VERSION "eCMPilot HS1 database-first 2026-10-28; PSA-RE 67f7581e7622410efdbb29c7eda3b86982b9b450; Apache-2.0"

NS_ :

BS_:

BU_: AAS ABS ARTIV AVAS BCP BSI BSM BVA CAV CMM CSS CVM DAE DMTR ESM E_VCU HCU1 HCU2 LVNSD MCM MDS RBG SBW VCU

BO_ 166 E_VCU_WheelPulseCounters: 2 E_VCU
 SG_ ImmoEcuState : 15|8@0+ (1,0) [0|255] ""  BSI
 SG_ ImmoLocalIdMcuBsi : 7|8@0+ (1,0) [0|255] ""  BSI

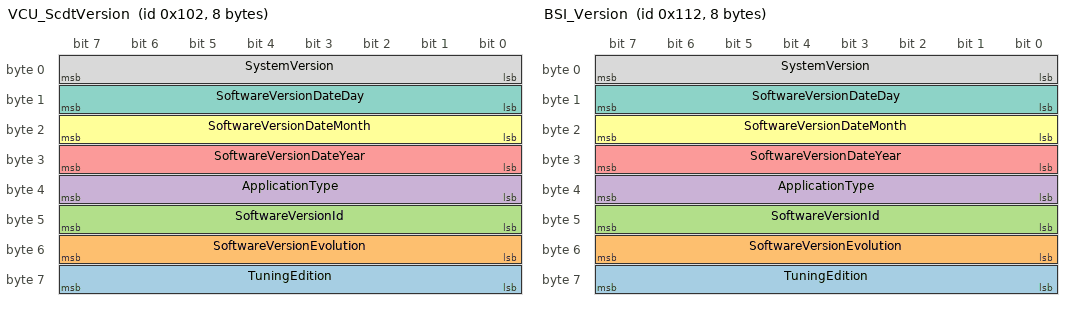
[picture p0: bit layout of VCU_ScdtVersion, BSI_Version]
BO_ 258 VCU_ScdtVersion: 8 VCU
 SG_ TuningEdition : 63|8@0+ (1,0) [0|255] "" Vector__XXX
 SG_ SoftwareVersionEvolution : 55|8@0+ (1,0) [0|255] "" Vector__XXX
 SG_ SoftwareVersionId : 47|8@0+ (1,0) [0|255] "" Vector__XXX
 SG_ ApplicationType : 39|8@0+ (1,0) [0|255] "" Vector__XXX
 SG_ SoftwareVersionDateYear : 31|8@0+ (1,0) [0|99] "" Vector__XXX
 SG_ SoftwareVersionDateMonth : 23|8@0+ (1,0) [0|12] "" Vector__XXX
 SG_ SoftwareVersionDateDay : 15|8@0+ (1,0) [0|31] "" Vector__XXX
 SG_ SystemVersion : 7|8@0+ (1,0) [0|255] "" Vector__XXX

BO_ 274 BSI_Version: 8 BSI
 SG_ TuningEdition : 63|8@0+ (1,0) [0|255] "" Vector__XXX
 SG_ SoftwareVersionEvolution : 55|8@0+ (1,0) [0|255] "" Vector__XXX
 SG_ SoftwareVersionId : 47|8@0+ (1,0) [0|255] "" Vector__XXX
 SG_ ApplicationType : 39|8@0+ (1,0) [0|255] "" Vector__XXX
 SG_ SoftwareVersionDateYear : 31|8@0+ (1,0) [0|99] "" Vector__XXX
 SG_ SoftwareVersionDateMonth : 23|8@0+ (1,0) [0|12] "" Vector__XXX
 SG_ SoftwareVersionDateDay : 15|8@0+ (1,0) [0|31] "" Vector__XXX
 SG_ SystemVersion : 7|8@0+ (1,0) [0|255] "" Vector__XXX

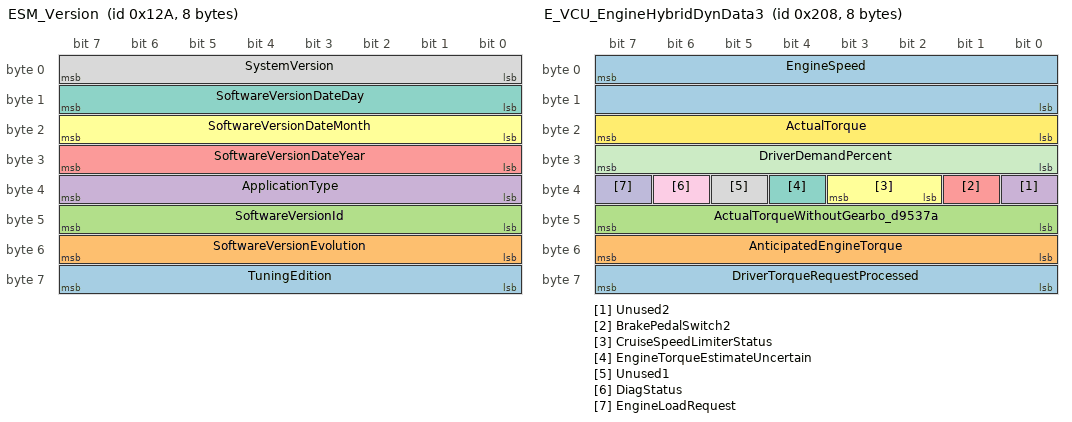
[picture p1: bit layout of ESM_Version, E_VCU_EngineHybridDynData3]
BO_ 298 ESM_Version: 8 ESM
 SG_ TuningEdition : 63|8@0+ (1,0) [0|255] "" Vector__XXX
 SG_ SoftwareVersionEvolution : 55|8@0+ (1,0) [0|255] "" Vector__XXX
 SG_ SoftwareVersionId : 47|8@0+ (1,0) [0|255] "" Vector__XXX
 SG_ ApplicationType : 39|8@0+ (1,0) [0|255] "" Vector__XXX
 SG_ SoftwareVersionDateYear : 31|8@0+ (1,0) [0|99] "" Vector__XXX
 SG_ SoftwareVersionDateMonth : 23|8@0+ (1,0) [0|12] "" Vector__XXX
 SG_ SoftwareVersionDateDay : 15|8@0+ (1,0) [0|31] "" Vector__XXX
 SG_ SystemVersion : 7|8@0+ (1,0) [0|255] "" Vector__XXX

BO_ 520 E_VCU_EngineHybridDynData3: 8 E_VCU
 SG_ DriverTorqueRequestProcessed : 63|8@0+ (2,-100) [-100|408] "Nm"  BVA,BSI,AAS,CVM,DMTR,ABS,DAE,SBW,BCP,CSS,CAV,MDS
 SG_ AnticipatedEngineTorque : 55|8@0+ (2,-100) [-100|408] "Nm"  BVA,BSI,AAS,CVM,DMTR,ABS,DAE,SBW,BCP,CSS,CAV,MDS
 SG_ ActualTorqueWithoutGearbo_d9537a : 47|8@0+ (2,-100) [-100|408] "Nm"  BVA,BSI,AAS,CVM,DMTR,ABS,DAE,SBW,BCP,CSS,CAV,MDS
 SG_ Unused2 : 32|1@0+ (1,0) [0|1] ""  BVA,BSI,AAS,CVM,DMTR,ABS,DAE,SBW,BCP,CSS,CAV,MDS
 SG_ BrakePedalSwitch2 : 33|1@0+ (1,0) [0|1] ""  BVA,BSI,AAS,CVM,DMTR,ABS,DAE,SBW,BCP,CSS,CAV,MDS
 SG_ CruiseSpeedLimiterStatus : 35|2@0+ (1,0) [0|3] ""  BVA,BSI,AAS,CVM,DMTR,ABS,DAE,SBW,BCP,CSS,CAV,MDS
 SG_ EngineTorqueEstimateUncertain : 36|1@0+ (1,0) [0|1] ""  BVA,BSI,AAS,CVM,DMTR,ABS,DAE,SBW,BCP,CSS,CAV,MDS
 SG_ Unused1 : 37|1@0+ (1,0) [0|1] ""  BVA,BSI,AAS,CVM,DMTR,ABS,DAE,SBW,BCP,CSS,CAV,MDS
 SG_ DiagStatus : 38|1@0+ (1,0) [0|1] ""  BVA,BSI,AAS,CVM,DMTR,ABS,DAE,SBW,BCP,CSS,CAV,MDS
 SG_ EngineLoadRequest : 39|1@0+ (1,0) [0|1] ""  BVA,BSI,AAS,CVM,DMTR,ABS,DAE,SBW,BCP,CSS,CAV,MDS
 SG_ DriverDemandPercent : 31|8@0+ (0.5,0) [0|100] "%"  BVA,BSI,AAS,CVM,DMTR,ABS,DAE,SBW,BCP,CSS,CAV,MDS
 SG_ ActualTorque : 23|8@0+ (2,-100) [-100|408] "Nm"  BVA,BSI,AAS,CVM,DMTR,ABS,DAE,SBW,BCP,CSS,CAV,MDS
 SG_ EngineSpeed : 7|16@0+ (0.125,0) [0|8191.75] "rpm"  BVA,BSI,AAS,CVM,DMTR,ABS,DAE,SBW,BCP,CSS,CAV,MDS

BO_ 602 Unknown_Message01: 2 Vector__XXX
 SG_ RawByte2 : 15|8@0+ (1,0) [0|255] "raw" Vector__XXX
 SG_ RawByte1 : 7|8@0+ (1,0) [0|255] "raw" Vector__XXX

BO_ 610 VCU_PowertrainState2: 1 VCU
 SG_ Unused1 : 3|4@0+ (1,0) [0|15] ""  AAS,CSS,BSI,LVNSD,MDS
 SG_ PowertrainState : 7|4@0+ (1,0) [0|15] ""  AAS,CSS,BSI,LVNSD,MDS

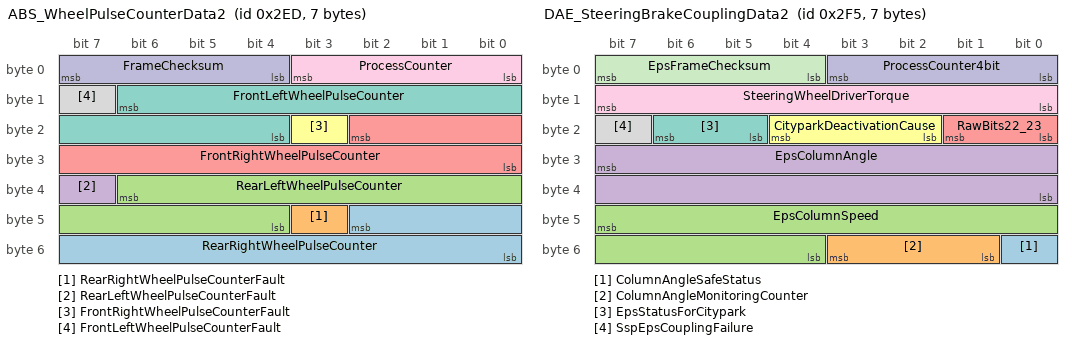
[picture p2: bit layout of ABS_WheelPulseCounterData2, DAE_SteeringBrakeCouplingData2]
BO_ 749 ABS_WheelPulseCounterData2: 7 ABS
 SG_ RearRightWheelPulseCounter : 42|11@0+ (1,0) [0|2047] ""  CVM,AAS,BSI
 SG_ RearRightWheelPulseCounterFault : 43|1@0+ (1,0) [0|1] ""  CVM,AAS,BSI
 SG_ RearLeftWheelPulseCounter : 38|11@0+ (1,0) [0|2047] ""  CVM,AAS,BSI
 SG_ RearLeftWheelPulseCounterFault : 39|1@0+ (1,0) [0|1] ""  CVM,AAS,BSI
 SG_ FrontRightWheelPulseCounter : 18|11@0+ (1,0) [0|2047] ""  CVM,AAS,BSI
 SG_ FrontRightWheelPulseCounterFault : 19|1@0+ (1,0) [0|1] ""  CVM,AAS,BSI
 SG_ FrontLeftWheelPulseCounter : 14|11@0+ (1,0) [0|2047] ""  CVM,AAS,BSI
 SG_ FrontLeftWheelPulseCounterFault : 15|1@0+ (1,0) [0|1] ""  CVM,AAS,BSI
 SG_ ProcessCounter : 3|4@0+ (1,0) [0|15] ""  CVM,AAS,BSI
 SG_ FrameChecksum : 7|4@0+ (1,0) [0|15] ""  CVM,AAS,BSI

BO_ 757 DAE_SteeringBrakeCouplingData2: 7 DAE
 SG_ ColumnAngleSafeStatus : 48|1@0+ (1,0) [0|1] ""  ABS,AAS,BSI
 SG_ ColumnAngleMonitoringCounter : 51|3@0+ (1,0) [0|7] ""  ABS,AAS,BSI
 SG_ EpsColumnSpeed : 47|12@0- (1,0) [-2000|2000] "°/s"  ABS,AAS,BSI
 SG_ EpsColumnAngle : 31|16@0- (0.1,0) [-1630|1630] "°"  ABS,AAS,BSI
 SG_ RawBits22_23 : 17|2@0+ (1,0) [0|3] "raw"  ABS,AAS,BSI
 SG_ CityparkDeactivationCause : 20|3@0+ (1,0) [0|7] ""  ABS,AAS,BSI
 SG_ EpsStatusForCitypark : 22|2@0+ (1,0) [0|3] ""  ABS,AAS,BSI
 SG_ SspEpsCouplingFailure : 23|1@0+ (1,0) [0|1] ""  ABS,AAS,BSI
 SG_ SteeringWheelDriverTorque : 15|8@0- (0.1,0) [-10|10] "Nm"  ABS,AAS,BSI
 SG_ ProcessCounter4bit : 3|4@0+ (1,0) [0|15] ""  ABS,AAS,BSI
 SG_ EpsFrameChecksum : 7|4@0+ (1,0) [0|15] ""  ABS,AAS,BSI

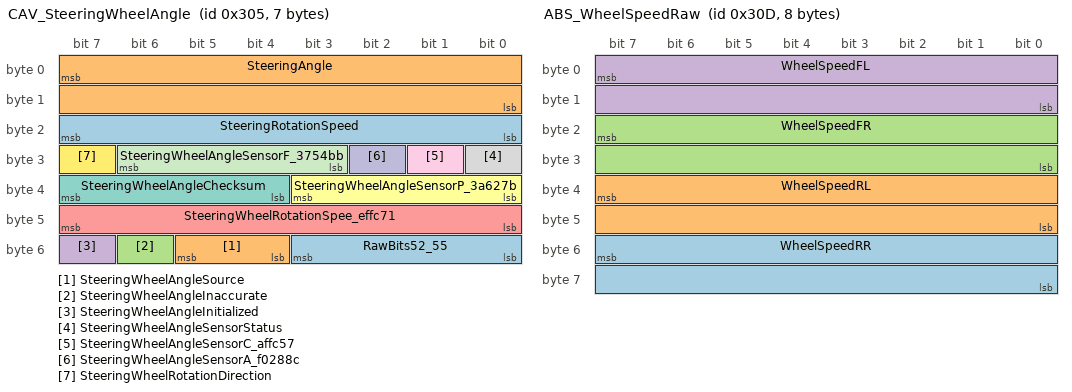
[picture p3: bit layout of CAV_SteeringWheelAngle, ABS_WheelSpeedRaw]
BO_ 773 CAV_SteeringWheelAngle: 7 CAV
 SG_ RawBits52_55 : 51|4@0+ (1,0) [0|15] "raw"  BCP,CVM,ABS,DAE,AAS,BSI,BVA,CMM,BSM,E_VCU
 SG_ SteeringWheelAngleSource : 53|2@0+ (1,0) [0|3] ""  BCP,CVM,ABS,DAE,AAS,BSI,BVA,CMM,BSM,E_VCU
 SG_ SteeringWheelAngleInaccurate : 54|1@0+ (1,0) [0|1] ""  BCP,CVM,ABS,DAE,AAS,BSI,BVA,CMM,BSM,E_VCU
 SG_ SteeringWheelAngleInitialized : 55|1@0+ (1,0) [0|1] ""  BCP,CVM,ABS,DAE,AAS,BSI,BVA,CMM,BSM,E_VCU
 SG_ SteeringWheelRotationSpee_effc71 : 47|8@0+ (4,0) [0|1016] "°/s"  BCP,CVM,ABS,DAE,AAS,BSI,BVA,CMM,BSM,E_VCU
 SG_ SteeringWheelAngleSensorP_3a627b : 35|4@0+ (1,0) [0|15] ""  BCP,CVM,ABS,DAE,AAS,BSI,BVA,CMM,BSM,E_VCU
 SG_ SteeringWheelAngleChecksum : 39|4@0+ (1,0) [0|15] ""  BCP,CVM,ABS,DAE,AAS,BSI,BVA,CMM,BSM,E_VCU
 SG_ SteeringWheelAngleSensorStatus : 24|1@0+ (1,0) [0|1] ""  BCP,CVM,ABS,DAE,AAS,BSI,BVA,CMM,BSM,E_VCU
 SG_ SteeringWheelAngleSensorC_affc57 : 25|1@0+ (1,0) [0|1] ""  BCP,CVM,ABS,DAE,AAS,BSI,BVA,CMM,BSM,E_VCU
 SG_ SteeringWheelAngleSensorA_f0288c : 26|1@0+ (1,0) [0|1] ""  BCP,CVM,ABS,DAE,AAS,BSI,BVA,CMM,BSM,E_VCU
 SG_ SteeringWheelAngleSensorF_3754bb : 30|4@0+ (1,0) [0|15] ""  BCP,CVM,ABS,DAE,AAS,BSI,BVA,CMM,BSM,E_VCU
 SG_ SteeringWheelRotationDirection : 31|1@0+ (1,0) [0|1] ""  BCP,CVM,ABS,DAE,AAS,BSI,BVA,CMM,BSM,E_VCU
 SG_ SteeringRotationSpeed : 23|8@0+ (4,0) [0|1016] "°/s"  BCP,CVM,ABS,DAE,AAS,BSI,BVA,CMM,BSM,E_VCU
 SG_ SteeringAngle : 7|16@0- (0.1,0) [-780|780] "°"  BCP,CVM,ABS,DAE,AAS,BSI,BVA,CMM,BSM,E_VCU

BO_ 781 ABS_WheelSpeedRaw: 8 ABS
 SG_ WheelSpeedRR : 55|16@0+ (0.01,0) [0|655.33] "km/h"  CVM,AAS,CMM,BVA,HCU1,BSM,DAE,VCU
 SG_ WheelSpeedRL : 39|16@0+ (0.01,0) [0|655.33] "km/h"  CVM,AAS,CMM,BVA,HCU1,BSM,DAE,VCU
 SG_ WheelSpeedFR : 23|16@0+ (0.01,0) [0|655.33] "km/h"  CVM,AAS,CMM,BVA,HCU1,BSM,DAE,VCU
 SG_ WheelSpeedFL : 7|16@0+ (0.01,0) [0|655.33] "km/h"  CVM,AAS,CMM,BVA,HCU1,BSM,DAE,VCU

BO_ 820 E_VCU_BattCellVoltages: 8 E_VCU
 SG_ RawByte8_Mux27_28_29_30_31 m27 : 63|8@0+ (1,0) [0|255] "raw"  BSI,MDS
 SG_ CellVoltage044 m10 : 53|14@0+ (0.001,0) [0|15] "V"  BSI,MDS
 SG_ CellVoltage040 m9 : 53|14@0+ (0.001,0) [0|15] "V"  BSI,MDS
 SG_ CellVoltage092 m22 : 53|14@0+ (0.001,0) [0|15] "V"  BSI,MDS
 SG_ CellVoltage020 m4 : 53|14@0+ (0.001,0) [0|15] "V"  BSI,MDS
 SG_ CellVoltage088 m21 : 53|14@0+ (0.001,0) [0|15] "V"  BSI,MDS
 SG_ CellVoltage108 m26 : 53|14@0+ (0.001,0) [0|15] "V"  BSI,MDS
 SG_ CellVoltage104 m25 : 53|14@0+ (0.001,0) [0|15] "V"  BSI,MDS
 SG_ CellVoltage068 m16 : 53|14@0+ (0.001,0) [0|15] "V"  BSI,MDS
 SG_ CellVoltage064 m15 : 53|14@0+ (0.001,0) [0|15] "V"  BSI,MDS
 SG_ CellVoltage016 m3 : 53|14@0+ (0.001,0) [0|15] "V"  BSI,MDS
 SG_ CellVoltage072 m17 : 53|14@0+ (0.001,0) [0|15] "V"  BSI,MDS
 SG_ CellVoltage060 m14 : 53|14@0+ (0.001,0) [0|15] "V"  BSI,MDS
 SG_ CellVoltage056 m13 : 53|14@0+ (0.001,0) [0|15] "V"  BSI,MDS
 SG_ CellVoltage084 m20 : 53|14@0+ (0.001,0) [0|15] "V"  BSI,MDS
 SG_ CellVoltage004 m0 : 53|14@0+ (0.001,0) [0|15] "V"  BSI,MDS
 SG_ CellVoltage052 m12 : 53|14@0+ (0.001,0) [0|15] "V"  BSI,MDS
 SG_ CellVoltage012 m2 : 53|14@0+ (0.001,0) [0|15] "V"  BSI,MDS
 SG_ CellVoltage008 m1 : 53|14@0+ (0.001,0) [0|15] "V"  BSI,MDS
 SG_ CellVoltage048 m11 : 53|14@0+ (0.001,0) [0|15] "V"  BSI,MDS
 SG_ CellVoltage080 m19 : 53|14@0+ (0.001,0) [0|15] "V"  BSI,MDS
 SG_ CellVoltage036 m8 : 53|14@0+ (0.001,0) [0|15] "V"  BSI,MDS
 SG_ CellVoltage076 m18 : 53|14@0+ (0.001,0) [0|15] "V"  BSI,MDS
 SG_ CellVoltage100 m24 : 53|14@0+ (0.001,0) [0|15] "V"  BSI,MDS
 SG_ CellVoltage096 m23 : 53|14@0+ (0.001,0) [0|15] "V"  BSI,MDS
 SG_ CellVoltage032 m7 : 53|14@0+ (0.001,0) [0|15] "V"  BSI,MDS
 SG_ CellVoltage028 m6 : 53|14@0+ (0.001,0) [0|15] "V"  BSI,MDS
 SG_ CellVoltage024 m5 : 53|14@0+ (0.001,0) [0|15] "V"  BSI,MDS
 SG_ RawByte7_Mux27_28_29_30_31 m27 : 55|8@0+ (1,0) [0|255] "raw"  BSI,MDS
 SG_ RawByte6_Mux27_28_29_30_31 m27 : 47|8@0+ (1,0) [0|255] "raw"  BSI,MDS
 SG_ CellVoltage031 m7 : 35|14@0+ (0.001,0) [0|15] "V"  BSI,MDS
 SG_ CellVoltage043 m10 : 35|14@0+ (0.001,0) [0|15] "V"  BSI,MDS
 SG_ CellVoltage091 m22 : 35|14@0+ (0.001,0) [0|15] "V"  BSI,MDS
 SG_ CellVoltage019 m4 : 35|14@0+ (0.001,0) [0|15] "V"  BSI,MDS
 SG_ CellVoltage087 m21 : 35|14@0+ (0.001,0) [0|15] "V"  BSI,MDS
 SG_ CellVoltage107 m26 : 35|14@0+ (0.001,0) [0|15] "V"  BSI,MDS
 SG_ CellVoltage067 m16 : 35|14@0+ (0.001,0) [0|15] "V"  BSI,MDS
 SG_ CellVoltage063 m15 : 35|14@0+ (0.001,0) [0|15] "V"  BSI,MDS
 SG_ CellVoltage015 m3 : 35|14@0+ (0.001,0) [0|15] "V"  BSI,MDS
 SG_ CellVoltage071 m17 : 35|14@0+ (0.001,0) [0|15] "V"  BSI,MDS
 SG_ CellVoltage059 m14 : 35|14@0+ (0.001,0) [0|15] "V"  BSI,MDS
 SG_ CellVoltage083 m20 : 35|14@0+ (0.001,0) [0|15] "V"  BSI,MDS
 SG_ CellVoltage007 m1 : 35|14@0+ (0.001,0) [0|15] "V"  BSI,MDS
 SG_ CellVoltage051 m12 : 35|14@0+ (0.001,0) [0|15] "V"  BSI,MDS
 SG_ CellVoltage039 m9 : 35|14@0+ (0.001,0) [0|15] "V"  BSI,MDS
 SG_ CellVoltage011 m2 : 35|14@0+ (0.001,0) [0|15] "V"  BSI,MDS
 SG_ CellVoltage079 m19 : 35|14@0+ (0.001,0) [0|15] "V"  BSI,MDS
 SG_ CellVoltage035 m8 : 35|14@0+ (0.001,0) [0|15] "V"  BSI,MDS
 SG_ CellVoltage003 m0 : 35|14@0+ (0.001,0) [0|15] "V"  BSI,MDS
 SG_ CellVoltage055 m13 : 35|14@0+ (0.001,0) [0|15] "V"  BSI,MDS
 SG_ CellVoltage023 m5 : 35|14@0+ (0.001,0) [0|15] "V"  BSI,MDS
 SG_ CellVoltage075 m18 : 35|14@0+ (0.001,0) [0|15] "V"  BSI,MDS
 SG_ CellVoltage103 m25 : 35|14@0+ (0.001,0) [0|15] "V"  BSI,MDS
 SG_ CellVoltage099 m24 : 35|14@0+ (0.001,0) [0|15] "V"  BSI,MDS
 SG_ CellVoltage095 m23 : 35|14@0+ (0.001,0) [0|15] "V"  BSI,MDS
 SG_ CellVoltage047 m11 : 35|14@0+ (0.001,0) [0|15] "V"  BSI,MDS
 SG_ CellVoltage027 m6 : 35|14@0+ (0.001,0) [0|15] "V"  BSI,MDS
 SG_ RawByte5_Mux27_28_29_30_31 m27 : 39|8@0+ (1,0) [0|255] "raw"  BSI,MDS
 SG_ RawByte4_Mux27_28_29_30_31 m27 : 31|8@0+ (1,0) [0|255] "raw"  BSI,MDS
 SG_ CellVoltage030 m7 : 17|14@0+ (0.001,0) [0|15] "V"  BSI,MDS
 SG_ CellVoltage042 m10 : 17|14@0+ (0.001,0) [0|15] "V"  BSI,MDS
 SG_ CellVoltage022 m5 : 17|14@0+ (0.001,0) [0|15] "V"  BSI,MDS
 SG_ CellVoltage018 m4 : 17|14@0+ (0.001,0) [0|15] "V"  BSI,MDS
 SG_ CellVoltage090 m22 : 17|14@0+ (0.001,0) [0|15] "V"  BSI,MDS
 SG_ CellVoltage106 m26 : 17|14@0+ (0.001,0) [0|15] "V"  BSI,MDS
 SG_ CellVoltage066 m16 : 17|14@0+ (0.001,0) [0|15] "V"  BSI,MDS
 SG_ CellVoltage014 m3 : 17|14@0+ (0.001,0) [0|15] "V"  BSI,MDS
 SG_ CellVoltage074 m18 : 17|14@0+ (0.001,0) [0|15] "V"  BSI,MDS
 SG_ CellVoltage070 m17 : 17|14@0+ (0.001,0) [0|15] "V"  BSI,MDS
 SG_ CellVoltage062 m15 : 17|14@0+ (0.001,0) [0|15] "V"  BSI,MDS
 SG_ CellVoltage058 m14 : 17|14@0+ (0.001,0) [0|15] "V"  BSI,MDS
 SG_ CellVoltage086 m21 : 17|14@0+ (0.001,0) [0|15] "V"  BSI,MDS
 SG_ CellVoltage006 m1 : 17|14@0+ (0.001,0) [0|15] "V"  BSI,MDS
 SG_ CellVoltage054 m13 : 17|14@0+ (0.001,0) [0|15] "V"  BSI,MDS
 SG_ CellVoltage050 m12 : 17|14@0+ (0.001,0) [0|15] "V"  BSI,MDS
 SG_ CellVoltage038 m9 : 17|14@0+ (0.001,0) [0|15] "V"  BSI,MDS
 SG_ CellVoltage010 m2 : 17|14@0+ (0.001,0) [0|15] "V"  BSI,MDS
 SG_ CellVoltage082 m20 : 17|14@0+ (0.001,0) [0|15] "V"  BSI,MDS
 SG_ CellVoltage094 m23 : 17|14@0+ (0.001,0) [0|15] "V"  BSI,MDS
 SG_ CellVoltage034 m8 : 17|14@0+ (0.001,0) [0|15] "V"  BSI,MDS
 SG_ CellVoltage002 m0 : 17|14@0+ (0.001,0) [0|15] "V"  BSI,MDS
 SG_ CellVoltage078 m19 : 17|14@0+ (0.001,0) [0|15] "V"  BSI,MDS
 SG_ CellVoltage102 m25 : 17|14@0+ (0.001,0) [0|15] "V"  BSI,MDS
 SG_ CellVoltage098 m24 : 17|14@0+ (0.001,0) [0|15] "V"  BSI,MDS
 SG_ CellVoltage046 m11 : 17|14@0+ (0.001,0) [0|15] "V"  BSI,MDS
 SG_ CellVoltage026 m6 : 17|14@0+ (0.001,0) [0|15] "V"  BSI,MDS
 SG_ RawByte3_Mux27_28_29_30_31 m27 : 23|8@0+ (1,0) [0|255] "raw"  BSI,MDS
 SG_ RawByte2_Mux27_28_29_30_31 m27 : 15|8@0+ (1,0) [0|255] "raw"  BSI,MDS
 SG_ CellVoltage029 m7 : 15|14@0+ (0.001,0) [0|15] "V"  BSI,MDS
 SG_ CellVoltage041 m10 : 15|14@0+ (0.001,0) [0|15] "V"  BSI,MDS
 SG_ CellVoltage021 m5 : 15|14@0+ (0.001,0) [0|15] "V"  BSI,MDS
 SG_ CellVoltage069 m17 : 15|14@0+ (0.001,0) [0|15] "V"  BSI,MDS
 SG_ CellVoltage105 m26 : 15|14@0+ (0.001,0) [0|15] "V"  BSI,MDS
 SG_ CellVoltage065 m16 : 15|14@0+ (0.001,0) [0|15] "V"  BSI,MDS
 SG_ CellVoltage017 m4 : 15|14@0+ (0.001,0) [0|15] "V"  BSI,MDS
 SG_ CellVoltage073 m18 : 15|14@0+ (0.001,0) [0|15] "V"  BSI,MDS
 SG_ CellVoltage061 m15 : 15|14@0+ (0.001,0) [0|15] "V"  BSI,MDS
 SG_ CellVoltage057 m14 : 15|14@0+ (0.001,0) [0|15] "V"  BSI,MDS
 SG_ CellVoltage085 m21 : 15|14@0+ (0.001,0) [0|15] "V"  BSI,MDS
 SG_ CellVoltage005 m1 : 15|14@0+ (0.001,0) [0|15] "V"  BSI,MDS
 SG_ CellVoltage053 m13 : 15|14@0+ (0.001,0) [0|15] "V"  BSI,MDS
 SG_ CellVoltage037 m9 : 15|14@0+ (0.001,0) [0|15] "V"  BSI,MDS
 SG_ CellVoltage013 m3 : 15|14@0+ (0.001,0) [0|15] "V"  BSI,MDS
 SG_ CellVoltage009 m2 : 15|14@0+ (0.001,0) [0|15] "V"  BSI,MDS
 SG_ CellVoltage049 m12 : 15|14@0+ (0.001,0) [0|15] "V"  BSI,MDS
 SG_ CellVoltage081 m20 : 15|14@0+ (0.001,0) [0|15] "V"  BSI,MDS
 SG_ CellVoltage093 m23 : 15|14@0+ (0.001,0) [0|15] "V"  BSI,MDS
 SG_ CellVoltage001 m0 : 15|14@0+ (0.001,0) [0|15] "V"  BSI,MDS
 SG_ CellVoltage089 m22 : 15|14@0+ (0.001,0) [0|15] "V"  BSI,MDS
 SG_ CellVoltage077 m19 : 15|14@0+ (0.001,0) [0|15] "V"  BSI,MDS
 SG_ CellVoltage101 m25 : 15|14@0+ (0.001,0) [0|15] "V"  BSI,MDS
 SG_ CellVoltage097 m24 : 15|14@0+ (0.001,0) [0|15] "V"  BSI,MDS
 SG_ CellVoltage033 m8 : 15|14@0+ (0.001,0) [0|15] "V"  BSI,MDS
 SG_ CellVoltage045 m11 : 15|14@0+ (0.001,0) [0|15] "V"  BSI,MDS
 SG_ CellVoltage025 m6 : 15|14@0+ (0.001,0) [0|15] "V"  BSI,MDS
 SG_ RawBits5_7 : 2|3@0+ (1,0) [0|7] "raw"  BSI,MDS
 SG_ CellGroup M : 7|5@0+ (1,0) [0|31] ""  BSI,MDS

BO_ 840 E_VCU_EngineEcuStatusHev: 8 E_VCU
 SG_ ProcessCounter : 59|4@0+ (1,0) [0|15] ""  ESM,ABS,DAE,BCP,BVA,BSI,AAS,LVNSD
 SG_ FrameChecksum : 63|4@0+ (1,0) [0|15] ""  ESM,ABS,DAE,BCP,BVA,BSI,AAS,LVNSD
 SG_ Unused6 : 48|1@0+ (1,0) [0|1] ""  ESM,ABS,DAE,BCP,BVA,BSI,AAS,LVNSD
 SG_ ObdFaultOnMilPresent : 49|1@0+ (1,0) [0|1] ""  ESM,ABS,DAE,BCP,BVA,BSI,AAS,LVNSD
 SG_ MilLampSteadyRequest : 50|1@0+ (1,0) [0|1] ""  ESM,ABS,DAE,BCP,BVA,BSI,AAS,LVNSD
 SG_ MilLampBlinkRequest : 51|1@0+ (1,0) [0|1] ""  ESM,ABS,DAE,BCP,BVA,BSI,AAS,LVNSD
 SG_ WarmUpCycleCompletedStatus : 52|1@0+ (1,0) [0|1] ""  ESM,ABS,DAE,BCP,BVA,BSI,AAS,LVNSD
 SG_ DrivingCycleGlobalSyncStatus : 53|1@0+ (1,0) [0|1] ""  ESM,ABS,DAE,BCP,BVA,BSI,AAS,LVNSD
 SG_ ObdIgnitionContact : 54|1@0+ (1,0) [0|1] ""  ESM,ABS,DAE,BCP,BVA,BSI,AAS,LVNSD
 SG_ Unused5 : 55|1@0+ (1,0) [0|1] ""  ESM,ABS,DAE,BCP,BVA,BSI,AAS,LVNSD
 SG_ EngineRunning : 43|4@0+ (1,0) [0|15] ""  ESM,ABS,DAE,BCP,BVA,BSI,AAS,LVNSD
 SG_ Unused4 : 44|1@0+ (1,0) [0|1] ""  ESM,ABS,DAE,BCP,BVA,BSI,AAS,LVNSD
 SG_ RearAsrMsrAcknowledge : 45|1@0+ (1,0) [0|1] ""  ESM,ABS,DAE,BCP,BVA,BSI,AAS,LVNSD
 SG_ Unused3 : 47|2@0+ (1,0) [0|3] ""  ESM,ABS,DAE,BCP,BVA,BSI,AAS,LVNSD
 SG_ AsrMsrAcknowledge : 32|1@0+ (1,0) [0|1] ""  ESM,ABS,DAE,BCP,BVA,BSI,AAS,LVNSD
 SG_ Unused2 : 31|15@0+ (1,0) [0|32767] ""  ESM,ABS,DAE,BCP,BVA,BSI,AAS,LVNSD
 SG_ CoolingSystemPressure2 : 23|8@0+ (11,110) [110|2904] "kPa"  ESM,ABS,DAE,BCP,BVA,BSI,AAS,LVNSD
 SG_ Unused1 : 7|16@0+ (1,0) [0|65535] ""  ESM,ABS,DAE,BCP,BVA,BSI,AAS,LVNSD

BO_ 841 BVA_GearboxSyncData2: 8 BVA
 SG_ EngineSpeedRegulationSetpoint : 63|8@0+ (25,750) [750|7075] "rpm"  CVM,AAS,CMM,ABS,SBW,BSM,BSI,ARTIV,MDS
 SG_ ProcessCounter : 51|4@0+ (1,0) [0|15] ""  CVM,AAS,CMM,ABS,SBW,BSM,BSI,ARTIV,MDS
 SG_ FrameChecksum : 55|4@0+ (1,0) [0|15] ""  CVM,AAS,CMM,ABS,SBW,BSM,BSI,ARTIV,MDS
 SG_ GearboxCouplingDeviceStatus : 41|2@0+ (1,0) [0|3] ""  CVM,AAS,CMM,ABS,SBW,BSM,BSI,ARTIV,MDS
 SG_ GearboxReductionState : 43|2@0+ (1,0) [0|3] ""  CVM,AAS,CMM,ABS,SBW,BSM,BSI,ARTIV,MDS
 SG_ GearboxMechanicallyEngagedGear : 47|4@0+ (1,0) [0|15] ""  CVM,AAS,CMM,ABS,SBW,BSM,BSI,ARTIV,MDS
 SG_ GearboxMaxAdmissibleTorque : 39|8@0+ (2,-100) [-100|408] "Nm"  CVM,AAS,CMM,ABS,SBW,BSM,BSI,ARTIV,MDS
 SG_ GearPosition : 27|4@0+ (1,0) [0|15] ""  CVM,AAS,CMM,ABS,SBW,BSM,BSI,ARTIV,MDS
 SG_ GearboxTargetGear : 31|4@0+ (1,0) [0|15] ""  CVM,AAS,CMM,ABS,SBW,BSM,BSI,ARTIV,MDS
 SG_ GearShiftInProgress : 16|1@0+ (1,0) [0|1] ""  CVM,AAS,CMM,ABS,SBW,BSM,BSI,ARTIV,MDS
 SG_ TractionChainStateChangePhase : 17|1@0+ (1,0) [0|1] ""  CVM,AAS,CMM,ABS,SBW,BSM,BSI,ARTIV,MDS
 SG_ GearboxTorqueConverterStatus : 19|2@0+ (1,0) [0|3] ""  CVM,AAS,CMM,ABS,SBW,BSM,BSI,ARTIV,MDS
 SG_ AcCompressorInhibitGearshift : 20|1@0+ (1,0) [0|1] ""  CVM,AAS,CMM,ABS,SBW,BSM,BSI,ARTIV,MDS
 SG_ EngineSpeedRegulationRequest : 21|1@0+ (1,0) [0|1] ""  CVM,AAS,CMM,ABS,SBW,BSM,BSI,ARTIV,MDS
 SG_ EngineSpeedRelaunchType : 22|1@0+ (1,0) [0|1] ""  CVM,AAS,CMM,ABS,SBW,BSM,BSI,ARTIV,MDS
 SG_ IdleSpeedIncreaseRequest : 23|1@0+ (1,0) [0|1] ""  CVM,AAS,CMM,ABS,SBW,BSM,BSI,ARTIV,MDS
 SG_ GearboxTorqueRequestSetpoint : 15|8@0+ (2,-100) [-100|408] "Nm"  CVM,AAS,CMM,ABS,SBW,BSM,BSI,ARTIV,MDS
 SG_ GearboxDragReductionStatus : 1|2@0+ (1,0) [0|3] ""  CVM,AAS,CMM,ABS,SBW,BSM,BSI,ARTIV,MDS
 SG_ GearShiftInProgressType : 4|3@0+ (1,0) [0|7] ""  CVM,AAS,CMM,ABS,SBW,BSM,BSI,ARTIV,MDS
 SG_ EngineTorqueTransmissionStatus : 5|1@0+ (1,0) [0|1] ""  CVM,AAS,CMM,ABS,SBW,BSM,BSI,ARTIV,MDS
 SG_ RawBits1_1 : 6|1@0+ (1,0) [0|1] "raw"  CVM,AAS,CMM,ABS,SBW,BSM,BSI,ARTIV,MDS
 SG_ AcCompressorCutoffRequestGearbox : 7|1@0+ (1,0) [0|1] ""  CVM,AAS,CMM,ABS,SBW,BSM,BSI,ARTIV,MDS

BO_ 845 ABS_EspSyncData: 8 ABS
 SG_ StaticSlope : 61|6@0+ (1,-30) [-30|30] "%"  CVM,MCM,BSM,DAE,CMM,BVA,BSI,AAS,HCU1
 SG_ Unused5 : 63|2@0+ (1,0) [0|3] ""  CVM,MCM,BSM,DAE,CMM,BVA,BSI,AAS,HCU1
 SG_ Unused4 : 48|1@0+ (1,0) [0|1] ""  CVM,MCM,BSM,DAE,CMM,BVA,BSI,AAS,HCU1
 SG_ BasrRegulationActive : 49|1@0+ (1,0) [0|1] ""  CVM,MCM,BSM,DAE,CMM,BVA,BSI,AAS,HCU1
 SG_ AsrRegulationActive : 50|1@0+ (1,0) [0|1] ""  CVM,MCM,BSM,DAE,CMM,BVA,BSI,AAS,HCU1
 SG_ MsrRegulationActive : 51|1@0+ (1,0) [0|1] ""  CVM,MCM,BSM,DAE,CMM,BVA,BSI,AAS,HCU1
 SG_ EspRegulationActive : 52|1@0+ (1,0) [0|1] ""  CVM,MCM,BSM,DAE,CMM,BVA,BSI,AAS,HCU1
 SG_ AfuRegulationActive : 53|1@0+ (1,0) [0|1] ""  CVM,MCM,BSM,DAE,CMM,BVA,BSI,AAS,HCU1
 SG_ Unused3 : 54|1@0+ (1,0) [0|1] ""  CVM,MCM,BSM,DAE,CMM,BVA,BSI,AAS,HCU1
 SG_ AsrEspRegulationLampRequest : 55|1@0+ (1,0) [0|1] ""  CVM,MCM,BSM,DAE,CMM,BVA,BSI,AAS,HCU1
 SG_ ProcessCounter4bit : 43|4@0+ (1,0) [0|15] ""  CVM,MCM,BSM,DAE,CMM,BVA,BSI,AAS,HCU1
 SG_ Unused2 : 44|1@0+ (1,0) [0|1] ""  CVM,MCM,BSM,DAE,CMM,BVA,BSI,AAS,HCU1
 SG_ HillAssistStatus : 46|2@0+ (1,0) [0|3] ""  CVM,MCM,BSM,DAE,CMM,BVA,BSI,AAS,HCU1
 SG_ Unused1 : 47|1@0+ (1,0) [0|1] ""  CVM,MCM,BSM,DAE,CMM,BVA,BSI,AAS,HCU1
 SG_ MsrTorqueSetpoint : 39|8@0+ (2,-100) [-100|400] "Nm"  CVM,MCM,BSM,DAE,CMM,BVA,BSI,AAS,HCU1
 SG_ AsrDynamicTorqueSetpoint : 31|8@0+ (2,-100) [-100|400] "Nm"  CVM,MCM,BSM,DAE,CMM,BVA,BSI,AAS,HCU1
 SG_ AsrStaticTorqueSetpoint : 23|8@0+ (2,-100) [-100|400] "Nm"  CVM,MCM,BSM,DAE,CMM,BVA,BSI,AAS,HCU1
 SG_ GearChangeAuthorization : 9|2@0+ (1,0) [0|3] ""  CVM,MCM,BSM,DAE,CMM,BVA,BSI,AAS,HCU1
 SG_ BrakePrefillActive : 10|1@0+ (1,0) [0|1] ""  CVM,MCM,BSM,DAE,CMM,BVA,BSI,AAS,HCU1
 SG_ FarcDecelerationFunctionStatus : 12|2@0+ (1,0) [0|3] ""  CVM,MCM,BSM,DAE,CMM,BVA,BSI,AAS,HCU1
 SG_ AsrPlusMode : 15|3@0+ (1,0) [0|7] ""  CVM,MCM,BSM,DAE,CMM,BVA,BSI,AAS,HCU1
 SG_ EspTorqueRequestStatus : 2|3@0+ (1,0) [0|7] ""  CVM,MCM,BSM,DAE,CMM,BVA,BSI,AAS,HCU1
 SG_ AsrDisconnectStatus : 3|1@0+ (1,0) [0|1] ""  CVM,MCM,BSM,DAE,CMM,BVA,BSI,AAS,HCU1
 SG_ AsrEspFaultLampRequest : 4|1@0+ (1,0) [0|1] ""  CVM,MCM,BSM,DAE,CMM,BVA,BSI,AAS,HCU1
 SG_ GearboxVdcProgramRequest : 5|1@0+ (1,0) [0|1] ""  CVM,MCM,BSM,DAE,CMM,BVA,BSI,AAS,HCU1
 SG_ AsrEspRegulationActive : 6|1@0+ (1,0) [0|1] ""  CVM,MCM,BSM,DAE,CMM,BVA,BSI,AAS,HCU1
 SG_ AsrEspDisconnectStatus : 7|1@0+ (1,0) [0|1] ""  CVM,MCM,BSM,DAE,CMM,BVA,BSI,AAS,HCU1

BO_ 850 Unknown_Message02: 2 Vector__XXX
 SG_ RawByte2 : 15|8@0+ (1,0) [0|255] "raw" Vector__XXX
 SG_ RawByte1 : 7|8@0+ (1,0) [0|255] "raw" Vector__XXX

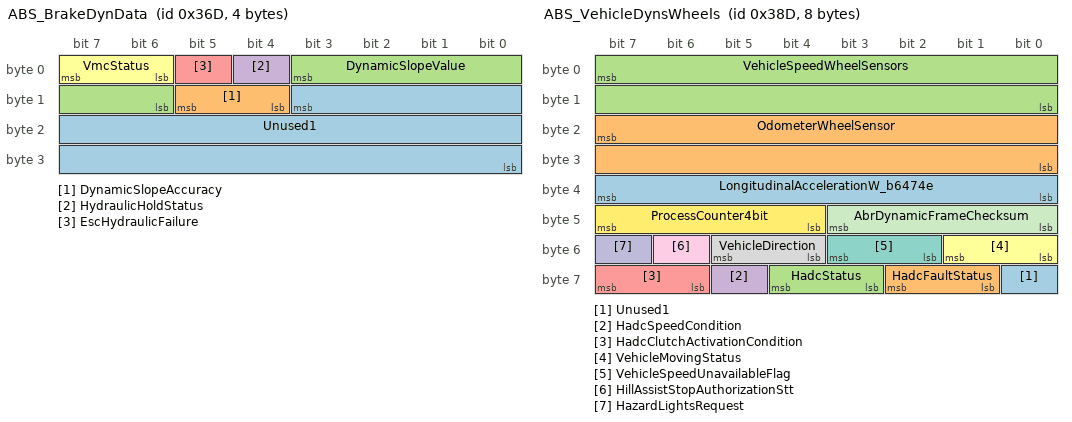
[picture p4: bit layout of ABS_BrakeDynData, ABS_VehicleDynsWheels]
BO_ 877 ABS_BrakeDynData: 4 ABS
 SG_ Unused1 : 11|20@0+ (1,0) [0|1048575] ""  AAS
 SG_ DynamicSlopeAccuracy : 13|2@0+ (1,0) [0|3] ""  AAS
 SG_ DynamicSlopeValue : 3|6@0+ (1,-30) [-30|30] "%"  AAS
 SG_ HydraulicHoldStatus : 4|1@0+ (1,0) [0|1] ""  AAS
 SG_ EscHydraulicFailure : 5|1@0+ (1,0) [0|1] ""  AAS
 SG_ VmcStatus : 7|2@0+ (1,0) [0|3] ""  AAS

BO_ 909 ABS_VehicleDynsWheels: 8 ABS
 SG_ Unused1 : 56|1@0+ (1,0) [0|1] ""  BCP,VCU,CVM,BSM,DAE,CSS,CMM,BVA,BSI,AAS,HCU1,E_VCU,SBW
 SG_ HadcFaultStatus : 58|2@0+ (1,0) [0|3] ""  BCP,VCU,CVM,BSM,DAE,CSS,CMM,BVA,BSI,AAS,HCU1,E_VCU,SBW
 SG_ HadcStatus : 60|2@0+ (1,0) [0|3] ""  BCP,VCU,CVM,BSM,DAE,CSS,CMM,BVA,BSI,AAS,HCU1,E_VCU,SBW
 SG_ HadcSpeedCondition : 61|1@0+ (1,0) [0|1] ""  BCP,VCU,CVM,BSM,DAE,CSS,CMM,BVA,BSI,AAS,HCU1,E_VCU,SBW
 SG_ HadcClutchActivationCondition : 63|2@0+ (1,0) [0|3] ""  BCP,VCU,CVM,BSM,DAE,CSS,CMM,BVA,BSI,AAS,HCU1,E_VCU,SBW
 SG_ VehicleMovingStatus : 49|2@0+ (1,0) [0|3] ""  BCP,VCU,CVM,BSM,DAE,CSS,CMM,BVA,BSI,AAS,HCU1,E_VCU,SBW
 SG_ VehicleSpeedUnavailableFlag : 51|2@0+ (1,0) [0|3] ""  BCP,VCU,CVM,BSM,DAE,CSS,CMM,BVA,BSI,AAS,HCU1,E_VCU,SBW
 SG_ VehicleDirection : 53|2@0+ (1,0) [0|3] ""  BCP,VCU,CVM,BSM,DAE,CSS,CMM,BVA,BSI,AAS,HCU1,E_VCU,SBW
 SG_ HillAssistStopAuthorizationStt : 54|1@0+ (1,0) [0|1] ""  BCP,VCU,CVM,BSM,DAE,CSS,CMM,BVA,BSI,AAS,HCU1,E_VCU,SBW
 SG_ HazardLightsRequest : 55|1@0+ (1,0) [0|1] ""  BCP,VCU,CVM,BSM,DAE,CSS,CMM,BVA,BSI,AAS,HCU1,E_VCU,SBW
 SG_ AbrDynamicFrameChecksum : 43|4@0+ (1,0) [0|15] ""  BCP,VCU,CVM,BSM,DAE,CSS,CMM,BVA,BSI,AAS,HCU1,E_VCU,SBW
 SG_ ProcessCounter4bit : 47|4@0+ (1,0) [0|15] ""  BCP,VCU,CVM,BSM,DAE,CSS,CMM,BVA,BSI,AAS,HCU1,E_VCU,SBW
 SG_ LongitudinalAccelerationW_b6474e : 39|8@0+ (0.08,-14) [-14|6.32] "m/s2"  BCP,VCU,CVM,BSM,DAE,CSS,CMM,BVA,BSI,AAS,HCU1,E_VCU,SBW
 SG_ OdometerWheelSensor : 23|16@0+ (0.1,0) [0|6553.5] "m"  BCP,VCU,CVM,BSM,DAE,CSS,CMM,BVA,BSI,AAS,HCU1,E_VCU,SBW
 SG_ VehicleSpeedWheelSensors : 7|16@0+ (0.01,0) [0|655.34] "km/h"  BCP,VCU,CVM,BSM,DAE,CSS,CMM,BVA,BSI,AAS,HCU1,E_VCU,SBW

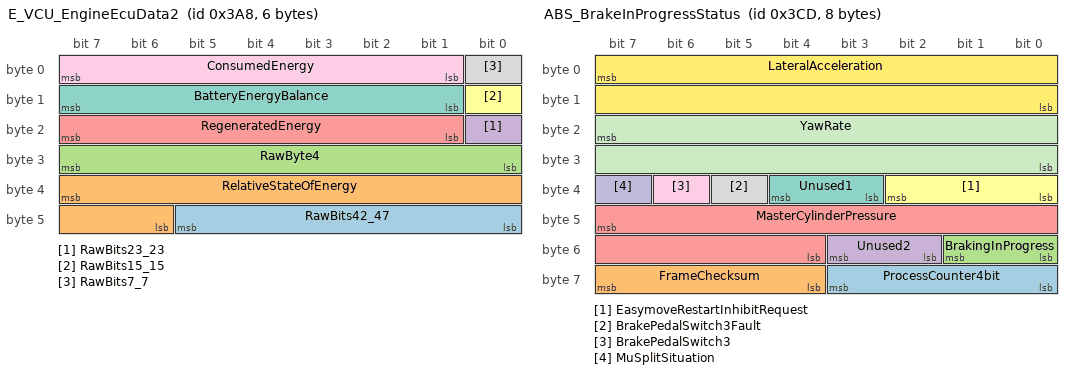
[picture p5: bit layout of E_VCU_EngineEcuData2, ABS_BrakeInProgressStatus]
BO_ 936 E_VCU_EngineEcuData2: 6 E_VCU
 SG_ RawBits42_47 : 45|6@0+ (1,0) [0|63] "raw"  BSI
 SG_ RelativeStateOfEnergy : 39|10@0+ (0.125,0) [0|100] "Wh"  BSI
 SG_ RawByte4 : 31|8@0+ (1,0) [0|255] "raw"  BSI
 SG_ RawBits23_23 : 16|1@0+ (1,0) [0|1] "raw"  BSI
 SG_ RegeneratedEnergy : 23|7@0+ (2,-254) [-254|0] "Wh"  BSI
 SG_ RawBits15_15 : 8|1@0+ (1,0) [0|1] "raw"  BSI
 SG_ BatteryEnergyBalance : 15|7@0+ (2,0) [0|254] "Wh"  BSI
 SG_ RawBits7_7 : 0|1@0+ (1,0) [0|1] "raw"  BSI
 SG_ ConsumedEnergy : 7|7@0+ (2,0) [0|254] "Wh"  BSI

BO_ 941 ABS_EasyMoveBvh2Data: 8 ABS
 SG_ Checksum : 59|4@0+ (1,0) [0|15] ""  BSI,BVA,CMM,HCU2,AAS,VCU,E_VCU
 SG_ ProcessCounter : 63|4@0+ (1,0) [0|15] ""  BSI,BVA,CMM,HCU2,AAS,VCU,E_VCU
 SG_ EpbRedLampAlert : 48|1@0+ (1,0) [0|1] ""  BSI,BVA,CMM,HCU2,AAS,VCU,E_VCU
 SG_ EpbDisplayWakeupRequest : 49|1@0+ (1,0) [0|1] ""  BSI,BVA,CMM,HCU2,AAS,VCU,E_VCU
 SG_ Unused3 : 51|2@0+ (1,0) [0|3] ""  BSI,BVA,CMM,HCU2,AAS,VCU,E_VCU
 SG_ EpbSwitchState : 54|3@0+ (1,0) [0|7] ""  BSI,BVA,CMM,HCU2,AAS,VCU,E_VCU
 SG_ EpbFault : 55|1@0+ (1,0) [0|1] ""  BSI,BVA,CMM,HCU2,AAS,VCU,E_VCU
 SG_ ParkBrakeFunctionStatusHmi : 43|4@0+ (1,0) [0|15] ""  BSI,BVA,CMM,HCU2,AAS,VCU,E_VCU
 SG_ CalibratedLongitudinalAcc_dc49b6 : 39|12@0+ (0.02,-40.96) [-40.96|40.92] "m/s2"  BSI,BVA,CMM,HCU2,AAS,VCU,E_VCU
 SG_ ParkBrakeFunctionStatus : 26|3@0+ (1,0) [0|7] ""  BSI,BVA,CMM,HCU2,AAS,VCU,E_VCU
 SG_ HydraulicWheelLockStatus : 27|1@0+ (1,0) [0|1] ""  BSI,BVA,CMM,HCU2,AAS,VCU,E_VCU
 SG_ AutoLockingModeState : 29|2@0+ (1,0) [0|3] ""  BSI,BVA,CMM,HCU2,AAS,VCU,E_VCU
 SG_ Unused2 : 30|1@0+ (1,0) [0|1] ""  BSI,BVA,CMM,HCU2,AAS,VCU,E_VCU
 SG_ EasyMoveFault : 31|1@0+ (1,0) [0|1] ""  BSI,BVA,CMM,HCU2,AAS,VCU,E_VCU
 SG_ EpbButtonPressRequest : 16|1@0+ (1,0) [0|1] ""  BSI,BVA,CMM,HCU2,AAS,VCU,E_VCU
 SG_ CruiseControlInhibitRequest : 17|1@0+ (1,0) [0|1] ""  BSI,BVA,CMM,HCU2,AAS,VCU,E_VCU
 SG_ LongitudinalControlRequest : 18|1@0+ (1,0) [0|1] ""  BSI,BVA,CMM,HCU2,AAS,VCU,E_VCU
 SG_ BrakePedalSignalRequest : 19|1@0+ (1,0) [0|1] ""  BSI,BVA,CMM,HCU2,AAS,VCU,E_VCU
 SG_ Unused1 : 21|2@0+ (1,0) [0|3] ""  BSI,BVA,CMM,HCU2,AAS,VCU,E_VCU
 SG_ WheelTorqueSetpointRequest : 13|8@0+ (25,-2000) [-2000|4000] "Nm"  BSI,BVA,CMM,HCU2,AAS,VCU,E_VCU
 SG_ MaxWheelTorqueCapability : 3|6@0+ (100,-2000) [-2000|4000] "Nm"  BSI,BVA,CMM,HCU2,AAS,VCU,E_VCU
 SG_ EpbRearLeftForceEstimate : 5|2@0+ (1,0) [0|3] ""  BSI,BVA,CMM,HCU2,AAS,VCU,E_VCU
 SG_ EpbRearRightForceEstimate : 7|2@0+ (1,0) [0|3] ""  BSI,BVA,CMM,HCU2,AAS,VCU,E_VCU

BO_ 973 ABS_BrakeInProgressStatus: 8 ABS
 SG_ ProcessCounter4bit : 59|4@0+ (1,0) [0|15] ""  CVM,DAE,SBW,BCP,CMM,BVA,BSI,HCU1,AAS,CSS,ESM,VCU,E_VCU,BSM
 SG_ FrameChecksum : 63|4@0+ (1,0) [0|15] ""  CVM,DAE,SBW,BCP,CMM,BVA,BSI,HCU1,AAS,CSS,ESM,VCU,E_VCU,BSM
 SG_ BrakingInProgress : 49|2@0+ (1,0) [0|3] ""  CVM,DAE,SBW,BCP,CMM,BVA,BSI,HCU1,AAS,CSS,ESM,VCU,E_VCU,BSM
 SG_ Unused2 : 51|2@0+ (1,0) [0|3] ""  CVM,DAE,SBW,BCP,CMM,BVA,BSI,HCU1,AAS,CSS,ESM,VCU,E_VCU,BSM
 SG_ MasterCylinderPressure : 47|12@0+ (0.1,-55) [-55|354.4] "bar"  CVM,DAE,SBW,BCP,CMM,BVA,BSI,HCU1,AAS,CSS,ESM,VCU,E_VCU,BSM
 SG_ EasymoveRestartInhibitRequest : 34|3@0+ (1,0) [0|7] ""  CVM,DAE,SBW,BCP,CMM,BVA,BSI,HCU1,AAS,CSS,ESM,VCU,E_VCU,BSM
 SG_ Unused1 : 36|2@0+ (1,0) [0|3] ""  CVM,DAE,SBW,BCP,CMM,BVA,BSI,HCU1,AAS,CSS,ESM,VCU,E_VCU,BSM
 SG_ BrakePedalSwitch3Fault : 37|1@0+ (1,0) [0|1] ""  CVM,DAE,SBW,BCP,CMM,BVA,BSI,HCU1,AAS,CSS,ESM,VCU,E_VCU,BSM
 SG_ BrakePedalSwitch3 : 38|1@0+ (1,0) [0|1] ""  CVM,DAE,SBW,BCP,CMM,BVA,BSI,HCU1,AAS,CSS,ESM,VCU,E_VCU,BSM
 SG_ MuSplitSituation : 39|1@0+ (1,0) [0|1] ""  CVM,DAE,SBW,BCP,CMM,BVA,BSI,HCU1,AAS,CSS,ESM,VCU,E_VCU,BSM
 SG_ YawRate : 23|16@0- (0.1,0) [-100|100] "°/s"  CVM,DAE,SBW,BCP,CMM,BVA,BSI,HCU1,AAS,CSS,ESM,VCU,E_VCU,BSM
 SG_ LateralAcceleration : 7|16@0- (0.05,0) [-15|15] "m/s2"  CVM,DAE,SBW,BCP,CMM,BVA,BSI,HCU1,AAS,CSS,ESM,VCU,E_VCU,BSM

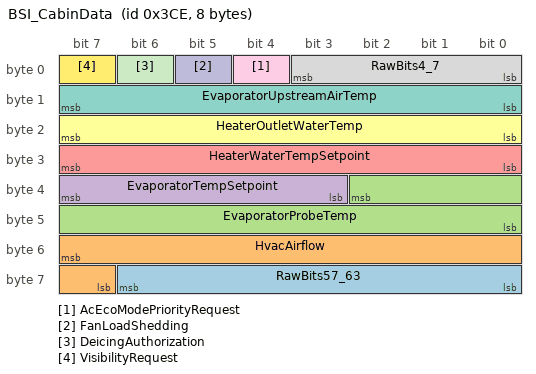
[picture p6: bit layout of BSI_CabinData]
BO_ 974 BSI_CabinData: 8 BSI
 SG_ RawBits57_63 : 62|7@0+ (1,0) [0|127] "raw"  E_VCU
 SG_ HvacAirflow : 55|9@0+ (0.5,0) [0|170] "g/s"  E_VCU
 SG_ EvaporatorProbeTemp : 34|11@0+ (0.1,-40) [-40|85] "degC"  E_VCU
 SG_ EvaporatorTempSetpoint : 39|5@0+ (0.5,0) [0|15] "degC"  E_VCU
 SG_ HeaterWaterTempSetpoint : 31|8@0+ (0.5,0) [0|70] "degC"  E_VCU
 SG_ HeaterOutletWaterTemp : 23|8@0+ (0.5,-40) [-40|80] "degC"  E_VCU
 SG_ EvaporatorUpstreamAirTemp : 15|8@0+ (0.5,-40) [-40|80] "degC"  E_VCU
 SG_ RawBits4_7 : 3|4@0+ (1,0) [0|15] "raw"  E_VCU
 SG_ AcEcoModePriorityRequest : 4|1@0+ (1,0) [0|1] ""  E_VCU
 SG_ FanLoadShedding : 5|1@0+ (1,0) [0|1] ""  E_VCU
 SG_ DeicingAuthorization : 6|1@0+ (1,0) [0|1] ""  E_VCU
 SG_ VisibilityRequest : 7|1@0+ (1,0) [0|1] ""  E_VCU

BO_ 1006 BSI_CabinData2: 4 BSI
 SG_ Unused1 : 15|24@0+ (1,0) [0|16777215] ""  CSS,CMM
 SG_ DetectionDeviceDecelerati_8e97ab : 7|8@0+ (0.05,-10.65) [-10.65|2] "m/s2"  CSS,CMM

BO_ 1010 BSI_CabinData3: 8 BSI
 SG_ DeadmanButtonRequestStatusBsi : 57|2@0+ (1,0) [0|3] ""  VCU,AAS,CMM,HCU1,ABS,DAE,E_VCU
 SG_ SteeringColumnAngleSetpoint : 55|14@0- (0.1,0) [-780|780] "°"  VCU,AAS,CMM,HCU1,ABS,DAE,E_VCU
 SG_ LkaLpaSteeringSelection : 40|1@0+ (1,0) [0|1] ""  VCU,AAS,CMM,HCU1,ABS,DAE,E_VCU
 SG_ LkaTorqueFactorRequest : 47|7@0+ (0.01,0) [0|1] ""  VCU,AAS,CMM,HCU1,ABS,DAE,E_VCU
 SG_ LkaRightCorrectionActivation : 32|1@0+ (1,0) [0|1] ""  VCU,AAS,CMM,HCU1,ABS,DAE,E_VCU
 SG_ LkaLeftCorrectionActivation : 33|1@0+ (1,0) [0|1] ""  VCU,AAS,CMM,HCU1,ABS,DAE,E_VCU
 SG_ LkaGlobalState : 36|3@0+ (1,0) [0|7] ""  VCU,AAS,CMM,HCU1,ABS,DAE,E_VCU
 SG_ LkaRequestedYawRate : 31|11@0- (0.1,0) [-100|100] "°/s"  VCU,AAS,CMM,HCU1,ABS,DAE,E_VCU
 SG_ AcBlowerSpeed : 22|7@0+ (1,0) [0|100] "%"  VCU,AAS,CMM,HCU1,ABS,DAE,E_VCU
 SG_ AsrDisconnectRequest : 23|1@0+ (1,0) [0|1] ""  VCU,AAS,CMM,HCU1,ABS,DAE,E_VCU
 SG_ ProcessCounter3f2 : 11|4@0+ (1,0) [0|15] ""  VCU,AAS,CMM,HCU1,ABS,DAE,E_VCU
 SG_ FrameChecksum3f2 : 15|4@0+ (1,0) [0|15] ""  VCU,AAS,CMM,HCU1,ABS,DAE,E_VCU
 SG_ DemistingRequest : 0|1@0+ (1,0) [0|1] ""  VCU,AAS,CMM,HCU1,ABS,DAE,E_VCU
 SG_ AbsEspPowerCutRequest : 1|1@0+ (1,0) [0|1] ""  VCU,AAS,CMM,HCU1,ABS,DAE,E_VCU
 SG_ PowerSteeringCutRequest : 2|1@0+ (1,0) [0|1] ""  VCU,AAS,CMM,HCU1,ABS,DAE,E_VCU
 SG_ EasymovePowerCutRequest : 3|1@0+ (1,0) [0|1] ""  VCU,AAS,CMM,HCU1,ABS,DAE,E_VCU
 SG_ SuspensionPowerCutRequest : 4|1@0+ (1,0) [0|1] ""  VCU,AAS,CMM,HCU1,ABS,DAE,E_VCU
 SG_ ZevModeProhibition : 5|1@0+ (1,0) [0|1] ""  VCU,AAS,CMM,HCU1,ABS,DAE,E_VCU
 SG_ BrakeModeConfiguration : 6|1@0+ (1,0) [0|1] ""  VCU,AAS,CMM,HCU1,ABS,DAE,E_VCU
 SG_ TrailerDetection : 7|1@0+ (1,0) [0|1] ""  VCU,AAS,CMM,HCU1,ABS,DAE,E_VCU

BO_TX_BU_ 166 : E_VCU,VCU;
BO_TX_BU_ 520 : E_VCU,CMM;
BO_TX_BU_ 820 : E_VCU,VCU;
BO_TX_BU_ 840 : E_VCU,CMM;
BO_TX_BU_ 936 : E_VCU,CMM;

CM_ BU_ AAS "PSA-RE ECU alias, not independently identified physical transmitter/receiver.";
CM_ BU_ ABS "PSA-RE ECU alias, not independently identified physical transmitter/receiver.";
CM_ BU_ ARTIV "PSA-RE ECU alias, not independently identified physical transmitter/receiver.";
CM_ BU_ AVAS "PSA-RE ECU alias, not independently identified physical transmitter/receiver.";
CM_ BU_ BCP "PSA-RE ECU alias, not independently identified physical transmitter/receiver.";
CM_ BU_ BSI "PSA-RE ECU alias, not independently identified physical transmitter/receiver.";
CM_ BU_ BSM "PSA-RE ECU alias, not independently identified physical transmitter/receiver.";
CM_ BU_ BVA "PSA-RE ECU alias, not independently identified physical transmitter/receiver.";
CM_ BU_ CAV "PSA-RE ECU alias, not independently identified physical transmitter/receiver.";
CM_ BU_ CMM "PSA-RE ECU alias, not independently identified physical transmitter/receiver.";
CM_ BU_ CSS "PSA-RE ECU alias, not independently identified physical transmitter/receiver.";
CM_ BU_ CVM "PSA-RE ECU alias, not independently identified physical transmitter/receiver.";
CM_ BU_ DAE "PSA-RE ECU alias, not independently identified physical transmitter/receiver.";
CM_ BU_ DMTR "PSA-RE ECU alias, not independently identified physical transmitter/receiver.";
CM_ BU_ ESM "PSA-RE ECU alias, not independently identified physical transmitter/receiver.";
CM_ BU_ E_VCU "PSA-RE ECU alias, not independently identified physical transmitter/receiver.";
CM_ BU_ HCU1 "PSA-RE ECU alias, not independently identified physical transmitter/receiver.";
CM_ BU_ HCU2 "PSA-RE ECU alias, not independently identified physical transmitter/receiver.";
CM_ BU_ LVNSD "PSA-RE ECU alias, not independently identified physical transmitter/receiver.";
CM_ BU_ MCM "PSA-RE ECU alias, not independently identified physical transmitter/receiver.";
CM_ BU_ MDS "PSA-RE ECU alias, not independently identified physical transmitter/receiver.";
CM_ BU_ RBG "PSA-RE ECU alias, not independently identified physical transmitter/receiver.";
CM_ BU_ SBW "PSA-RE ECU alias, not independently identified physical transmitter/receiver.";
CM_ BU_ VCU "PSA-RE ECU alias, not independently identified physical transmitter/receiver.";
CM_ BO_ 166 "Observed OBD 6/14 HS1. CAN ID 0x0A6; DLC_mismatch. PSA-RE name: WHEEL_PULSE_COUNTERS. Immobiliser seed (challenge) sent by the electric motor control unit (MCU) to the body computer (BSI), with the immobiliser computation status. Source: https://github.com/prototux/PSA-RE/blob/67f7581e7622410efdbb29c7eda3b86982b9b450/buses/AEE2010.electric/HS.HS1/0A6.yml. Database sender alternatives: VCU,E_VCU. ECU labels are database claims; forwarding/physical transmitter not independently identified. All fitting source fields retained, including default/unavailable-only candidates. See audit/source JSON for exclusions and unresolved alternatives.";
CM_ SG_ 166 ImmoEcuState "DATABASE_CANDIDATE: layout imported; physical meaning not independently verified. PSA-RE bits 2.7-2.0. ECU state for the immobiliser (ADC) function WARNING: upstream DLC 5 differs from observed 2; this in-bounds prefix is an unverified candidate.";
CM_ SG_ 166 ImmoLocalIdMcuBsi "DATABASE_CANDIDATE: layout imported; physical meaning not independently verified. PSA-RE bits 1.7-1.0. Immobiliser function local identifier (MCU-BSI) WARNING: upstream DLC 5 differs from observed 2; this in-bounds prefix is an unverified candidate.";
CM_ BO_ 258 "Observed OBD 6/14 HS1. CAN ID 0x102; ID_DLC_match. PSA-RE name: SCDT_VERSION. Software and calibration identification of the ECU, sent once at start-up. Source: https://github.com/prototux/PSA-RE/blob/67f7581e7622410efdbb29c7eda3b86982b9b450/buses/AEE2010.electric/HS.HS1/102.yml. Database sender alternatives: VCU. ECU labels are database claims; forwarding/physical transmitter not independently identified. All fitting source fields retained, including default/unavailable-only candidates. See audit/source JSON for exclusions and unresolved alternatives.";
CM_ SG_ 258 TuningEdition "DATABASE_CANDIDATE: layout imported; physical meaning not independently verified. PSA-RE bits 8.7-8.0. Tuning evolution identifier (0 if no tuning-specific parameter).";
CM_ SG_ 258 SoftwareVersionEvolution "DATABASE_CANDIDATE: layout imported; physical meaning not independently verified. PSA-RE bits 7.7-7.0. Software version evolution identifier.";
CM_ SG_ 258 SoftwareVersionId "DATABASE_CANDIDATE: layout imported; physical meaning not independently verified. PSA-RE bits 6.7-6.0. Software version identifier.";
CM_ SG_ 258 ApplicationType "DATABASE_CANDIDATE: layout imported; physical meaning not independently verified. PSA-RE bits 5.7-5.0. Application type, linked to a specific hardware version; set by the supplier (FFh if none).";
CM_ SG_ 258 SoftwareVersionDateYear "DATABASE_CANDIDATE: layout imported; physical meaning not independently verified. PSA-RE bits 4.7-4.0. Software version date, year (00-99; FFh if unknown).";
CM_ SG_ 258 SoftwareVersionDateMonth "DATABASE_CANDIDATE: layout imported; physical meaning not independently verified. PSA-RE bits 3.7-3.0. Software version date, month (FFh if unknown).";
CM_ SG_ 258 SoftwareVersionDateDay "DATABASE_CANDIDATE: layout imported; physical meaning not independently verified. PSA-RE bits 2.7-2.0. Software version date, day (FFh if unknown).";
CM_ SG_ 258 SystemVersion "DATABASE_CANDIDATE: layout imported; physical meaning not independently verified. PSA-RE bits 1.7-1.0. System version.";
CM_ BO_ 274 "Observed OBD 6/14 HS1. CAN ID 0x112; ID_DLC_match. PSA-RE name: BSI_VERSION. Software and calibration identification of the ECU, sent once at start-up. Source: https://github.com/prototux/PSA-RE/blob/67f7581e7622410efdbb29c7eda3b86982b9b450/buses/AEE2010.full/HS.HS1/112.yml. Database sender alternatives: BSI. ECU labels are database claims; forwarding/physical transmitter not independently identified. All fitting source fields retained, including default/unavailable-only candidates. See audit/source JSON for exclusions and unresolved alternatives.";
CM_ SG_ 274 TuningEdition "DATABASE_CANDIDATE: layout imported; physical meaning not independently verified. PSA-RE bits 8.7-8.0. Tuning evolution identifier (0 if no tuning-specific parameter).";
CM_ SG_ 274 SoftwareVersionEvolution "DATABASE_CANDIDATE: layout imported; physical meaning not independently verified. PSA-RE bits 7.7-7.0. Software version evolution identifier.";
CM_ SG_ 274 SoftwareVersionId "DATABASE_CANDIDATE: layout imported; physical meaning not independently verified. PSA-RE bits 6.7-6.0. Software version identifier.";
CM_ SG_ 274 ApplicationType "DATABASE_CANDIDATE: layout imported; physical meaning not independently verified. PSA-RE bits 5.7-5.0. Application type, linked to a specific hardware version; set by the supplier (FFh if none).";
CM_ SG_ 274 SoftwareVersionDateYear "DATABASE_CANDIDATE: layout imported; physical meaning not independently verified. PSA-RE bits 4.7-4.0. Software version date, year (00-99; FFh if unknown).";
CM_ SG_ 274 SoftwareVersionDateMonth "DATABASE_CANDIDATE: layout imported; physical meaning not independently verified. PSA-RE bits 3.7-3.0. Software version date, month (FFh if unknown).";
CM_ SG_ 274 SoftwareVersionDateDay "DATABASE_CANDIDATE: layout imported; physical meaning not independently verified. PSA-RE bits 2.7-2.0. Software version date, day (FFh if unknown).";
CM_ SG_ 274 SystemVersion "DATABASE_CANDIDATE: layout imported; physical meaning not independently verified. PSA-RE bits 1.7-1.0. System version.";
CM_ BO_ 298 "Observed OBD 6/14 HS1. CAN ID 0x12A; ID_DLC_match. PSA-RE name: ESM_VERSION. Software and calibration identification of the ECU, sent once at start-up. Source: https://github.com/prototux/PSA-RE/blob/67f7581e7622410efdbb29c7eda3b86982b9b450/buses/AEE2010.full/HS.HS1/12A.yml. Database sender alternatives: ESM. ECU labels are database claims; forwarding/physical transmitter not independently identified. All fitting source fields retained, including default/unavailable-only candidates. See audit/source JSON for exclusions and unresolved alternatives.";
CM_ SG_ 298 TuningEdition "DATABASE_CANDIDATE: layout imported; physical meaning not independently verified. PSA-RE bits 8.7-8.0. Tuning evolution identifier (0 if no tuning-specific parameter).";
CM_ SG_ 298 SoftwareVersionEvolution "DATABASE_CANDIDATE: layout imported; physical meaning not independently verified. PSA-RE bits 7.7-7.0. Software version evolution identifier.";
CM_ SG_ 298 SoftwareVersionId "DATABASE_CANDIDATE: layout imported; physical meaning not independently verified. PSA-RE bits 6.7-6.0. Software version identifier.";
CM_ SG_ 298 ApplicationType "DATABASE_CANDIDATE: layout imported; physical meaning not independently verified. PSA-RE bits 5.7-5.0. Application type, linked to a specific hardware version; set by the supplier (FFh if none).";
CM_ SG_ 298 SoftwareVersionDateYear "DATABASE_CANDIDATE: layout imported; physical meaning not independently verified. PSA-RE bits 4.7-4.0. Software version date, year (00-99; FFh if unknown).";
CM_ SG_ 298 SoftwareVersionDateMonth "DATABASE_CANDIDATE: layout imported; physical meaning not independently verified. PSA-RE bits 3.7-3.0. Software version date, month (FFh if unknown).";
CM_ SG_ 298 SoftwareVersionDateDay "DATABASE_CANDIDATE: layout imported; physical meaning not independently verified. PSA-RE bits 2.7-2.0. Software version date, day (FFh if unknown).";
CM_ SG_ 298 SystemVersion "DATABASE_CANDIDATE: layout imported; physical meaning not independently verified. PSA-RE bits 1.7-1.0. System version.";
CM_ BO_ 520 "Observed OBD 6/14 HS1. CAN ID 0x208; ID_DLC_match. PSA-RE name: ENGINE_HYBRID_DYNAMIC_DATA_3. Engine dynamic data for hybrid variants: hybrid motor torque, resistant torque, pre-processed driver torque request, engine-restart and particulate-filter regeneration requests, raw powertrain state. Source: https://github.com/prototux/PSA-RE/blob/67f7581e7622410efdbb29c7eda3b86982b9b450/buses/AEE2010.full/HS.HS1/208.yml. Database sender alternatives: CMM,E_VCU. ECU labels are database claims; forwarding/physical transmitter not independently identified. All fitting source fields retained, including default/unavailable-only candidates. See audit/source JSON for exclusions and unresolved alternatives.";
CM_ SG_ 520 DriverTorqueRequestProcessed "DATABASE_CANDIDATE: layout imported; physical meaning not independently verified. PSA-RE bits 8.7-8.0. Driver torque request, after processing Raw invalid=255; numeric DBC decoders may still scale it: check raw before use. Upstream default raw=50 (not necessarily valid data).";
CM_ SG_ 520 AnticipatedEngineTorque "DATABASE_CANDIDATE: layout imported; physical meaning not independently verified. PSA-RE bits 7.7-7.0. Anticipated engine torque Raw invalid=255; numeric DBC decoders may still scale it: check raw before use. Upstream default raw=50 (not necessarily valid data).";
CM_ SG_ 520 ActualTorqueWithoutGearbo_d9537a "DATABASE_CANDIDATE: layout imported; physical meaning not independently verified. PSA-RE bits 6.7-6.0. Actual torque, excluding gearbox-requested reduction Raw invalid=255; numeric DBC decoders may still scale it: check raw before use. Upstream default raw=50 (not necessarily valid data).";
CM_ SG_ 520 Unused2 "DATABASE_CANDIDATE: layout imported; physical meaning not independently verified. PSA-RE bits 5.0. ";
CM_ SG_ 520 BrakePedalSwitch2 "DATABASE_CANDIDATE: layout imported; physical meaning not independently verified. PSA-RE bits 5.1. Brake pedal secondary (redundant) switch Upstream default raw=0 (not necessarily valid data).";
CM_ SG_ 520 CruiseSpeedLimiterStatus "DATABASE_CANDIDATE: layout imported; physical meaning not independently verified. PSA-RE bits 5.3-5.2. Cruise control (cruise control) or speed limiter (speed limiter) function status Upstream default raw=3 (not necessarily valid data).";
CM_ SG_ 520 EngineTorqueEstimateUncertain "DATABASE_CANDIDATE: layout imported; physical meaning not independently verified. PSA-RE bits 5.4. Estimated engine torque values uncertain Upstream default raw=0 (not necessarily valid data).";
CM_ SG_ 520 Unused1 "DATABASE_CANDIDATE: layout imported; physical meaning not independently verified. PSA-RE bits 5.5. ";
CM_ SG_ 520 DiagStatus "DATABASE_CANDIDATE: layout imported; physical meaning not independently verified. PSA-RE bits 5.6. Multiplexed communication diagnostic status Upstream default raw=0 (not necessarily valid data).";
CM_ SG_ 520 EngineLoadRequest "DATABASE_CANDIDATE: layout imported; physical meaning not independently verified. PSA-RE bits 5.7. Engine load request to assist filter regeneration (processed by the BSI) Upstream default raw=0 (not necessarily valid data).";
CM_ SG_ 520 DriverDemandPercent "DATABASE_CANDIDATE: layout imported; physical meaning not independently verified. PSA-RE bits 4.7-4.0. Driver demand Raw invalid=255; numeric DBC decoders may still scale it: check raw before use. Upstream default raw=0 (not necessarily valid data).";
CM_ SG_ 520 ActualTorque "DATABASE_CANDIDATE: layout imported; physical meaning not independently verified. PSA-RE bits 3.7-3.0. Actual engine torque Raw invalid=255; numeric DBC decoders may still scale it: check raw before use. Upstream default raw=50 (not necessarily valid data).";
CM_ SG_ 520 EngineSpeed "DATABASE_CANDIDATE: layout imported; physical meaning not independently verified. PSA-RE bits 1.7-2.0. Engine speed (16-bit) Raw invalid=65535; numeric DBC decoders may still scale it: check raw before use. Upstream default raw=65535 (not necessarily valid data).";
CM_ BO_ 602 "Observed OBD 6/14 HS1. CAN ID 0x25A; no_HS1_definition. PSA-RE name: unknown.  Source: none in HS.HS1. Database sender alternatives: unknown. ECU labels are database claims; forwarding/physical transmitter not independently identified. All fitting source fields retained, including default/unavailable-only candidates. See audit/source JSON for exclusions and unresolved alternatives.";
CM_ SG_ 602 RawByte2 "RAW. PSA-RE bits 2.7-2.0. Raw unmapped/padding bits; no physical interpretation.";
CM_ SG_ 602 RawByte1 "RAW. PSA-RE bits 1.7-1.0. Raw unmapped/padding bits; no physical interpretation.";
CM_ BO_ 610 "Observed OBD 6/14 HS1. CAN ID 0x262; ID_DLC_match. PSA-RE name: VCU_POWERTRAIN_STATE_2. Hybrid powertrain state from the vehicle control unit. Source: https://github.com/prototux/PSA-RE/blob/67f7581e7622410efdbb29c7eda3b86982b9b450/buses/AEE2010.electric/HS.HS1/262.yml. Database sender alternatives: VCU. ECU labels are database claims; forwarding/physical transmitter not independently identified. All fitting source fields retained, including default/unavailable-only candidates. See audit/source JSON for exclusions and unresolved alternatives.";
CM_ SG_ 610 Unused1 "DATABASE_CANDIDATE: layout imported; physical meaning not independently verified. PSA-RE bits 1.3-1.0. ";
CM_ SG_ 610 PowertrainState "DATABASE_CANDIDATE: layout imported; physical meaning not independently verified. PSA-RE bits 1.7-1.4. Hybrid powertrain operating state Upstream default raw=0 (not necessarily valid data).";
CM_ BO_ 749 "Observed OBD 6/14 HS1. CAN ID 0x2ED; ID_DLC_match. PSA-RE name: WHEEL_PULSE_COUNTER_DATA_2. Wheel-speed sensor pulse counters and fault flags for each wheel. Source: https://github.com/prototux/PSA-RE/blob/67f7581e7622410efdbb29c7eda3b86982b9b450/buses/AEE2010.full/HS.HS1/2ED.yml. Database sender alternatives: ABS. ECU labels are database claims; forwarding/physical transmitter not independently identified. All fitting source fields retained, including default/unavailable-only candidates. See audit/source JSON for exclusions and unresolved alternatives.";
CM_ SG_ 749 RearRightWheelPulseCounter "DATABASE_CANDIDATE: layout imported; physical meaning not independently verified. PSA-RE bits 6.2-7.0. Rear right wheel pulse counter (96 pulses/rev) Upstream default raw=0 (not necessarily valid data).";
CM_ SG_ 749 RearRightWheelPulseCounterFault "DATABASE_CANDIDATE: layout imported; physical meaning not independently verified. PSA-RE bits 6.3. Rear right wheel pulse counter fault Upstream default raw=0 (not necessarily valid data).";
CM_ SG_ 749 RearLeftWheelPulseCounter "DATABASE_CANDIDATE: layout imported; physical meaning not independently verified. PSA-RE bits 5.6-6.4. Rear left wheel pulse counter (96 pulses/rev) Upstream default raw=0 (not necessarily valid data).";
CM_ SG_ 749 RearLeftWheelPulseCounterFault "DATABASE_CANDIDATE: layout imported; physical meaning not independently verified. PSA-RE bits 5.7. Rear left wheel pulse counter fault Upstream default raw=0 (not necessarily valid data).";
CM_ SG_ 749 FrontRightWheelPulseCounter "DATABASE_CANDIDATE: layout imported; physical meaning not independently verified. PSA-RE bits 3.2-4.0. Front right wheel pulse counter (96 pulses/rev) Upstream default raw=0 (not necessarily valid data).";
CM_ SG_ 749 FrontRightWheelPulseCounterFault "DATABASE_CANDIDATE: layout imported; physical meaning not independently verified. PSA-RE bits 3.3. Front right wheel pulse counter fault Upstream default raw=0 (not necessarily valid data).";
CM_ SG_ 749 FrontLeftWheelPulseCounter "DATABASE_CANDIDATE: layout imported; physical meaning not independently verified. PSA-RE bits 2.6-3.4. Front left wheel pulse counter (96 pulses/rev) Upstream default raw=0 (not necessarily valid data).";
CM_ SG_ 749 FrontLeftWheelPulseCounterFault "DATABASE_CANDIDATE: layout imported; physical meaning not independently verified. PSA-RE bits 2.7. Front left wheel pulse counter fault Upstream default raw=0 (not necessarily valid data).";
CM_ SG_ 749 ProcessCounter "DATABASE_CANDIDATE: layout imported; physical meaning not independently verified. PSA-RE bits 1.3-1.0. Rolling counter incremented at each calculation cycle Upstream default raw=0 (not necessarily valid data).";
CM_ SG_ 749 FrameChecksum "DATABASE_CANDIDATE: layout imported; physical meaning not independently verified. PSA-RE bits 1.7-1.4. Checksum of the frame";
CM_ BO_ 757 "Observed OBD 6/14 HS1. CAN ID 0x2F5; ID_DLC_match. PSA-RE name: STEERING_BRAKE_COUPLING_DATA_2. Optimised steering-wheel torque and fault status, for the function linking power-steering coupling to the brakes. Source: https://github.com/prototux/PSA-RE/blob/67f7581e7622410efdbb29c7eda3b86982b9b450/buses/AEE2010.full/HS.HS1/2F5.yml. Database sender alternatives: DAE. ECU labels are database claims; forwarding/physical transmitter not independently identified. All fitting source fields retained, including default/unavailable-only candidates. See audit/source JSON for exclusions and unresolved alternatives.";
CM_ SG_ 757 ColumnAngleSafeStatus "DATABASE_CANDIDATE: layout imported; physical meaning not independently verified. PSA-RE bits 7.0. Steering column angle safety status Upstream default raw=0 (not necessarily valid data).";
CM_ SG_ 757 ColumnAngleMonitoringCounter "DATABASE_CANDIDATE: layout imported; physical meaning not independently verified. PSA-RE bits 7.3-7.1. Steering column angle monitoring interrupt counter";
CM_ SG_ 757 EpsColumnSpeed "DATABASE_CANDIDATE: layout imported; physical meaning not independently verified. PSA-RE bits 6.7-7.4. Power steering (EPS) column rotation speed Raw invalid=2047; numeric DBC decoders may still scale it: check raw before use. Upstream default raw=0 (not necessarily valid data).";
CM_ SG_ 757 EpsColumnAngle "DATABASE_CANDIDATE: layout imported; physical meaning not independently verified. PSA-RE bits 4.7-5.0. Power steering (EPS) column angle Raw invalid=32767; numeric DBC decoders may still scale it: check raw before use. Upstream default raw=0 (not necessarily valid data).";
CM_ SG_ 757 RawBits22_23 "RAW. PSA-RE bits 3.1-3.0. Raw unmapped/padding bits; no physical interpretation.";
CM_ SG_ 757 CityparkDeactivationCause "DATABASE_CANDIDATE: layout imported; physical meaning not independently verified. PSA-RE bits 3.4-3.2. Citypark parking assist deactivation cause Upstream default raw=0 (not necessarily valid data).";
CM_ SG_ 757 EpsStatusForCitypark "DATABASE_CANDIDATE: layout imported; physical meaning not independently verified. PSA-RE bits 3.6-3.5. Power steering (EPS) status, for the Citypark parking assist function Upstream default raw=0 (not necessarily valid data).";
CM_ SG_ 757 SspEpsCouplingFailure "DATABASE_CANDIDATE: layout imported; physical meaning not independently verified. PSA-RE bits 3.7. SSP-EPS coupling function failure Upstream default raw=0 (not necessarily valid data).";
CM_ SG_ 757 SteeringWheelDriverTorque "DATABASE_CANDIDATE: layout imported; physical meaning not independently verified. PSA-RE bits 2.7-2.0. Torque applied by the driver on the steering wheel (negative = counterclockwise) Raw invalid=127; numeric DBC decoders may still scale it: check raw before use. Upstream default raw=127 (not necessarily valid data).";
CM_ SG_ 757 ProcessCounter4bit "DATABASE_CANDIDATE: layout imported; physical meaning not independently verified. PSA-RE bits 1.3-1.0. 4-bit process counter Upstream default raw=0 (not necessarily valid data).";
CM_ SG_ 757 EpsFrameChecksum "DATABASE_CANDIDATE: layout imported; physical meaning not independently verified. PSA-RE bits 1.7-1.4. Power steering (DAE) dynamic frame checksum";
CM_ BO_ 773 "Observed OBD 6/14 HS1. CAN ID 0x305; ID_DLC_match. PSA-RE name: STEERING_WHEEL_ANGLE. Steering-wheel angle, rotation speed and direction, sensor calibration/trim and fault status. Source: https://github.com/prototux/PSA-RE/blob/67f7581e7622410efdbb29c7eda3b86982b9b450/buses/AEE2010.full/HS.HS1/305.yml. Database sender alternatives: CAV. ECU labels are database claims; forwarding/physical transmitter not independently identified. All fitting source fields retained, including default/unavailable-only candidates. See audit/source JSON for exclusions and unresolved alternatives.";
CM_ SG_ 773 RawBits52_55 "RAW. PSA-RE bits 7.3-7.0. Raw unmapped/padding bits; no physical interpretation.";
CM_ SG_ 773 SteeringWheelAngleSource "DATABASE_CANDIDATE: layout imported; physical meaning not independently verified. PSA-RE bits 7.5-7.4. Indication of the source of the steering wheel angle information Upstream default raw=0 (not necessarily valid data).";
CM_ SG_ 773 SteeringWheelAngleInaccurate "DATABASE_CANDIDATE: layout imported; physical meaning not independently verified. PSA-RE bits 7.6. Steering wheel angle flagged as inaccurate Upstream default raw=1 (not necessarily valid data).";
CM_ SG_ 773 SteeringWheelAngleInitialized "DATABASE_CANDIDATE: layout imported; physical meaning not independently verified. PSA-RE bits 7.7. Steering wheel angle initialization flag Upstream default raw=1 (not necessarily valid data).";
CM_ SG_ 773 SteeringWheelRotationSpee_effc71 "DATABASE_CANDIDATE: layout imported; physical meaning not independently verified. PSA-RE bits 6.7-6.0. Steering wheel rotation speed, optimized response time Raw invalid=255; numeric DBC decoders may still scale it: check raw before use. Upstream default raw=0 (not necessarily valid data).";
CM_ SG_ 773 SteeringWheelAngleSensorP_3a627b "DATABASE_CANDIDATE: layout imported; physical meaning not independently verified. PSA-RE bits 5.3-5.0. Rolling counter of the steering wheel angle sensor calculation Upstream default raw=0 (not necessarily valid data).";
CM_ SG_ 773 SteeringWheelAngleChecksum "DATABASE_CANDIDATE: layout imported; physical meaning not independently verified. PSA-RE bits 5.7-5.4. Steering wheel angle signal checksum";
CM_ SG_ 773 SteeringWheelAngleSensorStatus "DATABASE_CANDIDATE: layout imported; physical meaning not independently verified. PSA-RE bits 4.0. Internal status of the steering wheel angle sensor Upstream default raw=1 (not necessarily valid data).";
CM_ SG_ 773 SteeringWheelAngleSensorC_affc57 "DATABASE_CANDIDATE: layout imported; physical meaning not independently verified. PSA-RE bits 4.1. Steering wheel angle sensor calibration status Upstream default raw=1 (not necessarily valid data).";
CM_ SG_ 773 SteeringWheelAngleSensorA_f0288c "DATABASE_CANDIDATE: layout imported; physical meaning not independently verified. PSA-RE bits 4.2. Indication of the supplier factory trim of the steering wheel angle sensor Upstream default raw=1 (not necessarily valid data).";
CM_ SG_ 773 SteeringWheelAngleSensorF_3754bb "DATABASE_CANDIDATE: layout imported; physical meaning not independently verified. PSA-RE bits 4.6-4.3. Steering wheel angle sensor fault code Upstream default raw=0 (not necessarily valid data).";
CM_ SG_ 773 SteeringWheelRotationDirection "DATABASE_CANDIDATE: layout imported; physical meaning not independently verified. PSA-RE bits 4.7. Steering wheel angle sensor rotation direction Upstream default raw=0 (not necessarily valid data).";
CM_ SG_ 773 SteeringRotationSpeed "DATABASE_CANDIDATE: layout imported; physical meaning not independently verified. PSA-RE bits 3.7-3.0. Steering wheel rotation speed Raw invalid=255; numeric DBC decoders may still scale it: check raw before use. Upstream default raw=0 (not necessarily valid data).";
CM_ SG_ 773 SteeringAngle "DATABASE_CANDIDATE: layout imported; physical meaning not independently verified. PSA-RE bits 1.7-2.0. Steering wheel angle Raw invalid=32767; numeric DBC decoders may still scale it: check raw before use. Upstream default raw=0 (not necessarily valid data).";
CM_ BO_ 781 "Observed OBD 6/14 HS1. CAN ID 0x30D; ID_DLC_match. PSA-RE name: WHEEL_SPEED_RAW. Unfiltered wheel speeds, front and rear, left and right. Source: https://github.com/prototux/PSA-RE/blob/67f7581e7622410efdbb29c7eda3b86982b9b450/buses/AEE2010.full/HS.HS1/30D.yml. Database sender alternatives: ABS. ECU labels are database claims; forwarding/physical transmitter not independently identified. All fitting source fields retained, including default/unavailable-only candidates. See audit/source JSON for exclusions and unresolved alternatives.";
CM_ SG_ 781 WheelSpeedRR "OWNER_CONFIRMED in READY capture: speed/SOC agree with vehicle; startup values need validity gating. PSA-RE bits 7.7-8.0. Unfiltered rear right wheel speed Raw invalid=65535; numeric DBC decoders may still scale it: check raw before use. Upstream default raw=65534 (not necessarily valid data).";
CM_ SG_ 781 WheelSpeedRL "OWNER_CONFIRMED in READY capture: speed/SOC agree with vehicle; startup values need validity gating. PSA-RE bits 5.7-6.0. Unfiltered rear left wheel speed Raw invalid=65535; numeric DBC decoders may still scale it: check raw before use. Upstream default raw=65534 (not necessarily valid data).";
CM_ SG_ 781 WheelSpeedFR "OWNER_CONFIRMED in READY capture: speed/SOC agree with vehicle; startup values need validity gating. PSA-RE bits 3.7-4.0. Unfiltered front right wheel speed Raw invalid=65535; numeric DBC decoders may still scale it: check raw before use. Upstream default raw=65534 (not necessarily valid data).";
CM_ SG_ 781 WheelSpeedFL "OWNER_CONFIRMED in READY capture: speed/SOC agree with vehicle; startup values need validity gating. PSA-RE bits 1.7-2.0. Unfiltered front left wheel speed Raw invalid=65535; numeric DBC decoders may still scale it: check raw before use. Upstream default raw=65534 (not necessarily valid data).";
CM_ BO_ 820 "Observed OBD 6/14 HS1. CAN ID 0x334; ID_DLC_match. PSA-RE name: TRACTION_BATTERY_DYNAMIC_DATA_5. Traction battery management data: measured HV current/voltage, disconnect state, unexpected contactor opening and hydrogen detection. Source: https://github.com/prototux/PSA-RE/blob/67f7581e7622410efdbb29c7eda3b86982b9b450/buses/AEE2010.electric/HS.HS1/334.yml. Database sender alternatives: E_VCU,VCU. ECU labels are database claims; forwarding/physical transmitter not independently identified. All fitting source fields retained, including default/unavailable-only candidates. See audit/source JSON for exclusions and unresolved alternatives.";
CM_ SG_ 820 RawByte8_Mux27_28_29_30_31 "RAW. PSA-RE bits 8.7-8.0. Raw unmapped/padding bits; no physical interpretation.";
CM_ SG_ 820 CellVoltage044 "SUPPORTED_CAPTURE: coherent nonzero 108-cell sweeps; startup zero payloads are not valid battery readings. PSA-RE bits 7.5-8.0. Voltage of high-voltage battery cell 44 Raw invalid=16383; numeric DBC decoders may still scale it: check raw before use.";
CM_ SG_ 820 CellVoltage040 "SUPPORTED_CAPTURE: coherent nonzero 108-cell sweeps; startup zero payloads are not valid battery readings. PSA-RE bits 7.5-8.0. Voltage of high-voltage battery cell 40 Raw invalid=16383; numeric DBC decoders may still scale it: check raw before use.";
CM_ SG_ 820 CellVoltage092 "SUPPORTED_CAPTURE: coherent nonzero 108-cell sweeps; startup zero payloads are not valid battery readings. PSA-RE bits 7.5-8.0. Voltage of high-voltage battery cell 92 Raw invalid=16383; numeric DBC decoders may still scale it: check raw before use.";
CM_ SG_ 820 CellVoltage020 "SUPPORTED_CAPTURE: coherent nonzero 108-cell sweeps; startup zero payloads are not valid battery readings. PSA-RE bits 7.5-8.0. Voltage of high-voltage battery cell 20 Raw invalid=16383; numeric DBC decoders may still scale it: check raw before use.";
CM_ SG_ 820 CellVoltage088 "SUPPORTED_CAPTURE: coherent nonzero 108-cell sweeps; startup zero payloads are not valid battery readings. PSA-RE bits 7.5-8.0. Voltage of high-voltage battery cell 88 Raw invalid=16383; numeric DBC decoders may still scale it: check raw before use.";
CM_ SG_ 820 CellVoltage108 "SUPPORTED_CAPTURE: coherent nonzero 108-cell sweeps; startup zero payloads are not valid battery readings. PSA-RE bits 7.5-8.0. Voltage of high-voltage battery cell 108 Raw invalid=16383; numeric DBC decoders may still scale it: check raw before use.";
CM_ SG_ 820 CellVoltage104 "SUPPORTED_CAPTURE: coherent nonzero 108-cell sweeps; startup zero payloads are not valid battery readings. PSA-RE bits 7.5-8.0. Voltage of high-voltage battery cell 104 Raw invalid=16383; numeric DBC decoders may still scale it: check raw before use.";
CM_ SG_ 820 CellVoltage068 "SUPPORTED_CAPTURE: coherent nonzero 108-cell sweeps; startup zero payloads are not valid battery readings. PSA-RE bits 7.5-8.0. Voltage of high-voltage battery cell 68 Raw invalid=16383; numeric DBC decoders may still scale it: check raw before use.";
CM_ SG_ 820 CellVoltage064 "SUPPORTED_CAPTURE: coherent nonzero 108-cell sweeps; startup zero payloads are not valid battery readings. PSA-RE bits 7.5-8.0. Voltage of high-voltage battery cell 64 Raw invalid=16383; numeric DBC decoders may still scale it: check raw before use.";
CM_ SG_ 820 CellVoltage016 "SUPPORTED_CAPTURE: coherent nonzero 108-cell sweeps; startup zero payloads are not valid battery readings. PSA-RE bits 7.5-8.0. Voltage of high-voltage battery cell 16 Raw invalid=16383; numeric DBC decoders may still scale it: check raw before use.";
CM_ SG_ 820 CellVoltage072 "SUPPORTED_CAPTURE: coherent nonzero 108-cell sweeps; startup zero payloads are not valid battery readings. PSA-RE bits 7.5-8.0. Voltage of high-voltage battery cell 72 Raw invalid=16383; numeric DBC decoders may still scale it: check raw before use.";
CM_ SG_ 820 CellVoltage060 "SUPPORTED_CAPTURE: coherent nonzero 108-cell sweeps; startup zero payloads are not valid battery readings. PSA-RE bits 7.5-8.0. Voltage of high-voltage battery cell 60 Raw invalid=16383; numeric DBC decoders may still scale it: check raw before use.";
CM_ SG_ 820 CellVoltage056 "SUPPORTED_CAPTURE: coherent nonzero 108-cell sweeps; startup zero payloads are not valid battery readings. PSA-RE bits 7.5-8.0. Voltage of high-voltage battery cell 56 Raw invalid=16383; numeric DBC decoders may still scale it: check raw before use.";
CM_ SG_ 820 CellVoltage084 "SUPPORTED_CAPTURE: coherent nonzero 108-cell sweeps; startup zero payloads are not valid battery readings. PSA-RE bits 7.5-8.0. Voltage of high-voltage battery cell 84 Raw invalid=16383; numeric DBC decoders may still scale it: check raw before use.";
CM_ SG_ 820 CellVoltage004 "SUPPORTED_CAPTURE: coherent nonzero 108-cell sweeps; startup zero payloads are not valid battery readings. PSA-RE bits 7.5-8.0. Voltage of high-voltage battery cell 4 Raw invalid=16383; numeric DBC decoders may still scale it: check raw before use.";
CM_ SG_ 820 CellVoltage052 "SUPPORTED_CAPTURE: coherent nonzero 108-cell sweeps; startup zero payloads are not valid battery readings. PSA-RE bits 7.5-8.0. Voltage of high-voltage battery cell 52 Raw invalid=16383; numeric DBC decoders may still scale it: check raw before use.";
CM_ SG_ 820 CellVoltage012 "SUPPORTED_CAPTURE: coherent nonzero 108-cell sweeps; startup zero payloads are not valid battery readings. PSA-RE bits 7.5-8.0. Voltage of high-voltage battery cell 12 Raw invalid=16383; numeric DBC decoders may still scale it: check raw before use.";
CM_ SG_ 820 CellVoltage008 "SUPPORTED_CAPTURE: coherent nonzero 108-cell sweeps; startup zero payloads are not valid battery readings. PSA-RE bits 7.5-8.0. Voltage of high-voltage battery cell 8 Raw invalid=16383; numeric DBC decoders may still scale it: check raw before use.";
CM_ SG_ 820 CellVoltage048 "SUPPORTED_CAPTURE: coherent nonzero 108-cell sweeps; startup zero payloads are not valid battery readings. PSA-RE bits 7.5-8.0. Voltage of high-voltage battery cell 48 Raw invalid=16383; numeric DBC decoders may still scale it: check raw before use.";
CM_ SG_ 820 CellVoltage080 "SUPPORTED_CAPTURE: coherent nonzero 108-cell sweeps; startup zero payloads are not valid battery readings. PSA-RE bits 7.5-8.0. Voltage of high-voltage battery cell 80 Raw invalid=16383; numeric DBC decoders may still scale it: check raw before use.";
CM_ SG_ 820 CellVoltage036 "SUPPORTED_CAPTURE: coherent nonzero 108-cell sweeps; startup zero payloads are not valid battery readings. PSA-RE bits 7.5-8.0. Voltage of high-voltage battery cell 36 Raw invalid=16383; numeric DBC decoders may still scale it: check raw before use.";
CM_ SG_ 820 CellVoltage076 "SUPPORTED_CAPTURE: coherent nonzero 108-cell sweeps; startup zero payloads are not valid battery readings. PSA-RE bits 7.5-8.0. Voltage of high-voltage battery cell 76 Raw invalid=16383; numeric DBC decoders may still scale it: check raw before use.";
CM_ SG_ 820 CellVoltage100 "SUPPORTED_CAPTURE: coherent nonzero 108-cell sweeps; startup zero payloads are not valid battery readings. PSA-RE bits 7.5-8.0. Voltage of high-voltage battery cell 100 Raw invalid=16383; numeric DBC decoders may still scale it: check raw before use.";
CM_ SG_ 820 CellVoltage096 "SUPPORTED_CAPTURE: coherent nonzero 108-cell sweeps; startup zero payloads are not valid battery readings. PSA-RE bits 7.5-8.0. Voltage of high-voltage battery cell 96 Raw invalid=16383; numeric DBC decoders may still scale it: check raw before use.";
CM_ SG_ 820 CellVoltage032 "SUPPORTED_CAPTURE: coherent nonzero 108-cell sweeps; startup zero payloads are not valid battery readings. PSA-RE bits 7.5-8.0. Voltage of high-voltage battery cell 32 Raw invalid=16383; numeric DBC decoders may still scale it: check raw before use.";
CM_ SG_ 820 CellVoltage028 "SUPPORTED_CAPTURE: coherent nonzero 108-cell sweeps; startup zero payloads are not valid battery readings. PSA-RE bits 7.5-8.0. Voltage of high-voltage battery cell 28 Raw invalid=16383; numeric DBC decoders may still scale it: check raw before use.";
CM_ SG_ 820 CellVoltage024 "SUPPORTED_CAPTURE: coherent nonzero 108-cell sweeps; startup zero payloads are not valid battery readings. PSA-RE bits 7.5-8.0. Voltage of high-voltage battery cell 24 Raw invalid=16383; numeric DBC decoders may still scale it: check raw before use.";
CM_ SG_ 820 RawByte7_Mux27_28_29_30_31 "RAW. PSA-RE bits 7.7-7.0. Raw unmapped/padding bits; no physical interpretation.";
CM_ SG_ 820 RawByte6_Mux27_28_29_30_31 "RAW. PSA-RE bits 6.7-6.0. Raw unmapped/padding bits; no physical interpretation.";
CM_ SG_ 820 CellVoltage031 "SUPPORTED_CAPTURE: coherent nonzero 108-cell sweeps; startup zero payloads are not valid battery readings. PSA-RE bits 5.3-7.6. Voltage of high-voltage battery cell 31 Raw invalid=16383; numeric DBC decoders may still scale it: check raw before use.";
CM_ SG_ 820 CellVoltage043 "SUPPORTED_CAPTURE: coherent nonzero 108-cell sweeps; startup zero payloads are not valid battery readings. PSA-RE bits 5.3-7.6. Voltage of high-voltage battery cell 43 Raw invalid=16383; numeric DBC decoders may still scale it: check raw before use.";
CM_ SG_ 820 CellVoltage091 "SUPPORTED_CAPTURE: coherent nonzero 108-cell sweeps; startup zero payloads are not valid battery readings. PSA-RE bits 5.3-7.6. Voltage of high-voltage battery cell 91 Raw invalid=16383; numeric DBC decoders may still scale it: check raw before use.";
CM_ SG_ 820 CellVoltage019 "SUPPORTED_CAPTURE: coherent nonzero 108-cell sweeps; startup zero payloads are not valid battery readings. PSA-RE bits 5.3-7.6. Voltage of high-voltage battery cell 19 Raw invalid=16383; numeric DBC decoders may still scale it: check raw before use.";
CM_ SG_ 820 CellVoltage087 "SUPPORTED_CAPTURE: coherent nonzero 108-cell sweeps; startup zero payloads are not valid battery readings. PSA-RE bits 5.3-7.6. Voltage of high-voltage battery cell 87 Raw invalid=16383; numeric DBC decoders may still scale it: check raw before use.";
CM_ SG_ 820 CellVoltage107 "SUPPORTED_CAPTURE: coherent nonzero 108-cell sweeps; startup zero payloads are not valid battery readings. PSA-RE bits 5.3-7.6. Voltage of high-voltage battery cell 107 Raw invalid=16383; numeric DBC decoders may still scale it: check raw before use.";
CM_ SG_ 820 CellVoltage067 "SUPPORTED_CAPTURE: coherent nonzero 108-cell sweeps; startup zero payloads are not valid battery readings. PSA-RE bits 5.3-7.6. Voltage of high-voltage battery cell 67 Raw invalid=16383; numeric DBC decoders may still scale it: check raw before use.";
CM_ SG_ 820 CellVoltage063 "SUPPORTED_CAPTURE: coherent nonzero 108-cell sweeps; startup zero payloads are not valid battery readings. PSA-RE bits 5.3-7.6. Voltage of high-voltage battery cell 63 Raw invalid=16383; numeric DBC decoders may still scale it: check raw before use.";
CM_ SG_ 820 CellVoltage015 "SUPPORTED_CAPTURE: coherent nonzero 108-cell sweeps; startup zero payloads are not valid battery readings. PSA-RE bits 5.3-7.6. Voltage of high-voltage battery cell 15 Raw invalid=16383; numeric DBC decoders may still scale it: check raw before use.";
CM_ SG_ 820 CellVoltage071 "SUPPORTED_CAPTURE: coherent nonzero 108-cell sweeps; startup zero payloads are not valid battery readings. PSA-RE bits 5.3-7.6. Voltage of high-voltage battery cell 71 Raw invalid=16383; numeric DBC decoders may still scale it: check raw before use.";
CM_ SG_ 820 CellVoltage059 "SUPPORTED_CAPTURE: coherent nonzero 108-cell sweeps; startup zero payloads are not valid battery readings. PSA-RE bits 5.3-7.6. Voltage of high-voltage battery cell 59 Raw invalid=16383; numeric DBC decoders may still scale it: check raw before use.";
CM_ SG_ 820 CellVoltage083 "SUPPORTED_CAPTURE: coherent nonzero 108-cell sweeps; startup zero payloads are not valid battery readings. PSA-RE bits 5.3-7.6. Voltage of high-voltage battery cell 83 Raw invalid=16383; numeric DBC decoders may still scale it: check raw before use.";
CM_ SG_ 820 CellVoltage007 "SUPPORTED_CAPTURE: coherent nonzero 108-cell sweeps; startup zero payloads are not valid battery readings. PSA-RE bits 5.3-7.6. Voltage of high-voltage battery cell 7 Raw invalid=16383; numeric DBC decoders may still scale it: check raw before use.";
CM_ SG_ 820 CellVoltage051 "SUPPORTED_CAPTURE: coherent nonzero 108-cell sweeps; startup zero payloads are not valid battery readings. PSA-RE bits 5.3-7.6. Voltage of high-voltage battery cell 51 Raw invalid=16383; numeric DBC decoders may still scale it: check raw before use.";
CM_ SG_ 820 CellVoltage039 "SUPPORTED_CAPTURE: coherent nonzero 108-cell sweeps; startup zero payloads are not valid battery readings. PSA-RE bits 5.3-7.6. Voltage of high-voltage battery cell 39 Raw invalid=16383; numeric DBC decoders may still scale it: check raw before use.";
CM_ SG_ 820 CellVoltage011 "SUPPORTED_CAPTURE: coherent nonzero 108-cell sweeps; startup zero payloads are not valid battery readings. PSA-RE bits 5.3-7.6. Voltage of high-voltage battery cell 11 Raw invalid=16383; numeric DBC decoders may still scale it: check raw before use.";
CM_ SG_ 820 CellVoltage079 "SUPPORTED_CAPTURE: coherent nonzero 108-cell sweeps; startup zero payloads are not valid battery readings. PSA-RE bits 5.3-7.6. Voltage of high-voltage battery cell 79 Raw invalid=16383; numeric DBC decoders may still scale it: check raw before use.";
CM_ SG_ 820 CellVoltage035 "SUPPORTED_CAPTURE: coherent nonzero 108-cell sweeps; startup zero payloads are not valid battery readings. PSA-RE bits 5.3-7.6. Voltage of high-voltage battery cell 35 Raw invalid=16383; numeric DBC decoders may still scale it: check raw before use.";
CM_ SG_ 820 CellVoltage003 "SUPPORTED_CAPTURE: coherent nonzero 108-cell sweeps; startup zero payloads are not valid battery readings. PSA-RE bits 5.3-7.6. Voltage of high-voltage battery cell 3 Raw invalid=16383; numeric DBC decoders may still scale it: check raw before use.";
CM_ SG_ 820 CellVoltage055 "SUPPORTED_CAPTURE: coherent nonzero 108-cell sweeps; startup zero payloads are not valid battery readings. PSA-RE bits 5.3-7.6. Voltage of high-voltage battery cell 55 Raw invalid=16383; numeric DBC decoders may still scale it: check raw before use.";
CM_ SG_ 820 CellVoltage023 "SUPPORTED_CAPTURE: coherent nonzero 108-cell sweeps; startup zero payloads are not valid battery readings. PSA-RE bits 5.3-7.6. Voltage of high-voltage battery cell 23 Raw invalid=16383; numeric DBC decoders may still scale it: check raw before use.";
CM_ SG_ 820 CellVoltage075 "SUPPORTED_CAPTURE: coherent nonzero 108-cell sweeps; startup zero payloads are not valid battery readings. PSA-RE bits 5.3-7.6. Voltage of high-voltage battery cell 75 Raw invalid=16383; numeric DBC decoders may still scale it: check raw before use.";
CM_ SG_ 820 CellVoltage103 "SUPPORTED_CAPTURE: coherent nonzero 108-cell sweeps; startup zero payloads are not valid battery readings. PSA-RE bits 5.3-7.6. Voltage of high-voltage battery cell 103 Raw invalid=16383; numeric DBC decoders may still scale it: check raw before use.";
CM_ SG_ 820 CellVoltage099 "SUPPORTED_CAPTURE: coherent nonzero 108-cell sweeps; startup zero payloads are not valid battery readings. PSA-RE bits 5.3-7.6. Voltage of high-voltage battery cell 99 Raw invalid=16383; numeric DBC decoders may still scale it: check raw before use.";
CM_ SG_ 820 CellVoltage095 "SUPPORTED_CAPTURE: coherent nonzero 108-cell sweeps; startup zero payloads are not valid battery readings. PSA-RE bits 5.3-7.6. Voltage of high-voltage battery cell 95 Raw invalid=16383; numeric DBC decoders may still scale it: check raw before use.";
CM_ SG_ 820 CellVoltage047 "SUPPORTED_CAPTURE: coherent nonzero 108-cell sweeps; startup zero payloads are not valid battery readings. PSA-RE bits 5.3-7.6. Voltage of high-voltage battery cell 47 Raw invalid=16383; numeric DBC decoders may still scale it: check raw before use.";
CM_ SG_ 820 CellVoltage027 "SUPPORTED_CAPTURE: coherent nonzero 108-cell sweeps; startup zero payloads are not valid battery readings. PSA-RE bits 5.3-7.6. Voltage of high-voltage battery cell 27 Raw invalid=16383; numeric DBC decoders may still scale it: check raw before use.";
CM_ SG_ 820 RawByte5_Mux27_28_29_30_31 "RAW. PSA-RE bits 5.7-5.0. Raw unmapped/padding bits; no physical interpretation.";
CM_ SG_ 820 RawByte4_Mux27_28_29_30_31 "RAW. PSA-RE bits 4.7-4.0. Raw unmapped/padding bits; no physical interpretation.";
CM_ SG_ 820 CellVoltage030 "SUPPORTED_CAPTURE: coherent nonzero 108-cell sweeps; startup zero payloads are not valid battery readings. PSA-RE bits 3.1-5.4. Voltage of high-voltage battery cell 30 Raw invalid=16383; numeric DBC decoders may still scale it: check raw before use.";
CM_ SG_ 820 CellVoltage042 "SUPPORTED_CAPTURE: coherent nonzero 108-cell sweeps; startup zero payloads are not valid battery readings. PSA-RE bits 3.1-5.4. Voltage of high-voltage battery cell 42 Raw invalid=16383; numeric DBC decoders may still scale it: check raw before use.";
CM_ SG_ 820 CellVoltage022 "SUPPORTED_CAPTURE: coherent nonzero 108-cell sweeps; startup zero payloads are not valid battery readings. PSA-RE bits 3.1-5.4. Voltage of high-voltage battery cell 22 Raw invalid=16383; numeric DBC decoders may still scale it: check raw before use.";
CM_ SG_ 820 CellVoltage018 "SUPPORTED_CAPTURE: coherent nonzero 108-cell sweeps; startup zero payloads are not valid battery readings. PSA-RE bits 3.1-5.4. Voltage of high-voltage battery cell 18 Raw invalid=16383; numeric DBC decoders may still scale it: check raw before use.";
CM_ SG_ 820 CellVoltage090 "SUPPORTED_CAPTURE: coherent nonzero 108-cell sweeps; startup zero payloads are not valid battery readings. PSA-RE bits 3.1-5.4. Voltage of high-voltage battery cell 90 Raw invalid=16383; numeric DBC decoders may still scale it: check raw before use.";
CM_ SG_ 820 CellVoltage106 "SUPPORTED_CAPTURE: coherent nonzero 108-cell sweeps; startup zero payloads are not valid battery readings. PSA-RE bits 3.1-5.4. Voltage of high-voltage battery cell 106 Raw invalid=16383; numeric DBC decoders may still scale it: check raw before use.";
CM_ SG_ 820 CellVoltage066 "SUPPORTED_CAPTURE: coherent nonzero 108-cell sweeps; startup zero payloads are not valid battery readings. PSA-RE bits 3.1-5.4. Voltage of high-voltage battery cell 66 Raw invalid=16383; numeric DBC decoders may still scale it: check raw before use.";
CM_ SG_ 820 CellVoltage014 "SUPPORTED_CAPTURE: coherent nonzero 108-cell sweeps; startup zero payloads are not valid battery readings. PSA-RE bits 3.1-5.4. Voltage of high-voltage battery cell 14 Raw invalid=16383; numeric DBC decoders may still scale it: check raw before use.";
CM_ SG_ 820 CellVoltage074 "SUPPORTED_CAPTURE: coherent nonzero 108-cell sweeps; startup zero payloads are not valid battery readings. PSA-RE bits 3.1-5.4. Voltage of high-voltage battery cell 74 Raw invalid=16383; numeric DBC decoders may still scale it: check raw before use.";
CM_ SG_ 820 CellVoltage070 "SUPPORTED_CAPTURE: coherent nonzero 108-cell sweeps; startup zero payloads are not valid battery readings. PSA-RE bits 3.1-5.4. Voltage of high-voltage battery cell 70 Raw invalid=16383; numeric DBC decoders may still scale it: check raw before use.";
CM_ SG_ 820 CellVoltage062 "SUPPORTED_CAPTURE: coherent nonzero 108-cell sweeps; startup zero payloads are not valid battery readings. PSA-RE bits 3.1-5.4. Voltage of high-voltage battery cell 62 Raw invalid=16383; numeric DBC decoders may still scale it: check raw before use.";
CM_ SG_ 820 CellVoltage058 "SUPPORTED_CAPTURE: coherent nonzero 108-cell sweeps; startup zero payloads are not valid battery readings. PSA-RE bits 3.1-5.4. Voltage of high-voltage battery cell 58 Raw invalid=16383; numeric DBC decoders may still scale it: check raw before use.";
CM_ SG_ 820 CellVoltage086 "SUPPORTED_CAPTURE: coherent nonzero 108-cell sweeps; startup zero payloads are not valid battery readings. PSA-RE bits 3.1-5.4. Voltage of high-voltage battery cell 86 Raw invalid=16383; numeric DBC decoders may still scale it: check raw before use.";
CM_ SG_ 820 CellVoltage006 "SUPPORTED_CAPTURE: coherent nonzero 108-cell sweeps; startup zero payloads are not valid battery readings. PSA-RE bits 3.1-5.4. Voltage of high-voltage battery cell 6 Raw invalid=16383; numeric DBC decoders may still scale it: check raw before use.";
CM_ SG_ 820 CellVoltage054 "SUPPORTED_CAPTURE: coherent nonzero 108-cell sweeps; startup zero payloads are not valid battery readings. PSA-RE bits 3.1-5.4. Voltage of high-voltage battery cell 54 Raw invalid=16383; numeric DBC decoders may still scale it: check raw before use.";
CM_ SG_ 820 CellVoltage050 "SUPPORTED_CAPTURE: coherent nonzero 108-cell sweeps; startup zero payloads are not valid battery readings. PSA-RE bits 3.1-5.4. Voltage of high-voltage battery cell 50 Raw invalid=16383; numeric DBC decoders may still scale it: check raw before use.";
CM_ SG_ 820 CellVoltage038 "SUPPORTED_CAPTURE: coherent nonzero 108-cell sweeps; startup zero payloads are not valid battery readings. PSA-RE bits 3.1-5.4. Voltage of high-voltage battery cell 38 Raw invalid=16383; numeric DBC decoders may still scale it: check raw before use.";
CM_ SG_ 820 CellVoltage010 "SUPPORTED_CAPTURE: coherent nonzero 108-cell sweeps; startup zero payloads are not valid battery readings. PSA-RE bits 3.1-5.4. Voltage of high-voltage battery cell 10 Raw invalid=16383; numeric DBC decoders may still scale it: check raw before use.";
CM_ SG_ 820 CellVoltage082 "SUPPORTED_CAPTURE: coherent nonzero 108-cell sweeps; startup zero payloads are not valid battery readings. PSA-RE bits 3.1-5.4. Voltage of high-voltage battery cell 82 Raw invalid=16383; numeric DBC decoders may still scale it: check raw before use.";
CM_ SG_ 820 CellVoltage094 "SUPPORTED_CAPTURE: coherent nonzero 108-cell sweeps; startup zero payloads are not valid battery readings. PSA-RE bits 3.1-5.4. Voltage of high-voltage battery cell 94 Raw invalid=16383; numeric DBC decoders may still scale it: check raw before use.";
CM_ SG_ 820 CellVoltage034 "SUPPORTED_CAPTURE: coherent nonzero 108-cell sweeps; startup zero payloads are not valid battery readings. PSA-RE bits 3.1-5.4. Voltage of high-voltage battery cell 34 Raw invalid=16383; numeric DBC decoders may still scale it: check raw before use.";
CM_ SG_ 820 CellVoltage002 "SUPPORTED_CAPTURE: coherent nonzero 108-cell sweeps; startup zero payloads are not valid battery readings. PSA-RE bits 3.1-5.4. Voltage of high-voltage battery cell 2 Raw invalid=16383; numeric DBC decoders may still scale it: check raw before use.";
CM_ SG_ 820 CellVoltage078 "SUPPORTED_CAPTURE: coherent nonzero 108-cell sweeps; startup zero payloads are not valid battery readings. PSA-RE bits 3.1-5.4. Voltage of high-voltage battery cell 78 Raw invalid=16383; numeric DBC decoders may still scale it: check raw before use.";
CM_ SG_ 820 CellVoltage102 "SUPPORTED_CAPTURE: coherent nonzero 108-cell sweeps; startup zero payloads are not valid battery readings. PSA-RE bits 3.1-5.4. Voltage of high-voltage battery cell 102 Raw invalid=16383; numeric DBC decoders may still scale it: check raw before use.";
CM_ SG_ 820 CellVoltage098 "SUPPORTED_CAPTURE: coherent nonzero 108-cell sweeps; startup zero payloads are not valid battery readings. PSA-RE bits 3.1-5.4. Voltage of high-voltage battery cell 98 Raw invalid=16383; numeric DBC decoders may still scale it: check raw before use.";
CM_ SG_ 820 CellVoltage046 "SUPPORTED_CAPTURE: coherent nonzero 108-cell sweeps; startup zero payloads are not valid battery readings. PSA-RE bits 3.1-5.4. Voltage of high-voltage battery cell 46 Raw invalid=16383; numeric DBC decoders may still scale it: check raw before use.";
CM_ SG_ 820 CellVoltage026 "SUPPORTED_CAPTURE: coherent nonzero 108-cell sweeps; startup zero payloads are not valid battery readings. PSA-RE bits 3.1-5.4. Voltage of high-voltage battery cell 26 Raw invalid=16383; numeric DBC decoders may still scale it: check raw before use.";
CM_ SG_ 820 RawByte3_Mux27_28_29_30_31 "RAW. PSA-RE bits 3.7-3.0. Raw unmapped/padding bits; no physical interpretation.";
CM_ SG_ 820 RawByte2_Mux27_28_29_30_31 "RAW. PSA-RE bits 2.7-2.0. Raw unmapped/padding bits; no physical interpretation.";
CM_ SG_ 820 CellVoltage029 "SUPPORTED_CAPTURE: coherent nonzero 108-cell sweeps; startup zero payloads are not valid battery readings. PSA-RE bits 2.7-3.2. Voltage of high-voltage battery cell 29 Raw invalid=16383; numeric DBC decoders may still scale it: check raw before use.";
CM_ SG_ 820 CellVoltage041 "SUPPORTED_CAPTURE: coherent nonzero 108-cell sweeps; startup zero payloads are not valid battery readings. PSA-RE bits 2.7-3.2. Voltage of high-voltage battery cell 41 Raw invalid=16383; numeric DBC decoders may still scale it: check raw before use.";
CM_ SG_ 820 CellVoltage021 "SUPPORTED_CAPTURE: coherent nonzero 108-cell sweeps; startup zero payloads are not valid battery readings. PSA-RE bits 2.7-3.2. Voltage of high-voltage battery cell 21 Raw invalid=16383; numeric DBC decoders may still scale it: check raw before use.";
CM_ SG_ 820 CellVoltage069 "SUPPORTED_CAPTURE: coherent nonzero 108-cell sweeps; startup zero payloads are not valid battery readings. PSA-RE bits 2.7-3.2. Voltage of high-voltage battery cell 69 Raw invalid=16383; numeric DBC decoders may still scale it: check raw before use.";
CM_ SG_ 820 CellVoltage105 "SUPPORTED_CAPTURE: coherent nonzero 108-cell sweeps; startup zero payloads are not valid battery readings. PSA-RE bits 2.7-3.2. Voltage of high-voltage battery cell 105 Raw invalid=16383; numeric DBC decoders may still scale it: check raw before use.";
CM_ SG_ 820 CellVoltage065 "SUPPORTED_CAPTURE: coherent nonzero 108-cell sweeps; startup zero payloads are not valid battery readings. PSA-RE bits 2.7-3.2. Voltage of high-voltage battery cell 65 Raw invalid=16383; numeric DBC decoders may still scale it: check raw before use.";
CM_ SG_ 820 CellVoltage017 "SUPPORTED_CAPTURE: coherent nonzero 108-cell sweeps; startup zero payloads are not valid battery readings. PSA-RE bits 2.7-3.2. Voltage of high-voltage battery cell 17 Raw invalid=16383; numeric DBC decoders may still scale it: check raw before use.";
CM_ SG_ 820 CellVoltage073 "SUPPORTED_CAPTURE: coherent nonzero 108-cell sweeps; startup zero payloads are not valid battery readings. PSA-RE bits 2.7-3.2. Voltage of high-voltage battery cell 73 Raw invalid=16383; numeric DBC decoders may still scale it: check raw before use.";
CM_ SG_ 820 CellVoltage061 "SUPPORTED_CAPTURE: coherent nonzero 108-cell sweeps; startup zero payloads are not valid battery readings. PSA-RE bits 2.7-3.2. Voltage of high-voltage battery cell 61 Raw invalid=16383; numeric DBC decoders may still scale it: check raw before use.";
CM_ SG_ 820 CellVoltage057 "SUPPORTED_CAPTURE: coherent nonzero 108-cell sweeps; startup zero payloads are not valid battery readings. PSA-RE bits 2.7-3.2. Voltage of high-voltage battery cell 57 Raw invalid=16383; numeric DBC decoders may still scale it: check raw before use.";
CM_ SG_ 820 CellVoltage085 "SUPPORTED_CAPTURE: coherent nonzero 108-cell sweeps; startup zero payloads are not valid battery readings. PSA-RE bits 2.7-3.2. Voltage of high-voltage battery cell 85 Raw invalid=16383; numeric DBC decoders may still scale it: check raw before use.";
CM_ SG_ 820 CellVoltage005 "SUPPORTED_CAPTURE: coherent nonzero 108-cell sweeps; startup zero payloads are not valid battery readings. PSA-RE bits 2.7-3.2. Voltage of high-voltage battery cell 5 Raw invalid=16383; numeric DBC decoders may still scale it: check raw before use.";
CM_ SG_ 820 CellVoltage053 "SUPPORTED_CAPTURE: coherent nonzero 108-cell sweeps; startup zero payloads are not valid battery readings. PSA-RE bits 2.7-3.2. Voltage of high-voltage battery cell 53 Raw invalid=16383; numeric DBC decoders may still scale it: check raw before use.";
CM_ SG_ 820 CellVoltage037 "SUPPORTED_CAPTURE: coherent nonzero 108-cell sweeps; startup zero payloads are not valid battery readings. PSA-RE bits 2.7-3.2. Voltage of high-voltage battery cell 37 Raw invalid=16383; numeric DBC decoders may still scale it: check raw before use.";
CM_ SG_ 820 CellVoltage013 "SUPPORTED_CAPTURE: coherent nonzero 108-cell sweeps; startup zero payloads are not valid battery readings. PSA-RE bits 2.7-3.2. Voltage of high-voltage battery cell 13 Raw invalid=16383; numeric DBC decoders may still scale it: check raw before use.";
CM_ SG_ 820 CellVoltage009 "SUPPORTED_CAPTURE: coherent nonzero 108-cell sweeps; startup zero payloads are not valid battery readings. PSA-RE bits 2.7-3.2. Voltage of high-voltage battery cell 9 Raw invalid=16383; numeric DBC decoders may still scale it: check raw before use.";
CM_ SG_ 820 CellVoltage049 "SUPPORTED_CAPTURE: coherent nonzero 108-cell sweeps; startup zero payloads are not valid battery readings. PSA-RE bits 2.7-3.2. Voltage of high-voltage battery cell 49 Raw invalid=16383; numeric DBC decoders may still scale it: check raw before use.";
CM_ SG_ 820 CellVoltage081 "SUPPORTED_CAPTURE: coherent nonzero 108-cell sweeps; startup zero payloads are not valid battery readings. PSA-RE bits 2.7-3.2. Voltage of high-voltage battery cell 81 Raw invalid=16383; numeric DBC decoders may still scale it: check raw before use.";
CM_ SG_ 820 CellVoltage093 "SUPPORTED_CAPTURE: coherent nonzero 108-cell sweeps; startup zero payloads are not valid battery readings. PSA-RE bits 2.7-3.2. Voltage of high-voltage battery cell 93 Raw invalid=16383; numeric DBC decoders may still scale it: check raw before use.";
CM_ SG_ 820 CellVoltage001 "SUPPORTED_CAPTURE: coherent nonzero 108-cell sweeps; startup zero payloads are not valid battery readings. PSA-RE bits 2.7-3.2. Voltage of high-voltage battery cell 1 Raw invalid=16383; numeric DBC decoders may still scale it: check raw before use.";
CM_ SG_ 820 CellVoltage089 "SUPPORTED_CAPTURE: coherent nonzero 108-cell sweeps; startup zero payloads are not valid battery readings. PSA-RE bits 2.7-3.2. Voltage of high-voltage battery cell 89 Raw invalid=16383; numeric DBC decoders may still scale it: check raw before use.";
CM_ SG_ 820 CellVoltage077 "SUPPORTED_CAPTURE: coherent nonzero 108-cell sweeps; startup zero payloads are not valid battery readings. PSA-RE bits 2.7-3.2. Voltage of high-voltage battery cell 77 Raw invalid=16383; numeric DBC decoders may still scale it: check raw before use.";
CM_ SG_ 820 CellVoltage101 "SUPPORTED_CAPTURE: coherent nonzero 108-cell sweeps; startup zero payloads are not valid battery readings. PSA-RE bits 2.7-3.2. Voltage of high-voltage battery cell 101 Raw invalid=16383; numeric DBC decoders may still scale it: check raw before use.";
CM_ SG_ 820 CellVoltage097 "SUPPORTED_CAPTURE: coherent nonzero 108-cell sweeps; startup zero payloads are not valid battery readings. PSA-RE bits 2.7-3.2. Voltage of high-voltage battery cell 97 Raw invalid=16383; numeric DBC decoders may still scale it: check raw before use.";
CM_ SG_ 820 CellVoltage033 "SUPPORTED_CAPTURE: coherent nonzero 108-cell sweeps; startup zero payloads are not valid battery readings. PSA-RE bits 2.7-3.2. Voltage of high-voltage battery cell 33 Raw invalid=16383; numeric DBC decoders may still scale it: check raw before use.";
CM_ SG_ 820 CellVoltage045 "SUPPORTED_CAPTURE: coherent nonzero 108-cell sweeps; startup zero payloads are not valid battery readings. PSA-RE bits 2.7-3.2. Voltage of high-voltage battery cell 45 Raw invalid=16383; numeric DBC decoders may still scale it: check raw before use.";
CM_ SG_ 820 CellVoltage025 "SUPPORTED_CAPTURE: coherent nonzero 108-cell sweeps; startup zero payloads are not valid battery readings. PSA-RE bits 2.7-3.2. Voltage of high-voltage battery cell 25 Raw invalid=16383; numeric DBC decoders may still scale it: check raw before use.";
CM_ SG_ 820 RawBits5_7 "RAW. PSA-RE bits 1.2-1.0. Raw unmapped/padding bits; no physical interpretation.";
CM_ SG_ 820 CellGroup "SUPPORTED_CAPTURE: coherent nonzero 108-cell sweeps; startup zero payloads are not valid battery readings. PSA-RE bits 1.7-1.3. Index of the group of battery cell voltage signals currently transmitted";
CM_ BO_ 840 "Observed OBD 6/14 HS1. CAN ID 0x348; ID_DLC_match. PSA-RE name: ENGINE_ECU_STATUS_HEV. Engine ECU status, transmitted in every configuration: traction/motion control acquisition, OBD contact state, engine running state, warm-up cycle completion, refrigerant pressure and MIL lamp request. Source: https://github.com/prototux/PSA-RE/blob/67f7581e7622410efdbb29c7eda3b86982b9b450/buses/AEE2010.full/HS.HS1/348.yml. Database sender alternatives: CMM,E_VCU. ECU labels are database claims; forwarding/physical transmitter not independently identified. All fitting source fields retained, including default/unavailable-only candidates. See audit/source JSON for exclusions and unresolved alternatives.";
CM_ SG_ 840 ProcessCounter "DATABASE_CANDIDATE: layout imported; physical meaning not independently verified. PSA-RE bits 8.3-8.0. 4-bit process counter Upstream default raw=0 (not necessarily valid data).";
CM_ SG_ 840 FrameChecksum "DATABASE_CANDIDATE: layout imported; physical meaning not independently verified. PSA-RE bits 8.7-8.4. 4-bit checksum of the frame";
CM_ SG_ 840 Unused6 "DATABASE_CANDIDATE: layout imported; physical meaning not independently verified. PSA-RE bits 7.0. ";
CM_ SG_ 840 ObdFaultOnMilPresent "DATABASE_CANDIDATE: layout imported; physical meaning not independently verified. PSA-RE bits 7.1. OBD fault signalled on the MIL lamp Upstream default raw=0 (not necessarily valid data).";
CM_ SG_ 840 MilLampSteadyRequest "DATABASE_CANDIDATE: layout imported; physical meaning not independently verified. PSA-RE bits 7.2. MIL lamp steady lighting request Upstream default raw=0 (not necessarily valid data).";
CM_ SG_ 840 MilLampBlinkRequest "DATABASE_CANDIDATE: layout imported; physical meaning not independently verified. PSA-RE bits 7.3. MIL lamp blinking request Upstream default raw=0 (not necessarily valid data).";
CM_ SG_ 840 WarmUpCycleCompletedStatus "DATABASE_CANDIDATE: layout imported; physical meaning not independently verified. PSA-RE bits 7.4. Warm-up cycle completion status Upstream default raw=0 (not necessarily valid data).";
CM_ SG_ 840 DrivingCycleGlobalSyncStatus "DATABASE_CANDIDATE: layout imported; physical meaning not independently verified. PSA-RE bits 7.5. Global driving cycle synchronization status Upstream default raw=0 (not necessarily valid data).";
CM_ SG_ 840 ObdIgnitionContact "DATABASE_CANDIDATE: layout imported; physical meaning not independently verified. PSA-RE bits 7.6. Ignition contact state, as seen by OBD Upstream default raw=0 (not necessarily valid data).";
CM_ SG_ 840 Unused5 "DATABASE_CANDIDATE: layout imported; physical meaning not independently verified. PSA-RE bits 7.7. ";
CM_ SG_ 840 EngineRunning "DATABASE_CANDIDATE: layout imported; physical meaning not independently verified. PSA-RE bits 6.3-6.0. Engine running state Upstream default raw=1 (not necessarily valid data).";
CM_ SG_ 840 Unused4 "DATABASE_CANDIDATE: layout imported; physical meaning not independently verified. PSA-RE bits 6.4. ";
CM_ SG_ 840 RearAsrMsrAcknowledge "DATABASE_CANDIDATE: layout imported; physical meaning not independently verified. PSA-RE bits 6.5. Rear ASR / MSR communication acknowledge Upstream default raw=1 (not necessarily valid data).";
CM_ SG_ 840 Unused3 "DATABASE_CANDIDATE: layout imported; physical meaning not independently verified. PSA-RE bits 6.7-6.6. ";
CM_ SG_ 840 AsrMsrAcknowledge "DATABASE_CANDIDATE: layout imported; physical meaning not independently verified. PSA-RE bits 5.0. ASR / MSR (traction/engine drag control) communication acknowledge Upstream default raw=1 (not necessarily valid data).";
CM_ SG_ 840 Unused2 "DATABASE_CANDIDATE: layout imported; physical meaning not independently verified. PSA-RE bits 4.7-5.1. ";
CM_ SG_ 840 CoolingSystemPressure2 "DATABASE_CANDIDATE: layout imported; physical meaning not independently verified. PSA-RE bits 3.7-3.0. Cooling system pressure, sensor 2 Raw invalid=255; numeric DBC decoders may still scale it: check raw before use. Upstream default raw=255 (not necessarily valid data). Unresolved source alternatives: [{\"factor\": 11110, \"note\": \"Also observed with another scaling (factor 11110)\"}]";
CM_ SG_ 840 Unused1 "DATABASE_CANDIDATE: layout imported; physical meaning not independently verified. PSA-RE bits 1.7-2.0. ";
CM_ BO_ 841 "Observed OBD 6/14 HS1. CAN ID 0x349; ID_DLC_match. PSA-RE name: GEARBOX_SYNCHRONISATION_DATA_2. Automatic gearbox synchronisation data: requested engine torque/idle-speed setpoints, gear-change and torque-converter state. Source: https://github.com/prototux/PSA-RE/blob/67f7581e7622410efdbb29c7eda3b86982b9b450/buses/AEE2010.full/HS.HS1/349.yml. Database sender alternatives: BVA. ECU labels are database claims; forwarding/physical transmitter not independently identified. All fitting source fields retained, including default/unavailable-only candidates. See audit/source JSON for exclusions and unresolved alternatives.";
CM_ SG_ 841 EngineSpeedRegulationSetpoint "DATABASE_CANDIDATE: layout imported; physical meaning not independently verified. PSA-RE bits 8.7-8.0. Desired engine speed setpoint Upstream default raw=254 (not necessarily valid data). Unresolved source alternatives: [{\"factor\": 25750, \"note\": \"Also observed with another scaling (factor 25750)\"}]";
CM_ SG_ 841 ProcessCounter "DATABASE_CANDIDATE: layout imported; physical meaning not independently verified. PSA-RE bits 7.3-7.0. Rolling counter incremented at each calculation cycle Upstream default raw=0 (not necessarily valid data).";
CM_ SG_ 841 FrameChecksum "DATABASE_CANDIDATE: layout imported; physical meaning not independently verified. PSA-RE bits 7.7-7.4. Checksum of the frame";
CM_ SG_ 841 GearboxCouplingDeviceStatus "DATABASE_CANDIDATE: layout imported; physical meaning not independently verified. PSA-RE bits 6.1-6.0. Coupling device state Upstream default raw=0 (not necessarily valid data).";
CM_ SG_ 841 GearboxReductionState "DATABASE_CANDIDATE: layout imported; physical meaning not independently verified. PSA-RE bits 6.3-6.2. Gear reduction state Upstream default raw=0 (not necessarily valid data).";
CM_ SG_ 841 GearboxMechanicallyEngagedGear "DATABASE_CANDIDATE: layout imported; physical meaning not independently verified. PSA-RE bits 6.7-6.4. Gear mechanically engaged in the gearbox (effective gear) Upstream default raw=15 (not necessarily valid data).";
CM_ SG_ 841 GearboxMaxAdmissibleTorque "DATABASE_CANDIDATE: layout imported; physical meaning not independently verified. PSA-RE bits 5.7-5.0. Maximum torque admissible by the gearbox Raw invalid=255; numeric DBC decoders may still scale it: check raw before use. Upstream default raw=50 (not necessarily valid data).";
CM_ SG_ 841 GearPosition "SUPPORTED_CAPTURE: coherent changes across independent messages. PSA-RE bits 4.3-4.0. Gear selector lever position Upstream default raw=15 (not necessarily valid data).";
CM_ SG_ 841 GearboxTargetGear "DATABASE_CANDIDATE: layout imported; physical meaning not independently verified. PSA-RE bits 4.7-4.4. Automatic gearbox target gear Upstream default raw=15 (not necessarily valid data).";
CM_ SG_ 841 GearShiftInProgress "DATABASE_CANDIDATE: layout imported; physical meaning not independently verified. PSA-RE bits 3.0. Gearbox shifting in progress; can be used to display and/or inhibit other systems' strategies Upstream default raw=0 (not necessarily valid data).";
CM_ SG_ 841 TractionChainStateChangePhase "DATABASE_CANDIDATE: layout imported; physical meaning not independently verified. PSA-RE bits 3.1. Traction chain state-change phase in progress Upstream default raw=0 (not necessarily valid data).";
CM_ SG_ 841 GearboxTorqueConverterStatus "DATABASE_CANDIDATE: layout imported; physical meaning not independently verified. PSA-RE bits 3.3-3.2. Automatic gearbox torque converter status Upstream default raw=3 (not necessarily valid data).";
CM_ SG_ 841 AcCompressorInhibitGearshift "DATABASE_CANDIDATE: layout imported; physical meaning not independently verified. PSA-RE bits 3.4. AC compressor state change inhibited during gear shifting Upstream default raw=0 (not necessarily valid data).";
CM_ SG_ 841 EngineSpeedRegulationRequest "DATABASE_CANDIDATE: layout imported; physical meaning not independently verified. PSA-RE bits 3.5. Engine speed regulation requested Upstream default raw=0 (not necessarily valid data).";
CM_ SG_ 841 EngineSpeedRelaunchType "DATABASE_CANDIDATE: layout imported; physical meaning not independently verified. PSA-RE bits 3.6. Type of engine speed relaunch control Upstream default raw=0 (not necessarily valid data).";
CM_ SG_ 841 IdleSpeedIncreaseRequest "DATABASE_CANDIDATE: layout imported; physical meaning not independently verified. PSA-RE bits 3.7. Request from the gearbox to increase idle speed";
CM_ SG_ 841 GearboxTorqueRequestSetpoint "DATABASE_CANDIDATE: layout imported; physical meaning not independently verified. PSA-RE bits 2.7-2.0. Torque setpoint requested in the gearbox-engine torque dialog Upstream default raw=50 (not necessarily valid data).";
CM_ SG_ 841 GearboxDragReductionStatus "DATABASE_CANDIDATE: layout imported; physical meaning not independently verified. PSA-RE bits 1.1-1.0. Gearbox drag reduction status Upstream default raw=3 (not necessarily valid data).";
CM_ SG_ 841 GearShiftInProgressType "DATABASE_CANDIDATE: layout imported; physical meaning not independently verified. PSA-RE bits 1.4-1.2. Shift-in-progress (SIP) type Upstream default raw=3 (not necessarily valid data).";
CM_ SG_ 841 EngineTorqueTransmissionStatus "DATABASE_CANDIDATE: layout imported; physical meaning not independently verified. PSA-RE bits 1.5. Engine torque transmission status Upstream default raw=0 (not necessarily valid data).";
CM_ SG_ 841 RawBits1_1 "RAW. PSA-RE bits 1.6-1.6. Raw unmapped/padding bits; no physical interpretation.";
CM_ SG_ 841 AcCompressorCutoffRequestGearbox "DATABASE_CANDIDATE: layout imported; physical meaning not independently verified. PSA-RE bits 1.7. AC compressor cutoff request for gearbox torque management Upstream default raw=0 (not necessarily valid data).";
CM_ BO_ 845 "Observed OBD 6/14 HS1. CAN ID 0x34D; ID_DLC_match. PSA-RE name: ESP_SYNCHRONISATION_DATA. ESP synchronisation data: ESP disconnected, ASR+ state, hill-start assist state, ESP regulation and warning-lamp requests. Source: https://github.com/prototux/PSA-RE/blob/67f7581e7622410efdbb29c7eda3b86982b9b450/buses/AEE2010.full/HS.HS1/34D.yml. Database sender alternatives: ABS. ECU labels are database claims; forwarding/physical transmitter not independently identified. All fitting source fields retained, including default/unavailable-only candidates. See audit/source JSON for exclusions and unresolved alternatives.";
CM_ SG_ 845 StaticSlope "DATABASE_CANDIDATE: layout imported; physical meaning not independently verified. PSA-RE bits 8.5-8.0. Static road slope Raw invalid=63; numeric DBC decoders may still scale it: check raw before use. Upstream default raw=62 (not necessarily valid data).";
CM_ SG_ 845 Unused5 "DATABASE_CANDIDATE: layout imported; physical meaning not independently verified. PSA-RE bits 8.7-8.6. ";
CM_ SG_ 845 Unused4 "DATABASE_CANDIDATE: layout imported; physical meaning not independently verified. PSA-RE bits 7.0. ";
CM_ SG_ 845 BasrRegulationActive "DATABASE_CANDIDATE: layout imported; physical meaning not independently verified. PSA-RE bits 7.1. Brake-based traction control (BASR) regulation active Upstream default raw=0 (not necessarily valid data).";
CM_ SG_ 845 AsrRegulationActive "DATABASE_CANDIDATE: layout imported; physical meaning not independently verified. PSA-RE bits 7.2. ASR (traction control) regulation active Upstream default raw=0 (not necessarily valid data).";
CM_ SG_ 845 MsrRegulationActive "DATABASE_CANDIDATE: layout imported; physical meaning not independently verified. PSA-RE bits 7.3. MSR (engine drag torque control) regulation active Upstream default raw=0 (not necessarily valid data).";
CM_ SG_ 845 EspRegulationActive "DATABASE_CANDIDATE: layout imported; physical meaning not independently verified. PSA-RE bits 7.4. ESP regulation active Upstream default raw=0 (not necessarily valid data).";
CM_ SG_ 845 AfuRegulationActive "DATABASE_CANDIDATE: layout imported; physical meaning not independently verified. PSA-RE bits 7.5. Emergency brake assist (AFU) regulation active Upstream default raw=0 (not necessarily valid data).";
CM_ SG_ 845 Unused3 "DATABASE_CANDIDATE: layout imported; physical meaning not independently verified. PSA-RE bits 7.6. ";
CM_ SG_ 845 AsrEspRegulationLampRequest "DATABASE_CANDIDATE: layout imported; physical meaning not independently verified. PSA-RE bits 7.7. ASR-ESP regulation indicator lamp request Upstream default raw=0 (not necessarily valid data).";
CM_ SG_ 845 ProcessCounter4bit "DATABASE_CANDIDATE: layout imported; physical meaning not independently verified. PSA-RE bits 6.3-6.0. 4-bit process counter Upstream default raw=0 (not necessarily valid data).";
CM_ SG_ 845 Unused2 "DATABASE_CANDIDATE: layout imported; physical meaning not independently verified. PSA-RE bits 6.4. ";
CM_ SG_ 845 HillAssistStatus "DATABASE_CANDIDATE: layout imported; physical meaning not independently verified. PSA-RE bits 6.6-6.5. Hill Assist function status Upstream default raw=0 (not necessarily valid data).";
CM_ SG_ 845 Unused1 "DATABASE_CANDIDATE: layout imported; physical meaning not independently verified. PSA-RE bits 6.7. ";
CM_ SG_ 845 MsrTorqueSetpoint "DATABASE_CANDIDATE: layout imported; physical meaning not independently verified. PSA-RE bits 5.7-5.0. MSR (engine drag torque control) torque setpoint Upstream default raw=0 (not necessarily valid data).";
CM_ SG_ 845 AsrDynamicTorqueSetpoint "DATABASE_CANDIDATE: layout imported; physical meaning not independently verified. PSA-RE bits 4.7-4.0. ASR dynamic torque setpoint Upstream default raw=250 (not necessarily valid data).";
CM_ SG_ 845 AsrStaticTorqueSetpoint "DATABASE_CANDIDATE: layout imported; physical meaning not independently verified. PSA-RE bits 3.7-3.0. ASR static torque setpoint Upstream default raw=250 (not necessarily valid data).";
CM_ SG_ 845 GearChangeAuthorization "DATABASE_CANDIDATE: layout imported; physical meaning not independently verified. PSA-RE bits 2.1-2.0. Gear shift authorization (upshift/downshift) Upstream default raw=3 (not necessarily valid data).";
CM_ SG_ 845 BrakePrefillActive "DATABASE_CANDIDATE: layout imported; physical meaning not independently verified. PSA-RE bits 2.2. Brake prefill active";
CM_ SG_ 845 FarcDecelerationFunctionStatus "DATABASE_CANDIDATE: layout imported; physical meaning not independently verified. PSA-RE bits 2.4-2.3. FARC (adaptive cruise) deceleration function status Upstream default raw=0 (not necessarily valid data).";
CM_ SG_ 845 AsrPlusMode "DATABASE_CANDIDATE: layout imported; physical meaning not independently verified. PSA-RE bits 2.7-2.5. ASR+ mode (normal/snow/mud/sand/ESP off) Upstream default raw=1 (not necessarily valid data).";
CM_ SG_ 845 EspTorqueRequestStatus "DATABASE_CANDIDATE: layout imported; physical meaning not independently verified. PSA-RE bits 1.2-1.0. ESP torque request status (no action / ASR reduction / MSR increase) Upstream default raw=0 (not necessarily valid data).";
CM_ SG_ 845 AsrDisconnectStatus "DATABASE_CANDIDATE: layout imported; physical meaning not independently verified. PSA-RE bits 1.3. ASR connection status, as set by the driver Upstream default raw=0 (not necessarily valid data).";
CM_ SG_ 845 AsrEspFaultLampRequest "DATABASE_CANDIDATE: layout imported; physical meaning not independently verified. PSA-RE bits 1.4. ASR-ESP fault warning lamp request Upstream default raw=1 (not necessarily valid data).";
CM_ SG_ 845 GearboxVdcProgramRequest "DATABASE_CANDIDATE: layout imported; physical meaning not independently verified. PSA-RE bits 1.5. Request to switch the gearbox to the VDC (vehicle dynamic control) shift program Upstream default raw=0 (not necessarily valid data).";
CM_ SG_ 845 AsrEspRegulationActive "DATABASE_CANDIDATE: layout imported; physical meaning not independently verified. PSA-RE bits 1.6. ASR-ESP regulation active Upstream default raw=0 (not necessarily valid data).";
CM_ SG_ 845 AsrEspDisconnectStatus "DATABASE_CANDIDATE: layout imported; physical meaning not independently verified. PSA-RE bits 1.7. ASR-ESP connection status, as set by the driver Upstream default raw=0 (not necessarily valid data).";
CM_ BO_ 850 "Observed OBD 6/14 HS1. CAN ID 0x352; no_HS1_definition. PSA-RE name: unknown.  Source: none in HS.HS1. Database sender alternatives: unknown. ECU labels are database claims; forwarding/physical transmitter not independently identified. All fitting source fields retained, including default/unavailable-only candidates. See audit/source JSON for exclusions and unresolved alternatives.";
CM_ SG_ 850 RawByte2 "RAW. PSA-RE bits 2.7-2.0. Raw unmapped/padding bits; no physical interpretation.";
CM_ SG_ 850 RawByte1 "RAW. PSA-RE bits 1.7-1.0. Raw unmapped/padding bits; no physical interpretation.";
CM_ BO_ 877 "Observed OBD 6/14 HS1. CAN ID 0x36D; ID_DLC_match. PSA-RE name: BRAKE_DYNAMIC_DATA. Brake control unit data: hydraulic hold state, road-slope estimation and vehicle-motion-control status. Source: https://github.com/prototux/PSA-RE/blob/67f7581e7622410efdbb29c7eda3b86982b9b450/buses/AEE2010.full/HS.HS1/36D.yml. Database sender alternatives: ABS. ECU labels are database claims; forwarding/physical transmitter not independently identified. All fitting source fields retained, including default/unavailable-only candidates. See audit/source JSON for exclusions and unresolved alternatives.";
CM_ SG_ 877 Unused1 "DATABASE_CANDIDATE: layout imported; physical meaning not independently verified. PSA-RE bits 2.3-4.0. ";
CM_ SG_ 877 DynamicSlopeAccuracy "DATABASE_CANDIDATE: layout imported; physical meaning not independently verified. PSA-RE bits 2.5-2.4. Accuracy of the dynamically estimated road slope Upstream default raw=3 (not necessarily valid data).";
CM_ SG_ 877 DynamicSlopeValue "DATABASE_CANDIDATE: layout imported; physical meaning not independently verified. PSA-RE bits 1.3-2.6. Dynamically estimated road slope (%) Raw invalid=63; numeric DBC decoders may still scale it: check raw before use. Upstream default raw=62 (not necessarily valid data).";
CM_ SG_ 877 HydraulicHoldStatus "DATABASE_CANDIDATE: layout imported; physical meaning not independently verified. PSA-RE bits 1.4. Status of the hydraulic pressure level needed to hold the vehicle stationary Upstream default raw=0 (not necessarily valid data).";
CM_ SG_ 877 EscHydraulicFailure "DATABASE_CANDIDATE: layout imported; physical meaning not independently verified. PSA-RE bits 1.5. Vehicle cannot be secured due to lack of hydraulic availability Upstream default raw=0 (not necessarily valid data).";
CM_ SG_ 877 VmcStatus "DATABASE_CANDIDATE: layout imported; physical meaning not independently verified. PSA-RE bits 1.7-1.6. Status of longitudinal control by the braking system Upstream default raw=0 (not necessarily valid data).";
CM_ BO_ 909 "Observed OBD 6/14 HS1. CAN ID 0x38D; ID_DLC_match. PSA-RE name: VEHICLE_DYNAMICS_WHEELS. Vehicle speed, distance and longitudinal acceleration computed from the wheels, plus a warning-lamp request. Source: https://github.com/prototux/PSA-RE/blob/67f7581e7622410efdbb29c7eda3b86982b9b450/buses/AEE2010.full/HS.HS1/38D.yml. Database sender alternatives: ABS. ECU labels are database claims; forwarding/physical transmitter not independently identified. All fitting source fields retained, including default/unavailable-only candidates. See audit/source JSON for exclusions and unresolved alternatives.";
CM_ SG_ 909 Unused1 "DATABASE_CANDIDATE: layout imported; physical meaning not independently verified. PSA-RE bits 8.0. ";
CM_ SG_ 909 HadcFaultStatus "DATABASE_CANDIDATE: layout imported; physical meaning not independently verified. PSA-RE bits 8.2-8.1. HADC fault severity status Upstream default raw=0 (not necessarily valid data).";
CM_ SG_ 909 HadcStatus "DATABASE_CANDIDATE: layout imported; physical meaning not independently verified. PSA-RE bits 8.4-8.3. Overall HADC (hill descent control) status Upstream default raw=0 (not necessarily valid data).";
CM_ SG_ 909 HadcSpeedCondition "DATABASE_CANDIDATE: layout imported; physical meaning not independently verified. PSA-RE bits 8.5. HADC speed limit condition met Upstream default raw=0 (not necessarily valid data).";
CM_ SG_ 909 HadcClutchActivationCondition "DATABASE_CANDIDATE: layout imported; physical meaning not independently verified. PSA-RE bits 8.7-8.6. HADC clutch mode activation condition Upstream default raw=0 (not necessarily valid data).";
CM_ SG_ 909 VehicleMovingStatus "DATABASE_CANDIDATE: layout imported; physical meaning not independently verified. PSA-RE bits 7.1-7.0. Vehicle moving status Upstream default raw=1 (not necessarily valid data).";
CM_ SG_ 909 VehicleSpeedUnavailableFlag "DATABASE_CANDIDATE: layout imported; physical meaning not independently verified. PSA-RE bits 7.3-7.2. Vehicle speed unavailability flag Upstream default raw=2 (not necessarily valid data).";
CM_ SG_ 909 VehicleDirection "DATABASE_CANDIDATE: layout imported; physical meaning not independently verified. PSA-RE bits 7.5-7.4. Vehicle direction of travel Upstream default raw=0 (not necessarily valid data).";
CM_ SG_ 909 HillAssistStopAuthorizationStt "DATABASE_CANDIDATE: layout imported; physical meaning not independently verified. PSA-RE bits 7.6. Hill assist stop authorization for Stop & Start Upstream default raw=1 (not necessarily valid data).";
CM_ SG_ 909 HazardLightsRequest "DATABASE_CANDIDATE: layout imported; physical meaning not independently verified. PSA-RE bits 7.7. Hazard warning lights request Upstream default raw=0 (not necessarily valid data).";
CM_ SG_ 909 AbrDynamicFrameChecksum "DATABASE_CANDIDATE: layout imported; physical meaning not independently verified. PSA-RE bits 6.3-6.0. ABR dynamic vehicle frame checksum";
CM_ SG_ 909 ProcessCounter4bit "DATABASE_CANDIDATE: layout imported; physical meaning not independently verified. PSA-RE bits 6.7-6.4. 4-bit process counter Upstream default raw=0 (not necessarily valid data).";
CM_ SG_ 909 LongitudinalAccelerationW_b6474e "DATABASE_CANDIDATE: layout imported; physical meaning not independently verified. PSA-RE bits 5.7-5.0. Longitudinal acceleration, from wheel sensors Raw invalid=255; numeric DBC decoders may still scale it: check raw before use. Upstream default raw=175 (not necessarily valid data).";
CM_ SG_ 909 OdometerWheelSensor "DATABASE_CANDIDATE: layout imported; physical meaning not independently verified. PSA-RE bits 3.7-4.0. Odometer distance, from wheel sensors Upstream default raw=0 (not necessarily valid data).";
CM_ SG_ 909 VehicleSpeedWheelSensors "DATABASE_CANDIDATE: layout imported; physical meaning not independently verified. PSA-RE bits 1.7-2.0. Vehicle speed (wheel sensors) Raw invalid=65535; numeric DBC decoders may still scale it: check raw before use. Upstream default raw=65535 (not necessarily valid data).";
CM_ BO_ 936 "Observed OBD 6/14 HS1. CAN ID 0x3A8; ID_DLC_match. PSA-RE name: ENGINE_ECU_DATA_2. Engine ECU data: power-reduction-off request, atmospheric pressure, main wake-up and SCR purge wake-up. Source: https://github.com/prototux/PSA-RE/blob/67f7581e7622410efdbb29c7eda3b86982b9b450/buses/AEE2010.full/HS.HS1/3A8.yml. Database sender alternatives: CMM,E_VCU. ECU labels are database claims; forwarding/physical transmitter not independently identified. All fitting source fields retained, including default/unavailable-only candidates. See audit/source JSON for exclusions and unresolved alternatives.";
CM_ SG_ 936 RawBits42_47 "RAW. PSA-RE bits 6.5-6.0. Raw unmapped/padding bits; no physical interpretation.";
CM_ SG_ 936 RelativeStateOfEnergy "DATABASE_CANDIDATE: layout imported; physical meaning not independently verified. PSA-RE bits 5.7-6.6. Ratio of available energy within the battery energy range that allows ZEV (electric-only) modes (Wh) Raw invalid=1023; numeric DBC decoders may still scale it: check raw before use.";
CM_ SG_ 936 RawByte4 "RAW. PSA-RE bits 4.7-4.0. Raw unmapped/padding bits; no physical interpretation.";
CM_ SG_ 936 RawBits23_23 "RAW. PSA-RE bits 3.0-3.0. Raw unmapped/padding bits; no physical interpretation.";
CM_ SG_ 936 RegeneratedEnergy "DATABASE_CANDIDATE: layout imported; physical meaning not independently verified. PSA-RE bits 3.7-3.1. Energy recovered through braking and lift-off regeneration (Wh)";
CM_ SG_ 936 RawBits15_15 "RAW. PSA-RE bits 2.0-2.0. Raw unmapped/padding bits; no physical interpretation.";
CM_ SG_ 936 BatteryEnergyBalance "DATABASE_CANDIDATE: layout imported; physical meaning not independently verified. PSA-RE bits 2.7-2.1. Battery balance of all energy produced and/or consumed (Wh)";
CM_ SG_ 936 RawBits7_7 "RAW. PSA-RE bits 1.0-1.0. Raw unmapped/padding bits; no physical interpretation.";
CM_ SG_ 936 ConsumedEnergy "DATABASE_CANDIDATE: layout imported; physical meaning not independently verified. PSA-RE bits 1.7-1.1. Energy consumed by the electric motor and electronic components (ECU, climate control...) (Wh)";
CM_ BO_ 941 "Observed OBD 6/14 HS1. CAN ID 0x3AD; ID_DLC_match. PSA-RE name: EASY_MOVE_BVH2_DATA. Easy Move data specific to the BVH2 gearbox variant: calibrated longitudinal acceleration, parking-brake force estimate, cruise-control inhibit request and fault states. Source: https://github.com/prototux/PSA-RE/blob/67f7581e7622410efdbb29c7eda3b86982b9b450/buses/AEE2010.full/HS.HS1/3AD.yml. Database sender alternatives: ABS. ECU labels are database claims; forwarding/physical transmitter not independently identified. All fitting source fields retained, including default/unavailable-only candidates. See audit/source JSON for exclusions and unresolved alternatives.";
CM_ SG_ 941 Checksum "DATABASE_CANDIDATE: layout imported; physical meaning not independently verified. PSA-RE bits 8.3-8.0. ESP Easy Move frame dynamic checksum";
CM_ SG_ 941 ProcessCounter "DATABASE_CANDIDATE: layout imported; physical meaning not independently verified. PSA-RE bits 8.7-8.4. Free-running counter (0 to 15), incremented on each new calculation, to check it is being refreshed Upstream default raw=0 (not necessarily valid data).";
CM_ SG_ 941 EpbRedLampAlert "DATABASE_CANDIDATE: layout imported; physical meaning not independently verified. PSA-RE bits 7.0. EPB red warning lamp alert Upstream default raw=0 (not necessarily valid data).";
CM_ SG_ 941 EpbDisplayWakeupRequest "DATABASE_CANDIDATE: layout imported; physical meaning not independently verified. PSA-RE bits 7.1. Network wake-up request (RCD) for EPB display needs Upstream default raw=0 (not necessarily valid data).";
CM_ SG_ 941 Unused3 "DATABASE_CANDIDATE: layout imported; physical meaning not independently verified. PSA-RE bits 7.3-7.2. ";
CM_ SG_ 941 EpbSwitchState "DATABASE_CANDIDATE: layout imported; physical meaning not independently verified. PSA-RE bits 7.6-7.4. EPB switch state Upstream default raw=0 (not necessarily valid data).";
CM_ SG_ 941 EpbFault "DATABASE_CANDIDATE: layout imported; physical meaning not independently verified. PSA-RE bits 7.7. EPB (electric parking brake) malfunction Upstream default raw=0 (not necessarily valid data).";
CM_ SG_ 941 ParkBrakeFunctionStatusHmi "DATABASE_CANDIDATE: layout imported; physical meaning not independently verified. PSA-RE bits 6.3-6.0. Parking brake function status for the HMI Upstream default raw=0 (not necessarily valid data).";
CM_ SG_ 941 CalibratedLongitudinalAcc_dc49b6 "DATABASE_CANDIDATE: layout imported; physical meaning not independently verified. PSA-RE bits 5.7-6.4. Calibrated longitudinal acceleration Raw invalid=4095; numeric DBC decoders may still scale it: check raw before use. Upstream default raw=2048 (not necessarily valid data).";
CM_ SG_ 941 ParkBrakeFunctionStatus "DATABASE_CANDIDATE: layout imported; physical meaning not independently verified. PSA-RE bits 4.2-4.0. Parking brake function status Upstream default raw=0 (not necessarily valid data).";
CM_ SG_ 941 HydraulicWheelLockStatus "DATABASE_CANDIDATE: layout imported; physical meaning not independently verified. PSA-RE bits 4.3. 4-wheel automatic locking status by the hydraulic system Upstream default raw=0 (not necessarily valid data).";
CM_ SG_ 941 AutoLockingModeState "DATABASE_CANDIDATE: layout imported; physical meaning not independently verified. PSA-RE bits 4.5-4.4. Automatic locking mode state of the parking brake Upstream default raw=0 (not necessarily valid data).";
CM_ SG_ 941 Unused2 "DATABASE_CANDIDATE: layout imported; physical meaning not independently verified. PSA-RE bits 4.6. ";
CM_ SG_ 941 EasyMoveFault "DATABASE_CANDIDATE: layout imported; physical meaning not independently verified. PSA-RE bits 4.7. Easy Move function fault Upstream default raw=0 (not necessarily valid data).";
CM_ SG_ 941 EpbButtonPressRequest "DATABASE_CANDIDATE: layout imported; physical meaning not independently verified. PSA-RE bits 3.0. Request to signal that the electric parking brake button must be pressed Upstream default raw=0 (not necessarily valid data).";
CM_ SG_ 941 CruiseControlInhibitRequest "DATABASE_CANDIDATE: layout imported; physical meaning not independently verified. PSA-RE bits 3.1. Request to inhibit the speed limiter/cruise control (cruise control) function Upstream default raw=0 (not necessarily valid data).";
CM_ SG_ 941 LongitudinalControlRequest "DATABASE_CANDIDATE: layout imported; physical meaning not independently verified. PSA-RE bits 3.2. Signal requesting longitudinal control of the vehicle Upstream default raw=0 (not necessarily valid data).";
CM_ SG_ 941 BrakePedalSignalRequest "DATABASE_CANDIDATE: layout imported; physical meaning not independently verified. PSA-RE bits 3.3. Request to signal that the brake pedal must be pressed Upstream default raw=0 (not necessarily valid data).";
CM_ SG_ 941 Unused1 "DATABASE_CANDIDATE: layout imported; physical meaning not independently verified. PSA-RE bits 3.5-3.4. ";
CM_ SG_ 941 WheelTorqueSetpointRequest "DATABASE_CANDIDATE: layout imported; physical meaning not independently verified. PSA-RE bits 2.5-3.6. Request to the engine ECU to deliver a specific wheel torque Upstream default raw=254 (not necessarily valid data).";
CM_ SG_ 941 MaxWheelTorqueCapability "DATABASE_CANDIDATE: layout imported; physical meaning not independently verified. PSA-RE bits 1.3-2.6. Maximum wheel torque that can be requested during the manoeuvre, given to the engine ECU Upstream default raw=63 (not necessarily valid data).";
CM_ SG_ 941 EpbRearLeftForceEstimate "DATABASE_CANDIDATE: layout imported; physical meaning not independently verified. PSA-RE bits 1.5-1.4. Estimated electric parking brake (EPB) force applied at the rear left caliper Upstream default raw=0 (not necessarily valid data). Unresolved source alternatives: [{\"bits\": \"1.7-1.6\", \"note\": \"Also observed at bits 1.7-1.6\"}]";
CM_ SG_ 941 EpbRearRightForceEstimate "DATABASE_CANDIDATE: layout imported; physical meaning not independently verified. PSA-RE bits 1.7-1.6. Estimated electric parking brake (EPB) force applied at the rear right caliper Upstream default raw=0 (not necessarily valid data). Unresolved source alternatives: [{\"bits\": \"1.5-1.4\", \"note\": \"Also observed at bits 1.5-1.4\"}]";
CM_ BO_ 973 "Observed OBD 6/14 HS1. CAN ID 0x3CD; ID_DLC_match. PSA-RE name: BRAKE_IN_PROGRESS_STATUS. Braking-in-progress status. Source: https://github.com/prototux/PSA-RE/blob/67f7581e7622410efdbb29c7eda3b86982b9b450/buses/AEE2010.full/HS.HS1/3CD.yml. Database sender alternatives: ABS. ECU labels are database claims; forwarding/physical transmitter not independently identified. All fitting source fields retained, including default/unavailable-only candidates. See audit/source JSON for exclusions and unresolved alternatives.";
CM_ SG_ 973 ProcessCounter4bit "DATABASE_CANDIDATE: layout imported; physical meaning not independently verified. PSA-RE bits 8.3-8.0. 4-bit process counter Upstream default raw=0 (not necessarily valid data).";
CM_ SG_ 973 FrameChecksum "DATABASE_CANDIDATE: layout imported; physical meaning not independently verified. PSA-RE bits 8.7-8.4. Frame checksum";
CM_ SG_ 973 BrakingInProgress "DATABASE_CANDIDATE: layout imported; physical meaning not independently verified. PSA-RE bits 7.1-7.0. Braking in progress Upstream default raw=0 (not necessarily valid data).";
CM_ SG_ 973 Unused2 "DATABASE_CANDIDATE: layout imported; physical meaning not independently verified. PSA-RE bits 7.3-7.2. ";
CM_ SG_ 973 MasterCylinderPressure "DATABASE_CANDIDATE: layout imported; physical meaning not independently verified. PSA-RE bits 6.7-7.4. Master cylinder pressure Raw invalid=4095; numeric DBC decoders may still scale it: check raw before use. Upstream default raw=550 (not necessarily valid data).";
CM_ SG_ 973 EasymoveRestartInhibitRequest "DATABASE_CANDIDATE: layout imported; physical meaning not independently verified. PSA-RE bits 5.2-5.0. Engine restart inhibition request from Easymove Upstream default raw=3 (not necessarily valid data).";
CM_ SG_ 973 Unused1 "DATABASE_CANDIDATE: layout imported; physical meaning not independently verified. PSA-RE bits 5.4-5.3. ";
CM_ SG_ 973 BrakePedalSwitch3Fault "DATABASE_CANDIDATE: layout imported; physical meaning not independently verified. PSA-RE bits 5.5. Main brake pedal switch disabled, brake ECU Upstream default raw=0 (not necessarily valid data).";
CM_ SG_ 973 BrakePedalSwitch3 "DATABASE_CANDIDATE: layout imported; physical meaning not independently verified. PSA-RE bits 5.6. Main brake pedal switch, brake ECU Upstream default raw=0 (not necessarily valid data).";
CM_ SG_ 973 MuSplitSituation "DATABASE_CANDIDATE: layout imported; physical meaning not independently verified. PSA-RE bits 5.7. Mu-split situation (asymmetric road grip braking) Upstream default raw=0 (not necessarily valid data).";
CM_ SG_ 973 YawRate "DATABASE_CANDIDATE: layout imported; physical meaning not independently verified. PSA-RE bits 3.7-4.0. Yaw rate Raw invalid=32767; numeric DBC decoders may still scale it: check raw before use. Upstream default raw=0 (not necessarily valid data).";
CM_ SG_ 973 LateralAcceleration "DATABASE_CANDIDATE: layout imported; physical meaning not independently verified. PSA-RE bits 1.7-2.0. Lateral acceleration Raw invalid=32767; numeric DBC decoders may still scale it: check raw before use. Upstream default raw=0 (not necessarily valid data).";
CM_ BO_ 974 "Observed OBD 6/14 HS1. CAN ID 0x3CE; ID_DLC_match. PSA-RE name: BSI_CABIN_DATA. Body controller cabin data: hybrid blower setpoint, load-shedding requests for ABS/ESP, electric power steering, EasyMove and suspension, demisting request and hybrid zero-emission cabin inhibition. Source: https://github.com/prototux/PSA-RE/blob/67f7581e7622410efdbb29c7eda3b86982b9b450/buses/AEE2010.full/HS.HS1/3CE.yml. Database sender alternatives: BSI. ECU labels are database claims; forwarding/physical transmitter not independently identified. All fitting source fields retained, including default/unavailable-only candidates. See audit/source JSON for exclusions and unresolved alternatives.";
CM_ SG_ 974 RawBits57_63 "RAW. PSA-RE bits 8.6-8.0. Raw unmapped/padding bits; no physical interpretation.";
CM_ SG_ 974 HvacAirflow "DATABASE_CANDIDATE: layout imported; physical meaning not independently verified. PSA-RE bits 7.7-8.7. Blower airflow rate Raw invalid=511; numeric DBC decoders may still scale it: check raw before use.";
CM_ SG_ 974 EvaporatorProbeTemp "DATABASE_CANDIDATE: layout imported; physical meaning not independently verified. PSA-RE bits 5.2-6.0. Evaporator probe temperature Raw invalid=2047; numeric DBC decoders may still scale it: check raw before use.";
CM_ SG_ 974 EvaporatorTempSetpoint "DATABASE_CANDIDATE: layout imported; physical meaning not independently verified. PSA-RE bits 5.7-5.3. Evaporator temperature threshold setpoint Raw invalid=31; numeric DBC decoders may still scale it: check raw before use.";
CM_ SG_ 974 HeaterWaterTempSetpoint "DATABASE_CANDIDATE: layout imported; physical meaning not independently verified. PSA-RE bits 4.7-4.0. Heater core temperature threshold setpoint Raw invalid=255; numeric DBC decoders may still scale it: check raw before use.";
CM_ SG_ 974 HeaterOutletWaterTemp "DATABASE_CANDIDATE: layout imported; physical meaning not independently verified. PSA-RE bits 3.7-3.0. Water temperature at the HVAC heater core outlet Raw invalid=255; numeric DBC decoders may still scale it: check raw before use.";
CM_ SG_ 974 EvaporatorUpstreamAirTemp "DATABASE_CANDIDATE: layout imported; physical meaning not independently verified. PSA-RE bits 2.7-2.0. Air temperature upstream of the HVAC evaporator Raw invalid=255; numeric DBC decoders may still scale it: check raw before use.";
CM_ SG_ 974 RawBits4_7 "RAW. PSA-RE bits 1.3-1.0. Raw unmapped/padding bits; no physical interpretation.";
CM_ SG_ 974 AcEcoModePriorityRequest "DATABASE_CANDIDATE: layout imported; physical meaning not independently verified. PSA-RE bits 1.4. Air conditioning priority request over eco mode";
CM_ SG_ 974 FanLoadShedding "DATABASE_CANDIDATE: layout imported; physical meaning not independently verified. PSA-RE bits 1.5. Cooling fan (GMV) load shedding";
CM_ SG_ 974 DeicingAuthorization "DATABASE_CANDIDATE: layout imported; physical meaning not independently verified. PSA-RE bits 1.6. De-icing authorization";
CM_ SG_ 974 VisibilityRequest "DATABASE_CANDIDATE: layout imported; physical meaning not independently verified. PSA-RE bits 1.7. Visibility (demisting/defrosting) request";
CM_ BO_ 1006 "Observed OBD 6/14 HS1. CAN ID 0x3EE; ID_DLC_match. PSA-RE name: BSI_CABIN_DATA_2. Body controller cabin data: hybrid blower setpoint, load-shedding requests for ABS/ESP, electric power steering, EasyMove and suspension, demisting request and hybrid zero-emission cabin inhibition. Source: https://github.com/prototux/PSA-RE/blob/67f7581e7622410efdbb29c7eda3b86982b9b450/buses/AEE2010.full/HS.HS1/3EE.yml. Database sender alternatives: BSI. ECU labels are database claims; forwarding/physical transmitter not independently identified. All fitting source fields retained, including default/unavailable-only candidates. See audit/source JSON for exclusions and unresolved alternatives.";
CM_ SG_ 1006 Unused1 "DATABASE_CANDIDATE: layout imported; physical meaning not independently verified. PSA-RE bits 2.7-4.0. ";
CM_ SG_ 1006 DetectionDeviceDecelerati_8e97ab "DATABASE_CANDIDATE: layout imported; physical meaning not independently verified. PSA-RE bits 1.7-1.0. Vehicle deceleration setpoint from the detection device Upstream default raw=254 (not necessarily valid data).";
CM_ BO_ 1010 "Observed OBD 6/14 HS1. CAN ID 0x3F2; ID_DLC_match. PSA-RE name: BSI_CABIN_DATA_3. Body controller cabin data: hybrid blower setpoint, load-shedding requests for ABS/ESP, electric power steering, EasyMove and suspension, demisting request and hybrid zero-emission cabin inhibition. Source: https://github.com/prototux/PSA-RE/blob/67f7581e7622410efdbb29c7eda3b86982b9b450/buses/AEE2010.full/HS.HS1/3F2.yml. Database sender alternatives: BSI. ECU labels are database claims; forwarding/physical transmitter not independently identified. All fitting source fields retained, including default/unavailable-only candidates. See audit/source JSON for exclusions and unresolved alternatives.";
CM_ SG_ 1010 DeadmanButtonRequestStatusBsi "DATABASE_CANDIDATE: layout imported; physical meaning not independently verified. PSA-RE bits 8.1-8.0. Status of the dedicated dead-man's switch request, from the BSI Upstream default raw=0 (not necessarily valid data).";
CM_ SG_ 1010 SteeringColumnAngleSetpoint "DATABASE_CANDIDATE: layout imported; physical meaning not independently verified. PSA-RE bits 7.7-8.2. Steering column angle setpoint sent by the BSI to the DAE Upstream default raw=0 (not necessarily valid data).";
CM_ SG_ 1010 LkaLpaSteeringSelection "DATABASE_CANDIDATE: layout imported; physical meaning not independently verified. PSA-RE bits 6.0. Flag indicating whether the DAE is controlled by the LKA or LPA function Upstream default raw=0 (not necessarily valid data).";
CM_ SG_ 1010 LkaTorqueFactorRequest "DATABASE_CANDIDATE: layout imported; physical meaning not independently verified. PSA-RE bits 6.7-6.1. DAE torque regulation factor requested by the LKA function Raw invalid=127; numeric DBC decoders may still scale it: check raw before use. Upstream default raw=127 (not necessarily valid data).";
CM_ SG_ 1010 LkaRightCorrectionActivation "DATABASE_CANDIDATE: layout imported; physical meaning not independently verified. PSA-RE bits 5.0. LKA (lane keeping assist) activation for right correction Upstream default raw=0 (not necessarily valid data).";
CM_ SG_ 1010 LkaLeftCorrectionActivation "DATABASE_CANDIDATE: layout imported; physical meaning not independently verified. PSA-RE bits 5.1. LKA (lane keeping assist) activation for left correction Upstream default raw=0 (not necessarily valid data).";
CM_ SG_ 1010 LkaGlobalState "DATABASE_CANDIDATE: layout imported; physical meaning not independently verified. PSA-RE bits 5.4-5.2. Overall state of the LKA (lane keeping assist) function Upstream default raw=0 (not necessarily valid data).";
CM_ SG_ 1010 LkaRequestedYawRate "DATABASE_CANDIDATE: layout imported; physical meaning not independently verified. PSA-RE bits 4.7-5.5. Yaw rate requested by the LKA function to correct the trajectory Raw invalid=1023; numeric DBC decoders may still scale it: check raw before use. Upstream default raw=1023 (not necessarily valid data).";
CM_ SG_ 1010 AcBlowerSpeed "DATABASE_CANDIDATE: layout imported; physical meaning not independently verified. PSA-RE bits 3.6-3.0. Current air conditioning blower speed Raw invalid=127; numeric DBC decoders may still scale it: check raw before use. Upstream default raw=0 (not necessarily valid data).";
CM_ SG_ 1010 AsrDisconnectRequest "DATABASE_CANDIDATE: layout imported; physical meaning not independently verified. PSA-RE bits 3.7. ASR (traction control) connection/disconnection request Upstream default raw=0 (not necessarily valid data).";
CM_ SG_ 1010 ProcessCounter3f2 "DATABASE_CANDIDATE: layout imported; physical meaning not independently verified. PSA-RE bits 2.3-2.0. 4-bit rolling process counter of frame 0x3F2 Upstream default raw=0 (not necessarily valid data).";
CM_ SG_ 1010 FrameChecksum3f2 "DATABASE_CANDIDATE: layout imported; physical meaning not independently verified. PSA-RE bits 2.7-2.4. Checksum of frame 0x3F2";
CM_ SG_ 1010 DemistingRequest "DATABASE_CANDIDATE: layout imported; physical meaning not independently verified. PSA-RE bits 1.0. Demisting request Upstream default raw=0 (not necessarily valid data).";
CM_ SG_ 1010 AbsEspPowerCutRequest "DATABASE_CANDIDATE: layout imported; physical meaning not independently verified. PSA-RE bits 1.1. ABS/ESP power cut (load shedding) request Upstream default raw=0 (not necessarily valid data).";
CM_ SG_ 1010 PowerSteeringCutRequest "DATABASE_CANDIDATE: layout imported; physical meaning not independently verified. PSA-RE bits 1.2. Power steering power cut (load shedding) request Upstream default raw=0 (not necessarily valid data).";
CM_ SG_ 1010 EasymovePowerCutRequest "DATABASE_CANDIDATE: layout imported; physical meaning not independently verified. PSA-RE bits 1.3. EASYMOVE power cut (load shedding) request Upstream default raw=0 (not necessarily valid data).";
CM_ SG_ 1010 SuspensionPowerCutRequest "DATABASE_CANDIDATE: layout imported; physical meaning not independently verified. PSA-RE bits 1.4. Suspension power cut (load shedding) request Upstream default raw=0 (not necessarily valid data).";
CM_ SG_ 1010 ZevModeProhibition "DATABASE_CANDIDATE: layout imported; physical meaning not independently verified. PSA-RE bits 1.5. Prohibition of entering zero-emission (ZEV) mode Upstream default raw=0 (not necessarily valid data).";
CM_ SG_ 1010 BrakeModeConfiguration "DATABASE_CANDIDATE: layout imported; physical meaning not independently verified. PSA-RE bits 1.6. Brake mode configuration status Upstream default raw=0 (not necessarily valid data).";
CM_ SG_ 1010 TrailerDetection "DATABASE_CANDIDATE: layout imported; physical meaning not independently verified. PSA-RE bits 1.7. Trailer presence detection Upstream default raw=0 (not necessarily valid data).";

VAL_ 166 ImmoEcuState 0 "Unlocked" 1 "Locked" ;
VAL_ 166 ImmoLocalIdMcuBsi 0 "SEED transmission" 2 "ECU state transmission" ;
VAL_ 520 DriverTorqueRequestProcessed 255 "Not_available" ;
VAL_ 520 AnticipatedEngineTorque 255 "Not_available" ;
VAL_ 520 ActualTorqueWithoutGearbo_d9537a 255 "Not_available" ;
VAL_ 520 BrakePedalSwitch2 0 "Brake pedal released" 1 "Brake pedal pressed" ;
VAL_ 520 CruiseSpeedLimiterStatus 0 "cruise control waiting / speed limiter waiting - speed limiter not effective" 1 "Cruise control/speed limiter resumed via accelerator pedal" 2 "cruise control active / speed limiter effective" 3 "Cruise control inhibited / speed limiter inhibited" ;
VAL_ 520 EngineTorqueEstimateUncertain 0 "Engine torque information guaranteed to required accuracy" 1 "Torque information without the guaranteed required accuracy" ;
VAL_ 520 DiagStatus 0 "No communication diagnostic" 1 "Communication diagnostic on" ;
VAL_ 520 EngineLoadRequest 0 "No active request" 1 "Request active" ;
VAL_ 520 DriverDemandPercent 255 "Not_available" ;
VAL_ 520 ActualTorque 255 "Not_available" ;
VAL_ 520 EngineSpeed 65535 "Not_available" ;
VAL_ 610 PowertrainState 0 "Powertrain inactive" 4 "Powertrain activation" 8 "Powertrain active" 10 "Powertrain deactivation" 12 "Powertrain held after deactivation" 14 "Powertrain at rest" ;
VAL_ 749 RearRightWheelPulseCounterFault 0 "No fault" 1 "Rear-right pulse counter fault" ;
VAL_ 749 RearLeftWheelPulseCounterFault 0 "No fault on the RRL pulse counter" 1 "Fault on the rear left pulse counter" ;
VAL_ 749 FrontRightWheelPulseCounterFault 0 "No fault on front-right pulse counter" 1 "Fault" ;
VAL_ 749 FrontLeftWheelPulseCounterFault 0 "No fault on the FRL pulse counter" 1 "Front left pulse counter fault" ;
VAL_ 757 ColumnAngleSafeStatus 0 "Column angle unsafe" 1 "Column angle safe" ;
VAL_ 757 ColumnAngleMonitoringCounter 0 "Initialisation" 1 "Offset initialization request" 2 "Offset search authorised" 3 "Offset used" 7 "Invalid" ;
VAL_ 757 EpsColumnSpeed 2047 "Not_available" ;
VAL_ 757 EpsColumnAngle 32767 "Not_available" ;
VAL_ 757 CityparkDeactivationCause 0 "No control interruption" 1 "Driver takeover" 2 "Vehicle speed too high" 3 "Angular error too high" 4 "Obstacle at the wheel" 5 "Manoeuvring number too high" 6 "DAE thermal safety cut-off" 7 "Other faults" ;
VAL_ 757 EpsStatusForCitypark 0 "Unavailable" 1 "Available" 2 "Control in progress" 3 "Invalid" ;
VAL_ 757 SspEpsCouplingFailure 0 "No failure" 1 "Coupling fault" ;
VAL_ 757 SteeringWheelDriverTorque 127 "Not_available" ;
VAL_ 773 SteeringWheelAngleSource 0 "Estimator" 1 "CAV3" 2 "Integrated CAV3" 3 "other" ;
VAL_ 773 SteeringWheelAngleInaccurate 0 "Accurate steering wheel angle" 1 "Uncertain steering wheel angle" ;
VAL_ 773 SteeringWheelAngleInitialized 0 "Steering wheel angle available" 1 "Steering wheel angle memorised" ;
VAL_ 773 SteeringWheelRotationSpee_effc71 255 "Not_available" ;
VAL_ 773 SteeringWheelAngleSensorStatus 0 "Sensor faulty" 1 "Sensor OK" ;
VAL_ 773 SteeringWheelAngleSensorC_affc57 0 "Sensor not calibrated" 1 "Sensor calibrated" ;
VAL_ 773 SteeringWheelAngleSensorA_f0288c 0 "Sensor not adjusted" 1 "Adjusted" ;
VAL_ 773 SteeringWheelAngleSensorF_3754bb 0 "No fault, or fault no longer present" 1 "Inconsistency detected by ESP on steering wheel rotation speed information" 2 "Inconsistency detected by ESP on steering-wheel angle info (if sensor state and calibration OK)" 3 "Inconsistency detected by ESP on steering-wheel angle and rotation speed" 12 "Internal faults detected by the steering wheel angle sensor (if Etat_capt_vol and Calibration_vol = 0)" ;
VAL_ 773 SteeringWheelRotationDirection 0 "Positive angle direction, wheel angle increasing (counter-clockwise)" 1 "Negative angle direction, steering wheel angle decreasing: clockwise" ;
VAL_ 773 SteeringRotationSpeed 255 "Not_available" ;
VAL_ 773 SteeringAngle 32767 "Not_available" ;
VAL_ 781 WheelSpeedRR 65535 "Not_available" ;
VAL_ 781 WheelSpeedRL 65535 "Not_available" ;
VAL_ 781 WheelSpeedFR 65535 "Not_available" ;
VAL_ 781 WheelSpeedFL 65535 "Not_available" ;
VAL_ 820 CellVoltage044 16383 "Not_available" ;
VAL_ 820 CellVoltage040 16383 "Not_available" ;
VAL_ 820 CellVoltage092 16383 "Not_available" ;
VAL_ 820 CellVoltage020 16383 "Not_available" ;
VAL_ 820 CellVoltage088 16383 "Not_available" ;
VAL_ 820 CellVoltage108 16383 "Not_available" ;
VAL_ 820 CellVoltage104 16383 "Not_available" ;
VAL_ 820 CellVoltage068 16383 "Not_available" ;
VAL_ 820 CellVoltage064 16383 "Not_available" ;
VAL_ 820 CellVoltage016 16383 "Not_available" ;
VAL_ 820 CellVoltage072 16383 "Not_available" ;
VAL_ 820 CellVoltage060 16383 "Not_available" ;
VAL_ 820 CellVoltage056 16383 "Not_available" ;
VAL_ 820 CellVoltage084 16383 "Not_available" ;
VAL_ 820 CellVoltage004 16383 "Not_available" ;
VAL_ 820 CellVoltage052 16383 "Not_available" ;
VAL_ 820 CellVoltage012 16383 "Not_available" ;
VAL_ 820 CellVoltage008 16383 "Not_available" ;
VAL_ 820 CellVoltage048 16383 "Not_available" ;
VAL_ 820 CellVoltage080 16383 "Not_available" ;
VAL_ 820 CellVoltage036 16383 "Not_available" ;
VAL_ 820 CellVoltage076 16383 "Not_available" ;
VAL_ 820 CellVoltage100 16383 "Not_available" ;
VAL_ 820 CellVoltage096 16383 "Not_available" ;
VAL_ 820 CellVoltage032 16383 "Not_available" ;
VAL_ 820 CellVoltage028 16383 "Not_available" ;
VAL_ 820 CellVoltage024 16383 "Not_available" ;
VAL_ 820 CellVoltage031 16383 "Not_available" ;
VAL_ 820 CellVoltage043 16383 "Not_available" ;
VAL_ 820 CellVoltage091 16383 "Not_available" ;
VAL_ 820 CellVoltage019 16383 "Not_available" ;
VAL_ 820 CellVoltage087 16383 "Not_available" ;
VAL_ 820 CellVoltage107 16383 "Not_available" ;
VAL_ 820 CellVoltage067 16383 "Not_available" ;
VAL_ 820 CellVoltage063 16383 "Not_available" ;
VAL_ 820 CellVoltage015 16383 "Not_available" ;
VAL_ 820 CellVoltage071 16383 "Not_available" ;
VAL_ 820 CellVoltage059 16383 "Not_available" ;
VAL_ 820 CellVoltage083 16383 "Not_available" ;
VAL_ 820 CellVoltage007 16383 "Not_available" ;
VAL_ 820 CellVoltage051 16383 "Not_available" ;
VAL_ 820 CellVoltage039 16383 "Not_available" ;
VAL_ 820 CellVoltage011 16383 "Not_available" ;
VAL_ 820 CellVoltage079 16383 "Not_available" ;
VAL_ 820 CellVoltage035 16383 "Not_available" ;
VAL_ 820 CellVoltage003 16383 "Not_available" ;
VAL_ 820 CellVoltage055 16383 "Not_available" ;
VAL_ 820 CellVoltage023 16383 "Not_available" ;
VAL_ 820 CellVoltage075 16383 "Not_available" ;
VAL_ 820 CellVoltage103 16383 "Not_available" ;
VAL_ 820 CellVoltage099 16383 "Not_available" ;
VAL_ 820 CellVoltage095 16383 "Not_available" ;
VAL_ 820 CellVoltage047 16383 "Not_available" ;
VAL_ 820 CellVoltage027 16383 "Not_available" ;
VAL_ 820 CellVoltage030 16383 "Not_available" ;
VAL_ 820 CellVoltage042 16383 "Not_available" ;
VAL_ 820 CellVoltage022 16383 "Not_available" ;
VAL_ 820 CellVoltage018 16383 "Not_available" ;
VAL_ 820 CellVoltage090 16383 "Not_available" ;
VAL_ 820 CellVoltage106 16383 "Not_available" ;
VAL_ 820 CellVoltage066 16383 "Not_available" ;
VAL_ 820 CellVoltage014 16383 "Not_available" ;
VAL_ 820 CellVoltage074 16383 "Not_available" ;
VAL_ 820 CellVoltage070 16383 "Not_available" ;
VAL_ 820 CellVoltage062 16383 "Not_available" ;
VAL_ 820 CellVoltage058 16383 "Not_available" ;
VAL_ 820 CellVoltage086 16383 "Not_available" ;
VAL_ 820 CellVoltage006 16383 "Not_available" ;
VAL_ 820 CellVoltage054 16383 "Not_available" ;
VAL_ 820 CellVoltage050 16383 "Not_available" ;
VAL_ 820 CellVoltage038 16383 "Not_available" ;
VAL_ 820 CellVoltage010 16383 "Not_available" ;
VAL_ 820 CellVoltage082 16383 "Not_available" ;
VAL_ 820 CellVoltage094 16383 "Not_available" ;
VAL_ 820 CellVoltage034 16383 "Not_available" ;
VAL_ 820 CellVoltage002 16383 "Not_available" ;
VAL_ 820 CellVoltage078 16383 "Not_available" ;
VAL_ 820 CellVoltage102 16383 "Not_available" ;
VAL_ 820 CellVoltage098 16383 "Not_available" ;
VAL_ 820 CellVoltage046 16383 "Not_available" ;
VAL_ 820 CellVoltage026 16383 "Not_available" ;
VAL_ 820 CellVoltage029 16383 "Not_available" ;
VAL_ 820 CellVoltage041 16383 "Not_available" ;
VAL_ 820 CellVoltage021 16383 "Not_available" ;
VAL_ 820 CellVoltage069 16383 "Not_available" ;
VAL_ 820 CellVoltage105 16383 "Not_available" ;
VAL_ 820 CellVoltage065 16383 "Not_available" ;
VAL_ 820 CellVoltage017 16383 "Not_available" ;
VAL_ 820 CellVoltage073 16383 "Not_available" ;
VAL_ 820 CellVoltage061 16383 "Not_available" ;
VAL_ 820 CellVoltage057 16383 "Not_available" ;
VAL_ 820 CellVoltage085 16383 "Not_available" ;
VAL_ 820 CellVoltage005 16383 "Not_available" ;
VAL_ 820 CellVoltage053 16383 "Not_available" ;
VAL_ 820 CellVoltage037 16383 "Not_available" ;
VAL_ 820 CellVoltage013 16383 "Not_available" ;
VAL_ 820 CellVoltage009 16383 "Not_available" ;
VAL_ 820 CellVoltage049 16383 "Not_available" ;
VAL_ 820 CellVoltage081 16383 "Not_available" ;
VAL_ 820 CellVoltage093 16383 "Not_available" ;
VAL_ 820 CellVoltage001 16383 "Not_available" ;
VAL_ 820 CellVoltage089 16383 "Not_available" ;
VAL_ 820 CellVoltage077 16383 "Not_available" ;
VAL_ 820 CellVoltage101 16383 "Not_available" ;
VAL_ 820 CellVoltage097 16383 "Not_available" ;
VAL_ 820 CellVoltage033 16383 "Not_available" ;
VAL_ 820 CellVoltage045 16383 "Not_available" ;
VAL_ 820 CellVoltage025 16383 "Not_available" ;
VAL_ 820 CellGroup 0 "Battery cell voltages 1 to 4" 1 "Battery cell voltages 5 to 8" 2 "Battery cell voltages 9 to 12" 3 "Battery cell voltages 13 to 16" 4 "Battery cell voltages 17 to 20" 5 "Battery cell voltages 21 to 24" 6 "Battery cell voltages 25 to 28" 7 "Transmission of battery cell voltage data, cells 29-32" 8 "Battery cell voltages 33 to 36" 9 "Battery cell voltages 37 to 40" 10 "Battery cell voltages 41 to 44" 11 "Battery cell voltages 45 to 48" 12 "Battery cell voltages 49 to 52" 13 "Transmission of battery cell voltage data, cells 53-56" 14 "Battery cell voltages 57 to 60" 15 "Battery cell voltages 61 to 64" 16 "Battery cell voltages 65 to 68" 17 "Battery cell voltages 69 to 72" 18 "Battery cell voltages 73 to 76" 19 "Battery cell voltages 77 to 80" 20 "Battery cell voltages 81 to 84" 21 "Battery cell voltages 85 to 88" 22 "Battery cell voltages 89 to 92" 23 "Battery cell voltages 93 to 96" 24 "Battery cell voltages 97 to 100" 25 "Battery cell voltages 101 to 104" 26 "Battery cell voltages 105 to 108" ;
VAL_ 840 ObdFaultOnMilPresent 0 "Absent" 1 "Fault present" ;
VAL_ 840 MilLampSteadyRequest 0 "No steady MIL lamp request" 1 "Request to light MIL steady" ;
VAL_ 840 MilLampBlinkRequest 0 "No MIL lamp blinking request" 1 "MIL lamp blinking request" ;
VAL_ 840 WarmUpCycleCompletedStatus 0 "Not carried out" 1 "Completed" ;
VAL_ 840 DrivingCycleGlobalSyncStatus 0 "Not carried out" 1 "Completed" ;
VAL_ 840 ObdIgnitionContact 0 "Absent" 1 "Present" ;
VAL_ 840 EngineRunning 0 "Locked" 1 "Stalled (engine off)" 2 "Starting (driven)" 3 "Engine running" 4 "Stopped" 5 "Driven restart" 6 "Degraded restart" 7 "Engine preparing" 10 "Autonomous starting" 13 "Autonomous restart" 15 "Invalid" ;
VAL_ 840 RearAsrMsrAcknowledge 0 "Communication problem" 1 "Communication OK" ;
VAL_ 840 AsrMsrAcknowledge 0 "Communication problem" 1 "Communication OK" ;
VAL_ 840 CoolingSystemPressure2 255 "Not_available" ;
VAL_ 841 GearboxCouplingDeviceStatus 0 "Open" 1 "Actual slip" 2 "Potential slip" 3 "Closed" ;
VAL_ 841 GearboxReductionState 0 "Open" 1 "Intermediate" 2 "Closed" ;
VAL_ 841 GearboxMechanicallyEngagedGear 1 "Gear: 1" 2 "Gear: 2" 3 "Gear: 3" 4 "Transmission range: 4" 5 "Gear: 5" 6 "Gear: 6" 7 "Transmission range: 7" 8 "Gear: 8" 9 "Reverse gear" 10 "Neutral" 15 "Engaged gear uncertain" ;
VAL_ 841 GearboxMaxAdmissibleTorque 255 "Not_available" ;
VAL_ 841 GearPosition 0 "P (automatic gearbox)" 1 "R" 2 "N" 3 "D (automatic gearbox)" 8 "P/R or N/R intermediate position" 9 "Intermediate, not determined" 10 "Intermediate" 11 "Manual mode" 15 "Invalid" ;
VAL_ 841 GearboxTargetGear 0 "Disengaged" 1 "Gear: 1" 2 "Gear: 2" 3 "Gear: 3" 4 "Transmission range: 4" 5 "Gear: 5" 6 "Gear: 6" 7 "Transmission range: 7" 8 "Gear: 8" 9 "Reverse gear" 10 "Neutral" 15 "Engaged gear uncertain" ;
VAL_ 841 GearShiftInProgress 0 "No change in progress" 1 "Gear shift in progress" ;
VAL_ 841 TractionChainStateChangePhase 0 "Outside powertrain state change phase" 1 "Powertrain state change in progress" ;
VAL_ 841 GearboxTorqueConverterStatus 0 "Converter open" 1 "Converter regulating or slipping" 2 "Converter bridged or closed" 3 "Info not available" ;
VAL_ 841 AcCompressorInhibitGearshift 0 "No request" 1 "Change of state forbidden" ;
VAL_ 841 EngineSpeedRegulationRequest 0 "No regulation request" 1 "Regulation requested" ;
VAL_ 841 EngineSpeedRelaunchType 0 "Downshift" 1 "Bridging" ;
VAL_ 841 IdleSpeedIncreaseRequest 0 "No action" 1 "Increase request" ;
VAL_ 841 GearboxDragReductionStatus 0 "Park or N" 1 "Disengaged when stopped (drag reduction requested)" 2 "Engaged (D-R-3-2-1)" 3 "Information unavailable" ;
VAL_ 841 GearShiftInProgressType 0 "Upshift" 1 "Down" 2 "Bridging" 3 "No intervention" 4 "Pick up" 5 "Restarting recovery" 6 "Forbidden value" 7 "Forbidden value" ;
VAL_ 841 EngineTorqueTransmissionStatus 0 "No engine torque transmission" 1 "Engine torque transmission" ;
VAL_ 841 AcCompressorCutoffRequestGearbox 0 "No request" 1 "Requested" ;
VAL_ 845 StaticSlope 63 "Not_available" ;
VAL_ 845 BasrRegulationActive 0 "Not in regulation" 1 "Regulation active" ;
VAL_ 845 AsrRegulationActive 0 "Not in regulation" 1 "Regulation active" ;
VAL_ 845 MsrRegulationActive 0 "Not in regulation" 1 "Regulation active" ;
VAL_ 845 EspRegulationActive 0 "Not in regulation" 1 "Regulation active" ;
VAL_ 845 AfuRegulationActive 0 "Not in regulation" 1 "Regulation active" ;
VAL_ 845 AsrEspRegulationLampRequest 0 "No request" 1 "Switch-on request" ;
VAL_ 845 HillAssistStatus 0 "No Hill Assist regulation in progress" 1 "Hill Assist hold in progress" 3 "Fault" ;
VAL_ 845 GearChangeAuthorization 0 "Shifting not allowed" 1 "Downshift allowed" 2 "Upshift allowed" 3 "Upshift or downshift allowed" ;
VAL_ 845 BrakePrefillActive 0 "False" 1 "True" ;
VAL_ 845 FarcDecelerationFunctionStatus 0 "Inhibited" 1 "Waiting" 2 "Active" 3 "Faulty" ;
VAL_ 845 AsrPlusMode 0 "ASR+ in ESP OFF mode" 1 "ASR+ normal mode" 2 "ASR+ in snow mode" 3 "ASR+ in mud mode" 4 "ASR+ in sand mode" 5 "Reserved value" 6 "ASR+ selector failure" 7 "ESP ASR+ selector failure" ;
VAL_ 845 EspTorqueRequestStatus 0 "No action on torque" 5 "Reduction request (ASR)" 6 "Increase setpoint (MSR)" ;
VAL_ 845 AsrDisconnectStatus 0 "Connected by the driver" 1 "Disconnected by the driver" ;
VAL_ 845 AsrEspFaultLampRequest 0 "No request" 1 "Switch-on request" ;
VAL_ 845 GearboxVdcProgramRequest 0 "No request" 1 "VDC program request" ;
VAL_ 845 AsrEspRegulationActive 0 "Not in regulation" 1 "Regulation active" ;
VAL_ 845 AsrEspDisconnectStatus 0 "Connected by the driver" 1 "Disconnected by the driver" ;
VAL_ 877 DynamicSlopeAccuracy 0 "Good" 1 "Medium" 2 "Low" 3 "Undefined" ;
VAL_ 877 DynamicSlopeValue 63 "Not_available" ;
VAL_ 877 HydraulicHoldStatus 0 "Not held" 1 "Held" ;
VAL_ 877 EscHydraulicFailure 0 "No fault" 1 "Fault" ;
VAL_ 877 VmcStatus 0 "Unavailable" 1 "Ready" 2 "Active" ;
VAL_ 909 HadcFaultStatus 0 "Nominal" 1 "Low" 2 "Serious" ;
VAL_ 909 HadcStatus 0 "HADC not selected" 1 "HADC on standby" 2 "HADC active" 3 "HADC regulating hydraulic braking" ;
VAL_ 909 HadcSpeedCondition 0 "HADC speed condition not OK" 1 "HADC speed condition OK" ;
VAL_ 909 HadcClutchActivationCondition 0 "No clutch condition active" 1 "Clutch function possible" 2 "Clutch function active" ;
VAL_ 909 VehicleMovingStatus 0 "Invalid" 1 "Vehicle moving" 2 "Vehicle stopped" 3 "Invalid" ;
VAL_ 909 VehicleSpeedUnavailableFlag 0 "Invalid" 1 "Speed information available" 2 "Speed information unavailable" 3 "Invalid" ;
VAL_ 909 VehicleDirection 0 "Unspecified" 1 "Toward the front" 2 "Toward the rear" 3 "Invalid" ;
VAL_ 909 HillAssistStopAuthorizationStt 0 "Hill Assist not ready to hold" 1 "Hill Assist ready for stop" ;
VAL_ 909 HazardLightsRequest 0 "No request" 1 "Switch-on request" ;
VAL_ 909 LongitudinalAccelerationW_b6474e 255 "Not_available" ;
VAL_ 909 VehicleSpeedWheelSensors 65535 "Not_available" ;
VAL_ 936 RelativeStateOfEnergy 1023 "Not_available" ;
VAL_ 941 EpbRedLampAlert 0 "No alert" 1 "Alert" ;
VAL_ 941 EpbDisplayWakeupRequest 0 "Wake-up not requested" 1 "Wake-up requested" ;
VAL_ 941 EpbSwitchState 0 "Button released" 1 "Switch pressed" 2 "Switch faulty and pressed" 3 "Switch faulty and released" 4 "Switch pulled" 5 "Switch faulty and pulled" ;
VAL_ 941 EpbFault 0 "No fault detected" 1 "EPB faulty" ;
VAL_ 941 ParkBrakeFunctionStatusHmi 0 "Initialisation" 1 "Parking brake released" 2 "Park brake applied" 3 "Parking brake static locking in progress" 4 "Parking brake in static release" 5 "Park brake static pre-release in progress" 6 "Parking brake static re-tightening in progress" 7 "Dynamic braking in progress" 8 "Parking brake applied at maximum force (long press of the EPB switch)" 15 "Invalid" ;
VAL_ 941 CalibratedLongitudinalAcc_dc49b6 4095 "Not_available" ;
VAL_ 941 ParkBrakeFunctionStatus 0 "Parking brake released" 1 "Park brake applied" 2 "Parking brake static locking in progress" 3 "Parking brake in static release" 4 "Dynamic braking in progress" 5 "Parking brake applied at maximum force (long press of the EPB switch)" 7 "Undefined state" ;
VAL_ 941 HydraulicWheelLockStatus 0 "4 wheels not automatically applied by hydraulics" 1 "4 wheels locked automatically by hydraulics" ;
VAL_ 941 AutoLockingModeState 0 "Parking brake in automatic-apply mode" 1 "Parking brake in manual-apply mode" 2 "Parking brake in automatic (forced) apply mode" ;
VAL_ 941 EasyMoveFault 0 "No fault" 1 "Faulty" ;
VAL_ 941 EpbButtonPressRequest 0 "No signalization requested" 1 "Signalling requested" ;
VAL_ 941 CruiseControlInhibitRequest 0 "No cruise control inhibition requested" 1 "cruise control inhibition requested" ;
VAL_ 941 LongitudinalControlRequest 0 "Inactive" 1 "Active" ;
VAL_ 941 BrakePedalSignalRequest 0 "No signalling requested" 1 "Signalling requested" ;
VAL_ 941 EpbRearLeftForceEstimate 0 "Zero force" 1 "Medium force" 2 "Maximum force" 3 "Invalid" ;
VAL_ 941 EpbRearRightForceEstimate 0 "Zero force" 1 "Medium force" 2 "Maximum force" 3 "Invalid" ;
VAL_ 973 BrakingInProgress 0 "No braking" 1 "Braking in progress (driver action)" 2 "Dynamic braking in progress" 3 "Braking in progress (controlled action)" ;
VAL_ 973 MasterCylinderPressure 4095 "Not_available" ;
VAL_ 973 EasymoveRestartInhibitRequest 3 "No restart inhibition request" 5 "Restart inhibition requested for EPB locking" 6 "Restart inhibition requested for EPB releasing" ;
VAL_ 973 BrakePedalSwitch3Fault 0 "Main brake switch OK" 1 "Main brake switch faulty" ;
VAL_ 973 BrakePedalSwitch3 0 "Brake pedal released" 1 "Brake pedal pressed" ;
VAL_ 973 MuSplitSituation 0 "Normal situation" 1 "Mu-split braking" ;
VAL_ 973 YawRate 32767 "Not_available" ;
VAL_ 973 LateralAcceleration 32767 "Not_available" ;
VAL_ 974 HvacAirflow 511 "Not_available" ;
VAL_ 974 EvaporatorProbeTemp 2047 "Not_available" ;
VAL_ 974 EvaporatorTempSetpoint 31 "Not_available" ;
VAL_ 974 HeaterWaterTempSetpoint 255 "Not_available" ;
VAL_ 974 HeaterOutletWaterTemp 255 "Not_available" ;
VAL_ 974 EvaporatorUpstreamAirTemp 255 "Not_available" ;
VAL_ 974 AcEcoModePriorityRequest 0 "No prioritization request" 1 "Prioritization request" ;
VAL_ 974 FanLoadShedding 0 "No power-shedding request" 1 "Power-shedding level request" ;
VAL_ 974 DeicingAuthorization 0 "not authorization" 1 "Authorization" ;
VAL_ 974 VisibilityRequest 0 "No visibility request" 1 "Visibility request" ;
VAL_ 1010 DeadmanButtonRequestStatusBsi 0 "No request" 1 "Requested" 2 "Unconfigured" 3 "Fault" ;
VAL_ 1010 LkaLpaSteeringSelection 0 "LKA function" 1 "LPA function" ;
VAL_ 1010 LkaTorqueFactorRequest 127 "Not_available" ;
VAL_ 1010 LkaRightCorrectionActivation 0 "No activation" 1 "Activation" ;
VAL_ 1010 LkaLeftCorrectionActivation 0 "No activation" 1 "Activation" ;
VAL_ 1010 LkaGlobalState 0 "Unavailable" 1 "Not selected" 2 "Selected" 3 "Allowed" 4 "Active" 5 "Fault" 6 "Collision risk" ;
VAL_ 1010 LkaRequestedYawRate 1023 "Not_available" ;
VAL_ 1010 AcBlowerSpeed 127 "Not_available" ;
VAL_ 1010 AsrDisconnectRequest 0 "No ASR disconnection requested" 1 "ASR disconnection requested" ;
VAL_ 1010 DemistingRequest 0 "No request" 1 "Requested" ;
VAL_ 1010 AbsEspPowerCutRequest 0 "No request" 1 "Power cut request" ;
VAL_ 1010 PowerSteeringCutRequest 0 "No request" 1 "Power cut request" ;
VAL_ 1010 EasymovePowerCutRequest 0 "No request" 1 "Power cut request" ;
VAL_ 1010 SuspensionPowerCutRequest 0 "No request" 1 "Power cut request" ;
VAL_ 1010 ZevModeProhibition 0 "ZEV authorized" 1 "ZEV forbidden" ;
VAL_ 1010 BrakeModeConfiguration 0 "No brake mode" 1 "Brake mode" ;
VAL_ 1010 TrailerDetection 0 "No trailer" 1 "Trailer presence" ;

SG_MUL_VAL_ 820 CellVoltage025 CellGroup 6-6;
SG_MUL_VAL_ 820 CellVoltage045 CellGroup 11-11;
SG_MUL_VAL_ 820 CellVoltage033 CellGroup 8-8;
SG_MUL_VAL_ 820 CellVoltage097 CellGroup 24-24;
SG_MUL_VAL_ 820 CellVoltage101 CellGroup 25-25;
SG_MUL_VAL_ 820 CellVoltage077 CellGroup 19-19;
SG_MUL_VAL_ 820 CellVoltage089 CellGroup 22-22;
SG_MUL_VAL_ 820 CellVoltage001 CellGroup 0-0;
SG_MUL_VAL_ 820 CellVoltage093 CellGroup 23-23;
SG_MUL_VAL_ 820 CellVoltage081 CellGroup 20-20;
SG_MUL_VAL_ 820 CellVoltage049 CellGroup 12-12;
SG_MUL_VAL_ 820 CellVoltage009 CellGroup 2-2;
SG_MUL_VAL_ 820 CellVoltage013 CellGroup 3-3;
SG_MUL_VAL_ 820 CellVoltage037 CellGroup 9-9;
SG_MUL_VAL_ 820 CellVoltage053 CellGroup 13-13;
SG_MUL_VAL_ 820 CellVoltage005 CellGroup 1-1;
SG_MUL_VAL_ 820 CellVoltage085 CellGroup 21-21;
SG_MUL_VAL_ 820 CellVoltage057 CellGroup 14-14;
SG_MUL_VAL_ 820 CellVoltage061 CellGroup 15-15;
SG_MUL_VAL_ 820 CellVoltage073 CellGroup 18-18;
SG_MUL_VAL_ 820 CellVoltage017 CellGroup 4-4;
SG_MUL_VAL_ 820 CellVoltage065 CellGroup 16-16;
SG_MUL_VAL_ 820 CellVoltage105 CellGroup 26-26;
SG_MUL_VAL_ 820 CellVoltage069 CellGroup 17-17;
SG_MUL_VAL_ 820 CellVoltage021 CellGroup 5-5;
SG_MUL_VAL_ 820 CellVoltage041 CellGroup 10-10;
SG_MUL_VAL_ 820 CellVoltage029 CellGroup 7-7;
SG_MUL_VAL_ 820 RawByte2_Mux27_28_29_30_31 CellGroup 27-31;
SG_MUL_VAL_ 820 RawByte3_Mux27_28_29_30_31 CellGroup 27-31;
SG_MUL_VAL_ 820 CellVoltage026 CellGroup 6-6;
SG_MUL_VAL_ 820 CellVoltage046 CellGroup 11-11;
SG_MUL_VAL_ 820 CellVoltage098 CellGroup 24-24;
SG_MUL_VAL_ 820 CellVoltage102 CellGroup 25-25;
SG_MUL_VAL_ 820 CellVoltage078 CellGroup 19-19;
SG_MUL_VAL_ 820 CellVoltage002 CellGroup 0-0;
SG_MUL_VAL_ 820 CellVoltage034 CellGroup 8-8;
SG_MUL_VAL_ 820 CellVoltage094 CellGroup 23-23;
SG_MUL_VAL_ 820 CellVoltage082 CellGroup 20-20;
SG_MUL_VAL_ 820 CellVoltage010 CellGroup 2-2;
SG_MUL_VAL_ 820 CellVoltage038 CellGroup 9-9;
SG_MUL_VAL_ 820 CellVoltage050 CellGroup 12-12;
SG_MUL_VAL_ 820 CellVoltage054 CellGroup 13-13;
SG_MUL_VAL_ 820 CellVoltage006 CellGroup 1-1;
SG_MUL_VAL_ 820 CellVoltage086 CellGroup 21-21;
SG_MUL_VAL_ 820 CellVoltage058 CellGroup 14-14;
SG_MUL_VAL_ 820 CellVoltage062 CellGroup 15-15;
SG_MUL_VAL_ 820 CellVoltage070 CellGroup 17-17;
SG_MUL_VAL_ 820 CellVoltage074 CellGroup 18-18;
SG_MUL_VAL_ 820 CellVoltage014 CellGroup 3-3;
SG_MUL_VAL_ 820 CellVoltage066 CellGroup 16-16;
SG_MUL_VAL_ 820 CellVoltage106 CellGroup 26-26;
SG_MUL_VAL_ 820 CellVoltage090 CellGroup 22-22;
SG_MUL_VAL_ 820 CellVoltage018 CellGroup 4-4;
SG_MUL_VAL_ 820 CellVoltage022 CellGroup 5-5;
SG_MUL_VAL_ 820 CellVoltage042 CellGroup 10-10;
SG_MUL_VAL_ 820 CellVoltage030 CellGroup 7-7;
SG_MUL_VAL_ 820 RawByte4_Mux27_28_29_30_31 CellGroup 27-31;
SG_MUL_VAL_ 820 RawByte5_Mux27_28_29_30_31 CellGroup 27-31;
SG_MUL_VAL_ 820 CellVoltage027 CellGroup 6-6;
SG_MUL_VAL_ 820 CellVoltage047 CellGroup 11-11;
SG_MUL_VAL_ 820 CellVoltage095 CellGroup 23-23;
SG_MUL_VAL_ 820 CellVoltage099 CellGroup 24-24;
SG_MUL_VAL_ 820 CellVoltage103 CellGroup 25-25;
SG_MUL_VAL_ 820 CellVoltage075 CellGroup 18-18;
SG_MUL_VAL_ 820 CellVoltage023 CellGroup 5-5;
SG_MUL_VAL_ 820 CellVoltage055 CellGroup 13-13;
SG_MUL_VAL_ 820 CellVoltage003 CellGroup 0-0;
SG_MUL_VAL_ 820 CellVoltage035 CellGroup 8-8;
SG_MUL_VAL_ 820 CellVoltage079 CellGroup 19-19;
SG_MUL_VAL_ 820 CellVoltage011 CellGroup 2-2;
SG_MUL_VAL_ 820 CellVoltage039 CellGroup 9-9;
SG_MUL_VAL_ 820 CellVoltage051 CellGroup 12-12;
SG_MUL_VAL_ 820 CellVoltage007 CellGroup 1-1;
SG_MUL_VAL_ 820 CellVoltage083 CellGroup 20-20;
SG_MUL_VAL_ 820 CellVoltage059 CellGroup 14-14;
SG_MUL_VAL_ 820 CellVoltage071 CellGroup 17-17;
SG_MUL_VAL_ 820 CellVoltage015 CellGroup 3-3;
SG_MUL_VAL_ 820 CellVoltage063 CellGroup 15-15;
SG_MUL_VAL_ 820 CellVoltage067 CellGroup 16-16;
SG_MUL_VAL_ 820 CellVoltage107 CellGroup 26-26;
SG_MUL_VAL_ 820 CellVoltage087 CellGroup 21-21;
SG_MUL_VAL_ 820 CellVoltage019 CellGroup 4-4;
SG_MUL_VAL_ 820 CellVoltage091 CellGroup 22-22;
SG_MUL_VAL_ 820 CellVoltage043 CellGroup 10-10;
SG_MUL_VAL_ 820 CellVoltage031 CellGroup 7-7;
SG_MUL_VAL_ 820 RawByte6_Mux27_28_29_30_31 CellGroup 27-31;
SG_MUL_VAL_ 820 RawByte7_Mux27_28_29_30_31 CellGroup 27-31;
SG_MUL_VAL_ 820 CellVoltage024 CellGroup 5-5;
SG_MUL_VAL_ 820 CellVoltage028 CellGroup 6-6;
SG_MUL_VAL_ 820 CellVoltage032 CellGroup 7-7;
SG_MUL_VAL_ 820 CellVoltage096 CellGroup 23-23;
SG_MUL_VAL_ 820 CellVoltage100 CellGroup 24-24;
SG_MUL_VAL_ 820 CellVoltage076 CellGroup 18-18;
SG_MUL_VAL_ 820 CellVoltage036 CellGroup 8-8;
SG_MUL_VAL_ 820 CellVoltage080 CellGroup 19-19;
SG_MUL_VAL_ 820 CellVoltage048 CellGroup 11-11;
SG_MUL_VAL_ 820 CellVoltage008 CellGroup 1-1;
SG_MUL_VAL_ 820 CellVoltage012 CellGroup 2-2;
SG_MUL_VAL_ 820 CellVoltage052 CellGroup 12-12;
SG_MUL_VAL_ 820 CellVoltage004 CellGroup 0-0;
SG_MUL_VAL_ 820 CellVoltage084 CellGroup 20-20;
SG_MUL_VAL_ 820 CellVoltage056 CellGroup 13-13;
SG_MUL_VAL_ 820 CellVoltage060 CellGroup 14-14;
SG_MUL_VAL_ 820 CellVoltage072 CellGroup 17-17;
SG_MUL_VAL_ 820 CellVoltage016 CellGroup 3-3;
SG_MUL_VAL_ 820 CellVoltage064 CellGroup 15-15;
SG_MUL_VAL_ 820 CellVoltage068 CellGroup 16-16;
SG_MUL_VAL_ 820 CellVoltage104 CellGroup 25-25;
SG_MUL_VAL_ 820 CellVoltage108 CellGroup 26-26;
SG_MUL_VAL_ 820 CellVoltage088 CellGroup 21-21;
SG_MUL_VAL_ 820 CellVoltage020 CellGroup 4-4;
SG_MUL_VAL_ 820 CellVoltage092 CellGroup 22-22;
SG_MUL_VAL_ 820 CellVoltage040 CellGroup 9-9;
SG_MUL_VAL_ 820 CellVoltage044 CellGroup 10-10;
SG_MUL_VAL_ 820 RawByte8_Mux27_28_29_30_31 CellGroup 27-31;
